VERSION ""

NS_ :

BS_:

BU_: FUSION ABM EPS ESC eBST OCS DataCenter RWS

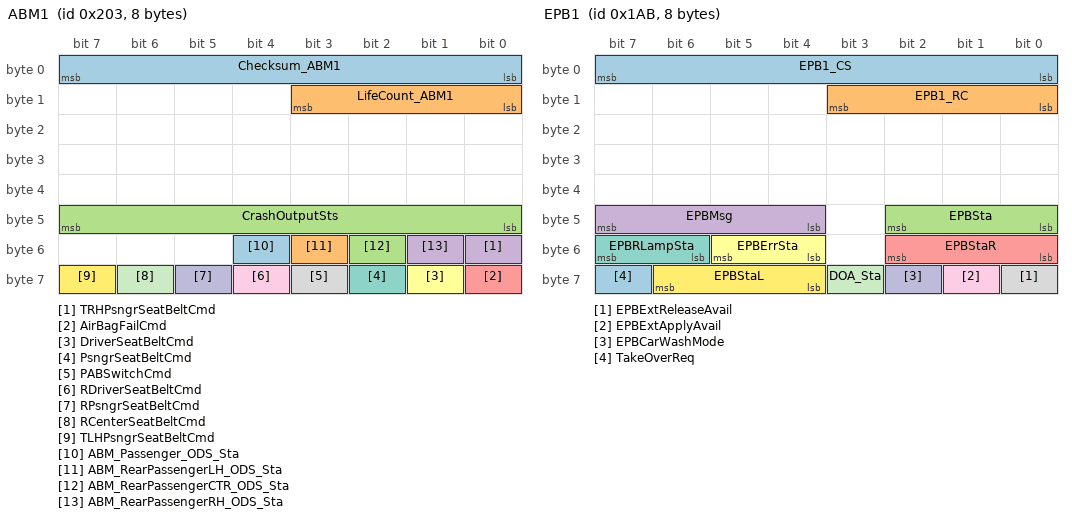
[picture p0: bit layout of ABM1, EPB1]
BO_ 515 ABM1: 8 ABM
 SG_ Checksum_ABM1 : 7|8@0+ (1,0) [0|255] "" FUSION
 SG_ LifeCount_ABM1 : 11|4@0+ (1,0) [0|14] "" FUSION
 SG_ CrashOutputSts : 47|8@0+ (1,0) [0|255] "" FUSION
 SG_ TRHPsngrSeatBeltCmd : 48|1@0+ (1,0) [0|1] "" FUSION
 SG_ AirBagFailCmd : 56|1@0+ (1,0) [0|1] "" FUSION
 SG_ DriverSeatBeltCmd : 57|1@0+ (1,0) [0|1] "" FUSION
 SG_ PsngrSeatBeltCmd : 58|1@0+ (1,0) [0|1] "" FUSION
 SG_ PABSwitchCmd : 59|1@0+ (1,0) [0|1] "" FUSION
 SG_ RDriverSeatBeltCmd : 60|1@0+ (1,0) [0|1] "" FUSION
 SG_ RPsngrSeatBeltCmd : 61|1@0+ (1,0) [0|1] "" FUSION
 SG_ RCenterSeatBeltCmd : 62|1@0+ (1,0) [0|1] "" FUSION
 SG_ TLHPsngrSeatBeltCmd : 63|1@0+ (1,0) [0|1] "" FUSION
 SG_ ABM_Passenger_ODS_Sta : 52|1@0+ (1,0) [0|1] "" FUSION
 SG_ ABM_RearPassengerLH_ODS_Sta : 51|1@0+ (1,0) [0|1] "" FUSION
 SG_ ABM_RearPassengerCTR_ODS_Sta : 50|1@0+ (1,0) [0|1] "" FUSION
 SG_ ABM_RearPassengerRH_ODS_Sta : 49|1@0+ (1,0) [0|1] "" FUSION

BO_ 1585 DiagRespFromABM: 8 ABM
 SG_ DiagRespFromABM : 7|64@0+ (1,0) [0|0] "" FUSION

BO_ 391 EPS1: 16 EPS
 SG_ EPS_CS : 7|8@0+ (1,0) [0|255] "" FUSION
 SG_ EPS_RC : 11|4@0+ (1,0) [0|14] "" FUSION
 SG_ EPS_TOI_Dis_R : 16|4@0+ (1,0) [0|15] "" FUSION
 SG_ DriIntend : 18|2@0+ (1,0) [0|2] "" FUSION
 SG_ EPS_AOI_Control : 20|2@0+ (1,0) [0|3] "" FUSION
 SG_ EPS_TOI_Activation : 21|1@0+ (1,0) [0|1] "" FUSION
 SG_ EPS_TOI_Unavailable : 22|1@0+ (1,0) [0|1] "" FUSION
 SG_ EPS_TOI_Fault : 23|1@0+ (1,0) [0|1] "" FUSION
 SG_ SAS_V : 24|1@0+ (1,0) [0|1] "" FUSION
 SG_ EPS_AOI_Dis_R : 28|4@0+ (1,0) [0|15] "" FUSION
 SG_ SAS_Speed : 39|8@0+ (4,0) [0|1020] "Deg/s" FUSION
 SG_ SAS_Angle : 47|16@0+ (0.1,-900) [-900|900] "Deg" FUSION
 SG_ Steering_Torque : 58|11@0+ (0.01,-10) [-10|10] "Nm" FUSION
 SG_ EPS_Pwr_Limit_V : 59|1@0+ (1,0) [0|1] "" FUSION
 SG_ Steering_Torque_V : 60|1@0+ (1,0) [0|1] "" FUSION
 SG_ EPS_Pwr_Consumpt_V : 61|1@0+ (1,0) [0|1] "" FUSION
 SG_ SAS_Speed_Valid : 62|1@0+ (1,0) [0|1] "" FUSION
 SG_ SAS_CAL : 63|1@0+ (1,0) [0|1] "" FUSION
 SG_ EPS_VOL : 79|8@0+ (0.1,0) [0|25.5] "V" FUSION
 SG_ EPS_Temp : 87|8@0+ (1,-100) [-100|155] "Deg^C" FUSION
 SG_ EPS_Pwr_Limit : 88|9@0+ (0.5,0) [0|135] "A" FUSION
 SG_ EPS_LDW_Activation : 90|2@0+ (1,0) [0|3] "" FUSION
 SG_ EPS_LDW_Unavailable : 91|1@0+ (1,0) [0|1] "" FUSION
 SG_ EPS_VOL_V : 92|1@0+ (1,0) [0|1] "" FUSION
 SG_ EPS_Temp_V : 93|1@0+ (1,0) [0|1] "" FUSION
 SG_ EpasFailed : 95|2@0+ (1,0) [0|2] "" FUSION
 SG_ EPS_Pwr_Consumpt : 104|9@0+ (0.5,0) [0|135] "A" FUSION
 SG_ EPS_ESABoostOut_Trq : 111|6@0+ (0.1,-3) [-3|3] "" FUSION
 SG_ EPS_ESAInpBoost_Sta : 105|1@0+ (1,0) [0|1] "" FUSION
 SG_ EPS_DMSMode_Sta : 123|4@0+ (1,0) [0|15] "" FUSION

BO_ 338 ESC1: 32 ESC
 SG_ ESC1_CS : 7|8@0+ (1,0) [0|255] "" FUSION
 SG_ ESC1_RC : 11|4@0+ (1,0) [0|14] "" FUSION
 SG_ VehSpeed : 23|12@0+ (0.125,0) [0|255.875] "km/h" FUSION
 SG_ RF_WhlRotDir : 25|2@0+ (1,0) [0|3] "" FUSION
 SG_ RF_PulseCount_V : 26|1@0+ (1,0) [0|1] "" FUSION
 SG_ Fr_PTCS_Active : 27|1@0+ (1,0) [0|1] "" FUSION
 SG_ FrntAxlTrqReq_Drv : 39|16@0+ (0.5,-5300) [0|5300] "Nm" FUSION
 SG_ RearAxlTrqReq_Drv : 55|16@0+ (0.5,-5300) [0|5300] "Nm" FUSION
 SG_ RF_PulseCount : 71|8@0+ (1,0) [0|255] "" FUSION
 SG_ RF_RawWhlSpeed : 79|12@0+ (0.0625,0) [0|255.9375] "km/h" FUSION
 SG_ LF_WhlRotDir : 81|2@0+ (1,0) [0|3] "" FUSION
 SG_ LF_PulseCount_V : 82|1@0+ (1,0) [0|1] "" FUSION
 SG_ RF_RawWhlSpeed_V : 83|1@0+ (1,0) [0|1] "" FUSION
 SG_ LF_PulseCount : 95|8@0+ (1,0) [0|255] "" FUSION
 SG_ LF_RawWhlSpeed : 103|12@0+ (0.0625,0) [0|255.9375] "km/h" FUSION
 SG_ RR_WhlRotDir : 105|2@0+ (1,0) [0|3] "" FUSION
 SG_ LF_RawWhlSpeed_V : 106|1@0+ (1,0) [0|1] "" FUSION
 SG_ RR_PulseCount_V : 107|1@0+ (1,0) [0|1] "" FUSION
 SG_ RR_PulseCount : 119|8@0+ (1,0) [0|255] "" FUSION
 SG_ RR_RawWhlSpeed : 123|12@0+ (0.0625,0) [0|255.9375] "km/h" FUSION
 SG_ LR_WhlRotDir : 125|2@0+ (1,0) [0|3] "" FUSION
 SG_ RR_RawWhlSpeed_V : 126|1@0+ (1,0) [0|1] "" FUSION
 SG_ LR_PulseCount_V : 127|1@0+ (1,0) [0|1] "" FUSION
 SG_ LR_PulseCount : 143|8@0+ (1,0) [0|255] "" FUSION
 SG_ LR_RawWhlSpeed : 147|12@0+ (0.0625,0) [0|255.9375] "km/h" FUSION
 SG_ ESC_OFF_Status : 149|2@0+ (1,0) [0|2] "" FUSION
 SG_ ESC_BeepReq : 150|1@0+ (1,0) [0|1] "" FUSION
 SG_ LR_RawWhlSpeed_V : 151|1@0+ (1,0) [0|1] "" FUSION
 SG_ SystemVoltage : 167|8@0+ (0.08,0) [0|20.32] "V" FUSION
 SG_ TCS_Failed : 168|1@0+ (1,0) [0|1] "" FUSION
 SG_ ESC_Failed : 169|1@0+ (1,0) [0|1] "" FUSION
 SG_ HBB_Failed : 170|1@0+ (1,0) [0|1] "" FUSION
 SG_ PBA_Failed : 171|1@0+ (1,0) [0|1] "" FUSION
 SG_ HSA_Failed : 172|1@0+ (1,0) [0|1] "" FUSION
 SG_ AVH_Failed : 173|1@0+ (1,0) [0|1] "" FUSION
 SG_ HDD_Failed : 174|1@0+ (1,0) [0|1] "" FUSION
 SG_ Rr_PTCS_Active : 175|1@0+ (1,0) [0|1] "" FUSION
 SG_ HSA_Active : 176|1@0+ (1,0) [0|1] "" FUSION
 SG_ AVH_Active : 177|1@0+ (1,0) [0|1] "" FUSION
 SG_ Amber_WnlmpSta : 178|1@0+ (1,0) [0|1] "" FUSION
 SG_ BTCS_Active : 179|1@0+ (1,0) [0|1] "" FUSION
 SG_ ESS_Active : 180|1@0+ (1,0) [0|1] "" FUSION
 SG_ HDD_Active : 181|1@0+ (1,0) [0|1] "" FUSION
 SG_ EBD_Failed : 182|1@0+ (1,0) [0|1] "" FUSION
 SG_ ABS_Failed : 183|1@0+ (1,0) [0|1] "" FUSION
 SG_ ESC_WnlmpSta : 185|2@0+ (1,0) [0|2] "" FUSION
 SG_ EBD_Active : 186|1@0+ (1,0) [0|1] "" FUSION
 SG_ ABS_Active : 187|1@0+ (1,0) [0|1] "" FUSION
 SG_ TCS_Active : 188|1@0+ (1,0) [0|1] "" FUSION
 SG_ ESC_Active : 189|1@0+ (1,0) [0|1] "" FUSION
 SG_ HBB_Active : 190|1@0+ (1,0) [0|1] "" FUSION
 SG_ PBA_Active : 191|1@0+ (1,0) [0|1] "" FUSION
 SG_ GRADE : 199|8@0+ (0.354331,-45) [-45|45] "Deg" FUSION
 SG_ Red_WnlmpSta : 205|1@0+ (1,0) [0|1] "" FUSION
 SG_ ABS_WnlmpSta : 206|1@0+ (1,0) [0|1] "" FUSION
 SG_ ESC_Off_lmpSta : 207|1@0+ (1,0) [0|1] "" FUSION
 SG_ ESC_EstVehSpd : 203|12@0+ (0.0625,0) [0|255.9375] "km/h" FUSION
 SG_ ESC_TSA_Active : 223|1@0+ (1,0) [0|1] "" FUSION
 SG_ ESC_EstVehSpd_V : 204|1@0+ (1,0) [0|1] "" FUSION

BO_ 421 ESC5: 20 ESC
 SG_ ESC5_CS : 7|8@0+ (1,0) [0|255] "" FUSION
 SG_ ESC5_RC : 11|4@0+ (1,0) [0|14] "" FUSION
 SG_ BrkDiscTempSta : 16|1@0+ (1,0) [0|1] "" FUSION
 SG_ ACCAvail : 17|1@0+ (1,0) [0|1] "" FUSION
 SG_ YawRate_V : 18|1@0+ (1,0) [0|1] "" FUSION
 SG_ LatAccel_V : 19|1@0+ (1,0) [0|1] "" FUSION
 SG_ LongAccel_V : 20|1@0+ (1,0) [0|1] "" FUSION
 SG_ MCPressure_V : 21|1@0+ (1,0) [0|1] "" FUSION
 SG_ BrkSw_Sta : 22|1@0+ (1,0) [0|1] "" FUSION
 SG_ BrkSw_V : 23|1@0+ (1,0) [0|1] "" FUSION
 SG_ MCPressure : 27|12@0+ (0.1,-9.7) [-9.7|195] "bar" FUSION
 SG_ ESC_ADAS_Sta : 30|3@0+ (1,0) [0|6] "" FUSION
 SG_ LongAccel : 47|8@0+ (0.01,-1.27) [-1.27|1.27] "G's" FUSION
 SG_ LatAccel : 55|8@0+ (0.01,-1.27) [-1.27|1.27] "G's" FUSION
 SG_ YawRate : 63|16@0+ (0.1,-100) [-100|100] "Deg/s" FUSION
 SG_ ESC_Standstill : 72|1@0+ (1,0) [0|1] "" FUSION
 SG_ DecErrSta : 73|1@0+ (1,0) [0|1] "" FUSION
 SG_ ActBrkLamp_Sta : 74|1@0+ (1,0) [0|1] "" FUSION
 SG_ AEBAvail : 75|1@0+ (1,0) [0|1] "" FUSION
 SG_ BrkPedalPos_Sta : 76|1@0+ (1,0) [0|1] "" FUSION
 SG_ ESC_APS_Sta : 79|3@0+ (1,0) [0|5] "" FUSION
 SG_ Meter_Ind_VehSpeed : 87|12@0+ (0.125,0) [0|300] "km/h" FUSION
 SG_ Fr_RBC_Active : 88|1@0+ (1,0) [0|1] "" FUSION
 SG_ Rr_RBC_Active : 89|1@0+ (1,0) [0|1] "" FUSION
 SG_ RDC_Active : 91|2@0+ (1,0) [0|2] "" FUSION
 SG_ BrkPedalPos : 103|8@0+ (0.4,0) [0|100] "%" FUSION
 SG_ RearAxlTrqReq_Brk : 111|16@0+ (0.5,-5300) [-5300|0] "Nm" FUSION
 SG_ FrntAxlTrqReq_Brk : 127|16@0+ (0.5,-5300) [-5300|0] "Nm" FUSION
 SG_ ESC_DriverBrkOverride : 31|1@0+ (1,0) [0|1] "" FUSION

BO_ 427 EPB1: 8 ESC
 SG_ EPB1_CS : 7|8@0+ (1,0) [0|255] "" FUSION
 SG_ EPB1_RC : 11|4@0+ (1,0) [0|14] "" FUSION
 SG_ EPBSta : 42|3@0+ (1,0) [0|4] "" FUSION
 SG_ EPBMsg : 47|4@0+ (1,0) [0|12] "" FUSION
 SG_ EPBStaR : 50|3@0+ (1,0) [0|7] "" FUSION
 SG_ EPBErrSta : 53|2@0+ (1,0) [0|2] "" FUSION
 SG_ EPBRLampSta : 55|2@0+ (1,0) [0|2] "" FUSION
 SG_ EPBExtReleaseAvail : 56|1@0+ (1,0) [0|1] "" FUSION
 SG_ EPBExtApplyAvail : 57|1@0+ (1,0) [0|1] "" FUSION
 SG_ EPBCarWashMode : 58|1@0+ (1,0) [0|1] "" FUSION
 SG_ DOA_Sta : 59|1@0+ (1,0) [0|1] "" FUSION
 SG_ EPBStaL : 62|3@0+ (1,0) [0|7] "" FUSION
 SG_ TakeOverReq : 63|1@0+ (1,0) [0|1] "" FUSION

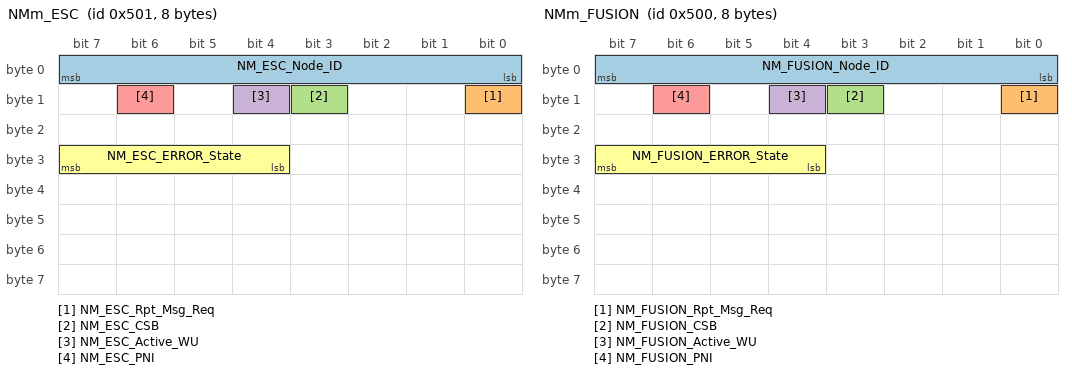
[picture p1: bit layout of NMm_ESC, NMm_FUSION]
BO_ 1281 NMm_ESC: 8 ESC
 SG_ NM_ESC_Node_ID : 7|8@0+ (1,0) [0|127] "" FUSION
 SG_ NM_ESC_Rpt_Msg_Req : 8|1@0+ (1,0) [0|1] "" FUSION
 SG_ NM_ESC_CSB : 11|1@0+ (1,0) [0|1] "" FUSION
 SG_ NM_ESC_Active_WU : 12|1@0+ (1,0) [0|1] "" FUSION
 SG_ NM_ESC_PNI : 14|1@0+ (1,0) [0|1] "" FUSION
 SG_ NM_ESC_ERROR_State : 31|4@0+ (1,0) [0|8] "" FUSION

BO_ 278 FD1_VCU1: 12 FUSION
 SG_ PrkReqValid : 4|1@0+ (1,0) [0|1] "" ESC
 SG_ P_Button_Sta : 7|2@0+ (1,0) [0|3] "" ESC
 SG_ CC_Crl_Sta : 28|3@0+ (1,0) [0|7] "" Vector__XXX
 SG_ MSA_Crl_Sta : 31|3@0+ (1,0) [0|7] "" Vector__XXX
 SG_ ShiftGearPosn : 38|3@0+ (1,0) [0|7] "" ABM,ESC,eBST
 SG_ PrkReq : 45|1@0+ (1,0) [0|1] "" ESC
 SG_ XWDMode : 57|2@0+ (1,0) [0|2] "" ESC
 SG_ LVPwrSta : 58|1@0+ (1,0) [0|1] "" Vector__XXX
 SG_ HVPwrSta : 59|1@0+ (1,0) [0|1] "" Vector__XXX
 SG_ PwrSta : 63|3@0+ (1,0) [0|7] "" ABM,EPS,ESC,eBST,OCS
 SG_ Eng_AGSCloseSta : 65|1@0+ (1,0) [0|1] "" Vector__XXX
 SG_ Eng_PwrLockSta : 67|2@0+ (1,0) [0|2] "" Vector__XXX
 SG_ Eng_CoastDwSta : 69|2@0+ (1,0) [0|2] "" Vector__XXX
 SG_ Eng_ActvDmpDisabSta : 71|2@0+ (1,0) [0|2] "" Vector__XXX
 SG_ VehMalfunLevel : 74|3@0+ (1,0) [0|5] "" Vector__XXX

BO_ 340 FD1_VCU2: 16 FUSION
 SG_ CS_VCU2_CAN1 : 7|8@0+ (1,0) [0|255] "" Vector__XXX
 SG_ RC_VCU2_CAN1 : 11|4@0+ (1,0) [0|14] "" Vector__XXX
 SG_ Fr_DriverTq : 23|16@0+ (0.5,-5300) [-5300|5300] "Nm" ESC
 SG_ Rr_DriverTq : 39|16@0+ (0.5,-5300) [-5300|5300] "Nm" ESC
 SG_ AccPedal_Override : 54|1@0+ (1,0) [0|1] "" Vector__XXX
 SG_ ACC_CtrlAvail : 55|1@0+ (1,0) [0|1] "" Vector__XXX
 SG_ VehActPwr : 87|24@0+ (1,-600000) [-600000|600000] "W" Vector__XXX
 SG_ DriverTq : 111|16@0+ (1,-4300) [-4300|4300] "Nm" Vector__XXX
 SG_ ActAPSPosn : 127|8@0+ (0.394,0) [0|100.076] "%" ABM,ESC

BO_ 1280 NMm_FUSION: 8 FUSION
 SG_ NM_FUSION_Node_ID : 7|8@0+ (1,0) [0|127] "" ESC,eBST
 SG_ NM_FUSION_Rpt_Msg_Req : 8|1@0+ (1,0) [0|1] "" ESC,eBST
 SG_ NM_FUSION_CSB : 11|1@0+ (1,0) [0|1] "" ESC,eBST
 SG_ NM_FUSION_Active_WU : 12|1@0+ (1,0) [0|1] "" ESC,eBST
 SG_ NM_FUSION_PNI : 14|1@0+ (1,0) [0|1] "" ESC,eBST
 SG_ NM_FUSION_ERROR_State : 31|4@0+ (1,0) [0|8] "" ESC,eBST

BO_ 1713 DiagPhysReqToABM: 8 FUSION
 SG_ DiagPhysReqToABM : 7|64@0+ (1,0) [0|0] "" ABM

BO_ 2000 DiagFuncReqFT: 8 FUSION
 SG_ DiagFuncReqFT : 7|64@0+ (1,0) [0|0] "" ABM,EPS,ESC,eBST

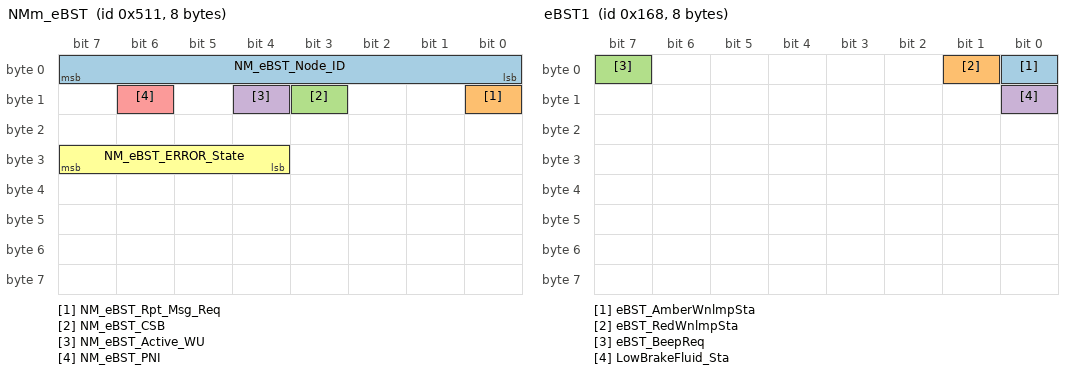
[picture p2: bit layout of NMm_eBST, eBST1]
BO_ 1297 NMm_eBST: 8 eBST
 SG_ NM_eBST_Node_ID : 7|8@0+ (1,0) [0|127] "" FUSION
 SG_ NM_eBST_Rpt_Msg_Req : 8|1@0+ (1,0) [0|1] "" FUSION
 SG_ NM_eBST_CSB : 11|1@0+ (1,0) [0|1] "" FUSION
 SG_ NM_eBST_Active_WU : 12|1@0+ (1,0) [0|1] "" FUSION
 SG_ NM_eBST_PNI : 14|1@0+ (1,0) [0|1] "" FUSION
 SG_ NM_eBST_ERROR_State : 31|4@0+ (1,0) [0|8] "" FUSION

BO_ 1168 IVI1: 20 FUSION
 SG_ VehACModReq : 23|3@0+ (1,0) [0|7] "" Vector__XXX
 SG_ FCP_FrEvt_BtnACMaxReq : 20|1@0+ (1,0) [0|1] "" Vector__XXX
 SG_ FCP_FrEvt_BtnACReq : 19|1@0+ (1,0) [0|1] "" Vector__XXX
 SG_ FCP_FrEvt_BtnAutoReq : 18|1@0+ (1,0) [0|1] "" Vector__XXX
 SG_ FCP_MidEvt_BtnAutoReq : 17|1@0+ (1,0) [0|1] "" Vector__XXX
 SG_ FCP_FrEvt_BtnSyncReq : 16|1@0+ (1,0) [0|1] "" Vector__XXX
 SG_ OTA_DL_Req : 31|1@0+ (1,0) [0|1] "" Vector__XXX
 SG_ OTA_SuspendDL_Req : 30|1@0+ (1,0) [0|1] "" Vector__XXX
 SG_ OTA_UpdStart_Req : 29|1@0+ (1,0) [0|1] "" Vector__XXX
 SG_ IVI_OTA_Upd_Sta : 28|2@0+ (1,0) [0|3] "" Vector__XXX
 SG_ OTA_CancelDL_Req : 26|1@0+ (1,0) [0|1] "" Vector__XXX
 SG_ SmartEco_Mode_SW : 25|1@0+ (1,0) [0|1] "" Vector__XXX
 SG_ LINKtoDrive : 24|1@0+ (1,0) [0|1] "" Vector__XXX
 SG_ Upd_Countdown_Skip : 39|1@0+ (1,0) [0|1] "" Vector__XXX
 SG_ Upd_Countdown_Cancel : 38|1@0+ (1,0) [0|1] "" Vector__XXX
 SG_ AmbLightColorSet : 46|7@0+ (1,0) [0|127] "" Vector__XXX
 SG_ Sched_OTA_wake : 47|1@0+ (1,0) [0|1] "" Vector__XXX
 SG_ UserSet : 71|3@0+ (1,0) [0|7] "" Vector__XXX
 SG_ AmbLightBrightnessSet : 54|7@0+ (1,0) [0|127] "" Vector__XXX
 SG_ Sched_Chg_Day_Set : 62|1@0+ (1,0) [0|1] "" Vector__XXX
 SG_ Re_Radio_Sta : 63|1@0+ (1,0) [0|1] "" Vector__XXX
 SG_ Sched_Chg_St_Time_Min : 61|6@0+ (1,0) [0|59] "MINUTE" Vector__XXX
 SG_ A2B_Node_sta : 55|1@0+ (1,0) [0|1] "" Vector__XXX
 SG_ Sched_Chg_St_Time_HR : 68|5@0+ (1,0) [0|23] "HOUR" Vector__XXX
 SG_ IVI_Located_STA : 79|2@0+ (1,0) [0|3] "" Vector__XXX
 SG_ Sched_Chg_End_Time_Min : 77|6@0+ (1,0) [0|59] "MINUTE" Vector__XXX
 SG_ OTA_CompNTFY_Pres : 86|1@0+ (1,0) [0|1] "" Vector__XXX
 SG_ BrkAbn_GoReady_SW : 85|1@0+ (1,0) [0|1] "" Vector__XXX
 SG_ Sched_Chg_End_Time_HR : 84|5@0+ (1,0) [0|23] "HOUR" Vector__XXX
 SG_ IVI_Time_Check : 95|8@0+ (1,0) [0|255] "" Vector__XXX
 SG_ PW_CONTINUE_USE : 103|1@0+ (1,0) [0|1] "" Vector__XXX
 SG_ PW_CLOSE_IMD : 102|1@0+ (1,0) [0|1] "" Vector__XXX
 SG_ IVI_Time_Second : 101|6@0+ (1,0) [0|63] "SECOND" ABM,EPS,ESC,eBST
 SG_ IVI_Time_Minute : 109|6@0+ (1,0) [0|63] "MINUTE" ABM,EPS,ESC,eBST
 SG_ IVI_Time_Day : 116|5@0+ (1,0) [0|31] "DAY" ABM,EPS,ESC,eBST
 SG_ IVI_Time_Hour : 124|5@0+ (1,0) [0|31] "HOUR" ABM,EPS,ESC,eBST
 SG_ IVI_Time_Month : 131|4@0+ (1,0) [0|12] "MONTH" ABM,EPS,ESC,eBST
 SG_ IVI_Time_Year : 142|7@0+ (1,2000) [2000|2127] "YEAR" Vector__XXX
 SG_ mFRD_link_Sta : 87|1@0+ (1,0) [0|1] "" Vector__XXX
 SG_ AmbLight_SW : 36|1@0+ (1,0) [0|1] "" Vector__XXX
 SG_ AmbLight_DimInDark_SW : 35|1@0+ (1,0) [0|1] "" Vector__XXX
 SG_ AmbLight_WlcmLight_SW : 34|1@0+ (1,0) [0|1] "" Vector__XXX
 SG_ AmbLigh_LowBatAlert_SW : 33|1@0+ (1,0) [0|1] "" Vector__XXX
 SG_ AmbLigh_SafetyAlert_SW : 32|1@0+ (1,0) [0|1] "" Vector__XXX
 SG_ OpenDrOpenWdo_SW : 37|1@0+ (1,0) [0|1] "" Vector__XXX
 SG_ IVI_LinkKey_Sta : 135|4@0+ (1,0) [0|15] "" Vector__XXX
 SG_ IVI_CreateAccReq_Sta : 127|3@0+ (1,0) [0|7] "" Vector__XXX
 SG_ IVI_DelAccReq_Sta : 119|3@0+ (1,0) [0|7] "" Vector__XXX
 SG_ IVI_LinkAcc_Sta : 146|3@0+ (1,0) [0|7] "" Vector__XXX
 SG_ IVI_LinkAccReq_Sta : 143|1@0+ (1,0) [0|1] "" Vector__XXX
 SG_ IVI_FrTrunk_UnlockReq_Sta : 147|1@0+ (1,0) [0|1] "" Vector__XXX
 SG_ IVI_CLWin_LockDoorSW_Sta : 148|1@0+ (1,0) [0|1] "" Vector__XXX
 SG_ IVI_Lock_SoundSW_Sta : 149|1@0+ (1,0) [0|1] "" Vector__XXX
 SG_ IVI_SWC_VibMode_Sta : 111|2@0+ (1,0) [0|3] "" Vector__XXX
 SG_ IVI_DMS_SW_Sta : 150|1@0+ (1,0) [0|1] "" Vector__XXX
 SG_ IVI_AirRefresh_ByDMS_Sta : 151|1@0+ (1,0) [0|1] "" Vector__XXX
 SG_ IVI_QuickRefresh_Sta : 159|1@0+ (1,0) [0|1] "" Vector__XXX
 SG_ IVI_HMI_Undefined_Sta : 158|3@0+ (1,0) [0|7] "" Vector__XXX
 SG_ IVI_AutoTheme_But_Sta : 154|1@0+ (1,0) [0|1] "" Vector__XXX
 SG_ IVI_NAVI_Foreground_Sta : 155|1@0+ (1,0) [0|1] "" Vector__XXX
 SG_ IVI_sigScreenReq_Sta : 152|1@0+ (1,0) [0|1] "" Vector__XXX
 SG_ IVI_DSEAT_anti_set_Sta : 153|1@0+ (1,0) [0|1] "" Vector__XXX
 SG_ IVI_MirrorFolded_SW_Sta : 7|1@0+ (1,0) [0|1] "" Vector__XXX
 SG_ IVI_WPTC_SW_Sta : 6|1@0+ (1,0) [0|1] "" Vector__XXX
 SG_ IVI_Driving_Lock_SW_Sta : 5|1@0+ (1,0) [0|1] "" Vector__XXX
 SG_ IVI_Stopping_Unlock_SW_Sta : 4|1@0+ (1,0) [0|1] "" Vector__XXX
 SG_ IVI_SilentChrg_Alert_Sta : 3|1@0+ (1,0) [0|1] "" Vector__XXX
 SG_ IVI_WirelessCharge_Cmd : 2|1@0+ (1,0) [0|1] "" Vector__XXX
 SG_ IVI_Theme_Sta : 1|2@0+ (1,0) [0|3] "" Vector__XXX
 SG_ IVI_EPS_Force_Cmd : 15|2@0+ (1,0) [0|3] "" Vector__XXX
 SG_ IVI_DSEAT_StopKeepMove_Sta : 13|2@0+ (1,0) [0|3] "" Vector__XXX
 SG_ IVI_AutoWipHSpdSW_Cmd : 11|1@0+ (1,0) [0|1] "" Vector__XXX
 SG_ IVI_DSEAT_entryfun_set_Sta : 10|1@0+ (1,0) [0|1] "" Vector__XXX

BO_ 1569 DiagRespFromEPS: 8 EPS
 SG_ DiagRespFromEPS : 7|64@0+ (1,0) [0|0] "" FUSION

BO_ 370 VMC_FCM1: 32 FUSION
 SG_ VMC_FCM1_Checksum : 7|8@0+ (1,0) [0|255] "" EPS,ESC
 SG_ VMC_FCM1_LifeCount : 11|4@0+ (1,0) [0|14] "" EPS,ESC
 SG_ VMC_FCM_LKA_TOIAct : 23|8@0+ (1,0) [0|1] "" EPS
 SG_ VMC_FCM_LKA_StrToqReq : 26|11@0+ (0.008,-8) [-8|8] "Nm" EPS
 SG_ VMC_AEB_VehHoldReq : 27|1@0+ (1,0) [0|1] "" ESC
 SG_ VMC_FCM_LKA_TOIFault : 28|1@0+ (1,0) [0|1] "" EPS
 SG_ VMC_FCM_LDW_Fault : 29|1@0+ (1,0) [0|1] "" EPS
 SG_ VMC_FCM_LDW_Request : 31|2@0+ (1,0) [0|3] "" EPS
 SG_ VMC_ACC_RequiredAccel : 40|9@0+ (0.05,-15) [-15|10.55] "m/s^2" ESC
 SG_ VMC_ADAS_AEBReq : 43|3@0+ (1,0) [0|3] "" ESC
 SG_ VMC_ADAS_FaultSta : 44|1@0+ (1,0) [0|1] "" ESC
 SG_ VMC_ADAS_DBSReq : 46|2@0+ (1,0) [0|3] "" ESC
 SG_ VMC_ACC_VehHoldReq : 47|1@0+ (1,0) [0|1] "" ESC
 SG_ VMC_ACC_ComfortBandUpper : 56|9@0+ (0.05,-15) [-15|10.55] "m/s^2" ESC
 SG_ VMC_ACC_JerkUpperLInit : 63|7@0+ (0.1,-6) [-6|6.7] "m/s^3" ESC
 SG_ VMC_ACC_ComfortBandLower : 72|9@0+ (0.05,-15) [-15|10.55] "m/s^2" ESC
 SG_ VMC_ACC_JerkLowerLInit : 79|7@0+ (0.1,-6) [-6|6.7] "m/s^3" ESC
 SG_ VMC_ADAS_ACC_Sta : 95|3@0+ (1,0) [0|7] "" ESC
 SG_ VMC_ADAS_AEB_Sta : 92|3@0+ (1,0) [0|7] "" Vector__XXX
 SG_ FDC_VMC_DrInpTqBstGn : 119|8@0+ (0.4,0) [0|102] "%" EPS
 SG_ FDC_VMC_AngCtrlTqWtGn : 111|8@0+ (0.4,0) [0|102] "%" EPS
 SG_ FDC_VMC_MaxAngCtrlOutTqLim : 88|9@0+ (0.1,0) [0|51.1] "Nm" EPS
 SG_ FDC_VMC_DrInpTqBstAct : 89|1@0+ (1,0) [0|1] "" EPS
 SG_ FDC_VMC_DMSMode_Cmd : 123|4@0+ (1,0) [0|15] "" EPS

BO_ 383 FD1_VMC1: 24 FUSION
 SG_ FeatSetSpdFinal_raw32 : 47|8@0+ (1,0) [0|255] "" Vector__XXX
 SG_ MeterIndSpeed_raw32 : 55|8@0+ (1,0) [0|255] "" EPS
 SG_ DISCReqAcc : 56|9@0+ (0.05,-15) [-15|10.55] "m/s^2" Vector__XXX
 SG_ FeatArbitrFinal : 59|3@0+ (1,0) [0|6] "" Vector__XXX
 SG_ DISC_ButtSta : 60|1@0+ (1,0) [0|1] "" Vector__XXX
 SG_ SPD2ACCAct : 61|1@0+ (1,0) [0|1] "" Vector__XXX
 SG_ DISC_DISCTurn : 62|1@0+ (1,0) [0|1] "" Vector__XXX
 SG_ AccCalcuPID : 72|9@0+ (0.05,-15) [-15|10.55] "m/s^2" Vector__XXX
 SG_ DISC_DISCTargetSpd : 91|12@0+ (0.125,0) [0|255.875] "km/h" Vector__XXX
 SG_ FeatArbitrSta : 130|3@0+ (1,0) [0|6] "" Vector__XXX
 SG_ DISC_Sta : 132|2@0+ (1,0) [0|3] "" Vector__XXX
 SG_ CCMSA_SpdWar : 133|1@0+ (1,0) [0|1] "" Vector__XXX
 SG_ LatAccCtrl : 134|1@0+ (1,0) [0|1] "" Vector__XXX
 SG_ LateralCtrl : 135|1@0+ (1,0) [0|1] "" Vector__XXX
 SG_ LimitPCT : 142|7@0+ (1,0) [0|100] "%" Vector__XXX
 SG_ SafetyCtrl : 143|1@0+ (1,0) [0|1] "" Vector__XXX
 SG_ JerkPCT : 150|7@0+ (1,0) [0|100] "%" Vector__XXX
 SG_ SingleWhlSlipRatioCtrl : 151|1@0+ (1,0) [0|1] "" Vector__XXX
 SG_ VMC_VCU_CC_Crl_Sta : 154|3@0+ (1,0) [0|6] "" Vector__XXX
 SG_ VMC_AEBCtrlAvail : 155|1@0+ (1,0) [0|1] "" Vector__XXX
 SG_ VMC_CCCtrlAvail : 156|1@0+ (1,0) [0|1] "" Vector__XXX
 SG_ VMC_MSACtrlAvail : 157|1@0+ (1,0) [0|1] "" Vector__XXX
 SG_ RearWhlSlipRatioCtrl : 158|1@0+ (1,0) [0|1] "" Vector__XXX
 SG_ FrontRearSlipRatioCtrl : 159|1@0+ (1,0) [0|1] "" Vector__XXX
 SG_ VMC_VCU_ACC_CtrlAvail : 160|1@0+ (1,0) [0|1] "" Vector__XXX
 SG_ VMC_VCU_AccPedal_Override : 161|1@0+ (1,0) [0|1] "" Vector__XXX
 SG_ VMC_VCU_MSA_Crl_Sta : 165|3@0+ (1,0) [0|6] "" Vector__XXX
 SG_ VMC_VCU_APSCtrlAvail_flg : 166|1@0+ (1,0) [0|1] "" Vector__XXX
 SG_ VMC_ACCCtrlAvail : 167|1@0+ (1,0) [0|1] "" Vector__XXX
 SG_ TimeGapCalcu : 175|8@0+ (0.1,0) [0|25.5] "SECOND" Vector__XXX
 SG_ FeatReqSpd : 178|11@0+ (0.125,0) [0|255.75] "km/h" Vector__XXX
 SG_ VehicleSpeed_kph : 111|12@0+ (0.125,0) [0|255.875] "km/h" Vector__XXX
 SG_ VehicleSpeed_mph : 115|12@0+ (0.125,0) [0|255.875] "km/h" Vector__XXX

BO_ 568 FD1_APS3: 16 FUSION
 SG_ APS3_checksum : 7|8@0+ (1,0) [0|255] "" ESC
 SG_ APS3_LifeCount : 11|4@0+ (1,0) [0|14] "" ESC
 SG_ APSOpenPTG : 16|1@0+ (1,0) [0|1] "" Vector__XXX
 SG_ CAAS_Sta : 19|3@0+ (1,0) [0|7] "" Vector__XXX
 SG_ APS_Req : 22|3@0+ (1,0) [0|7] "" ESC
 SG_ APS_DecReq_A : 23|1@0+ (1,0) [0|1] "" ESC
 SG_ APS_DecReq : 31|8@0+ (0.1,0) [0|25.4] "m/s^2" ESC
 SG_ FDC_VMC_APS_Angle_Target : 39|16@0+ (0.1,-900) [-900|900] "Deg" EPS
 SG_ APS_Sta_System : 50|3@0+ (1,0) [0|7] "" ESC
 SG_ FDC_VMC_APS_V_Rq_EPS_Ctrl : 51|1@0+ (1,0) [0|1] "" EPS
 SG_ SPTG_Sta : 54|3@0+ (1,0) [0|7] "" Vector__XXX
 SG_ SPTGDet : 55|1@0+ (1,0) [0|1] "" Vector__XXX
 SG_ FDC_VMC_APS_Rq_EPS_Ctrl : 56|1@0+ (1,0) [0|1] "" EPS
 SG_ FDC_RAPS_PwrReq_Cmd : 70|3@0+ (1,0) [0|7] "" Vector__XXX
 SG_ FDC_RAPS_BCMLamp_Cmd : 66|3@0+ (1,0) [0|7] "" Vector__XXX
 SG_ FDC_RAPS_PwrReqAvail_Sta : 71|1@0+ (1,0) [0|1] "" Vector__XXX
 SG_ FDC_RAPS_BCMLockReq_Cmd : 67|1@0+ (1,0) [0|1] "" Vector__XXX
 SG_ FDC_APS_CaasCtrlAvail_Sta : 59|1@0+ (1,0) [0|1] "" Vector__XXX
 SG_ FDC_APS_CaasVMCReqA_Cmd : 58|1@0+ (1,0) [0|1] "" Vector__XXX
 SG_ FDC_APS_VMCReqA_Cmd : 77|1@0+ (1,0) [0|1] "" Vector__XXX
 SG_ FDC_APS_SpeedReq_Cmd : 75|12@0+ (0.125,0) [0|15] "km/h" Vector__XXX
 SG_ FDC_APS_ShftPosnReq_Cmd : 62|3@0+ (1,0) [0|7] "" Vector__XXX
 SG_ FDC_APS_CaasActive_Sta : 57|1@0+ (1,0) [0|1] "" Vector__XXX
 SG_ FDC_APS_CtrlAvail_Sta : 63|1@0+ (1,0) [0|1] "" Vector__XXX
 SG_ FDC_APS_Active_Sta : 76|1@0+ (1,0) [0|1] "" Vector__XXX
 SG_ FDC_VCU_RAPSErrLv3_Flg : 95|1@0+ (1,0) [0|1] "" Vector__XXX
 SG_ FDC_VCU_RAPSErrLv2_Flg : 79|1@0+ (1,0) [0|1] "" Vector__XXX
 SG_ FDC_RAPS_ErrLv1_Flg : 78|1@0+ (1,0) [0|1] "" Vector__XXX

BO_ 1697 DiagPhysReqToEPS: 8 FUSION
 SG_ DiagPhysReqToEPS : 7|64@0+ (1,0) [0|0] "" EPS

BO_ 1537 DiagRespFromESC: 8 ESC
 SG_ DiagRespFromESC : 7|64@0+ (1,0) [0|0] "" FUSION

BO_ 345 FD1_VCU3: 20 FUSION
 SG_ CS_VCU3_CAN1 : 7|8@0+ (1,0) [0|255] "" ESC,eBST
 SG_ RC_VCU3_CAN1 : 11|4@0+ (1,0) [0|14] "" ESC,eBST
 SG_ Rr_RgnPermSta : 24|1@0+ (1,0) [0|1] "" ESC
 SG_ Fr_RgnPermSta : 25|1@0+ (1,0) [0|1] "" ESC
 SG_ Rr_RgnDecrSta : 26|1@0+ (1,0) [0|1] "" ESC
 SG_ Fr_RgnDecrSta : 27|1@0+ (1,0) [0|1] "" ESC
 SG_ RgnAbnorSta : 28|1@0+ (1,0) [0|1] "" ESC
 SG_ Rr_EDUSpdValid : 29|1@0+ (1,0) [0|1] "" ESC
 SG_ Fr_EDUSpdValid : 30|1@0+ (1,0) [0|1] "" ESC
 SG_ Rr_EDUSpd : 35|12@0+ (1,-2000) [-2000|2000] "RPM" ESC
 SG_ EquivAccPedalSWSta : 38|1@0+ (1,0) [0|1] "" ESC,eBST
 SG_ PTCS_PermSta : 39|1@0+ (1,0) [0|1] "" ESC
 SG_ Rr_EDURealARgnTq : 55|16@0+ (1,-5300) [-5300|5300] "Nm" ESC
 SG_ Rr_EDUAvailBrkRgnTq : 71|16@0+ (0.5,-5300) [-5300|0] "Nm" ESC,eBST
 SG_ Rr_EDURealDrvOrBRgnTq : 87|16@0+ (0.5,-5300) [-5300|5300] "Nm" ESC,eBST
 SG_ Fr_EDUSpd : 99|12@0+ (1,-2000) [-2000|2000] "RPM" ESC
 SG_ Fr_EDUAvailBrkRgnTqValid : 102|1@0+ (1,0) [0|1] "" ESC,eBST
 SG_ Rr_EDUAvailBrkRgnTqValid : 103|1@0+ (1,0) [0|1] "" ESC,eBST
 SG_ Fr_EDURealARgnTq : 119|16@0+ (1,-5300) [-5300|5300] "Nm" ESC
 SG_ Fr_EDUAvailBrkRgnTq : 135|16@0+ (0.5,-5300) [-5300|0] "Nm" ESC,eBST
 SG_ Fr_EDURealDrvOrBRgnTq : 151|16@0+ (0.5,-5300) [-5300|5300] "Nm" ESC,eBST

BO_ 386 FD1_THCM1: 20 FUSION
 SG_ Fr_Coolanttemp : 0|9@0+ (1,-40) [-40|214] "Deg^C" Vector__XXX
 SG_ CCU_ACMaxLampSts : 1|1@0+ (1,0) [0|1] "" Vector__XXX
 SG_ CCU_AutoLampSts : 2|1@0+ (1,0) [0|1] "" Vector__XXX
 SG_ CCU_AutoMidLampSts : 3|1@0+ (1,0) [0|1] "" Vector__XXX
 SG_ CCU_EcoSts : 4|1@0+ (1,0) [0|1] "" Vector__XXX
 SG_ CCU_Dispaly_Request : 5|1@0+ (1,0) [0|1] "" Vector__XXX
 SG_ CCU_ACLampSts : 6|1@0+ (1,0) [0|1] "" Vector__XXX
 SG_ CCU_HEATMaxLampSts : 7|1@0+ (1,0) [0|1] "" Vector__XXX
 SG_ sigWindDirZon3St : 18|3@0+ (1,0) [0|7] "" Vector__XXX
 SG_ CCU_FrtOnOffLampSts : 19|1@0+ (1,0) [0|1] "" Vector__XXX
 SG_ sigWindDirZon1St : 22|3@0+ (1,0) [0|7] "" Vector__XXX
 SG_ CCU_RrOnOffLampSts : 23|1@0+ (1,0) [0|1] "" Vector__XXX
 SG_ sigAirIntenZon3St : 27|4@0+ (1,0) [0|15] "" Vector__XXX
 SG_ sigAirIntenZon1St : 31|4@0+ (1,0) [0|15] "" Vector__XXX
 SG_ sigSetTempZon3St : 37|6@0+ (0.5,17) [17|32] "Deg^C" Vector__XXX
 SG_ sigDfrstSt : 38|1@0+ (1,0) [0|1] "" Vector__XXX
 SG_ CCU_SyncLampSts : 39|1@0+ (1,0) [0|1] "" Vector__XXX
 SG_ sigSetTempZon2St : 45|6@0+ (0.5,17) [17|32] "Deg^C" Vector__XXX
 SG_ sigHvacSt : 46|1@0+ (1,0) [0|1] "" Vector__XXX
 SG_ sigRecircSt : 47|1@0+ (1,0) [0|1] "" Vector__XXX
 SG_ sigSetTempZon1St : 53|6@0+ (0.5,17) [17|32] "Deg^C" Vector__XXX
 SG_ HPThermalRecoveryReq : 55|2@0+ (1,0) [0|1] "" Vector__XXX
 SG_ Fr_Coolantflow : 61|6@0+ (0.25,0) [0|15.75] "L/min" Vector__XXX
 SG_ EDriveMode : 63|2@0+ (1,0) [0|2] "" Vector__XXX
 SG_ sigClmtCmprPwrAct : 71|8@0+ (50,0) [0|12650] "W" Vector__XXX
 SG_ sigCbnPTCPwrAct : 79|8@0+ (50,0) [0|12650] "W" Vector__XXX
 SG_ sigCbnAirT : 87|8@0+ (0.5,-40) [-40|85] "Deg^C" Vector__XXX
 SG_ sigAmbAirT : 95|8@0+ (0.5,-40) [-40|85] "Deg^C" ESC
 SG_ sigCbnSolarRight : 103|8@0+ (5,0) [0|1265] "W" Vector__XXX
 SG_ FD_RecyAuto_Cmd : 111|3@0+ (1,0) [0|7] "" Vector__XXX
 SG_ CabinMode : 115|4@0+ (1,0) [0|15] "" Vector__XXX
 SG_ BatteryMode : 118|3@0+ (1,0) [0|5] "" Vector__XXX
 SG_ sigCbnSolarLeft : 127|8@0+ (5,0) [0|1265] "W" Vector__XXX
 SG_ sigClntTHvBattOut : 135|8@0+ (0.5,-40) [-40|85] "Deg^C" Vector__XXX
 SG_ FD_AGS_Cmd : 143|8@0+ (1,0) [0|255] "" Vector__XXX
 SG_ Rr_Coolanttemp : 144|9@0+ (1,-40) [-40|214] "Deg^C" Vector__XXX
 SG_ Rr_Coolantflow : 150|6@0+ (0.25,0) [0|15.75] "L/min" Vector__XXX

BO_ 534 FD1_BCM1: 16 FUSION
 SG_ BCM_Buzzer_Req : 64|1@0+ (1,0) [0|1] "" Vector__XXX
 SG_ TailgateRemote : 66|2@0+ (1,0) [0|3] "" Vector__XXX
 SG_ RoomLampL : 67|1@0+ (1,0) [0|1] "" Vector__XXX
 SG_ RoomLampH : 68|1@0+ (1,0) [0|1] "" Vector__XXX
 SG_ DimmerEN : 69|1@0+ (1,0) [0|1] "" Vector__XXX
 SG_ BCM_DoorLock_Sta : 70|1@0+ (1,0) [0|1] "" Vector__XXX
 SG_ HornCtrl : 71|1@0+ (1,0) [0|1] "" Vector__XXX
 SG_ Dimmer : 78|7@0+ (1,0) [0|100] "%" Vector__XXX
 SG_ LockSetting : 79|1@0+ (1,0) [0|1] "" Vector__XXX
 SG_ LTurnLP : 80|1@0+ (1,0) [0|1] "" Vector__XXX
 SG_ RTurnLP : 81|1@0+ (1,0) [0|1] "" Vector__XXX
 SG_ AntitheftSta : 83|2@0+ (1,0) [0|3] "" Vector__XXX
 SG_ AntiTheftSeatFold : 84|1@0+ (1,0) [0|1] "" Vector__XXX
 SG_ CrashDetd : 85|1@0+ (1,0) [0|1] "" DataCenter
 SG_ L_APM_WdwEnable : 87|1@0+ (1,0) [0|1] "" Vector__XXX
 SG_ RDRL : 88|1@0+ (1,0) [0|1] "" Vector__XXX
 SG_ ReverseLamp : 89|1@0+ (1,0) [0|1] "" Vector__XXX
 SG_ BrakeLamp : 90|1@0+ (1,0) [0|1] "" Vector__XXX
 SG_ LBSD : 91|1@0+ (1,0) [0|1] "" Vector__XXX
 SG_ RBSD : 92|1@0+ (1,0) [0|1] "" Vector__XXX
 SG_ Fr_FogLamp : 93|1@0+ (1,0) [0|1] "" Vector__XXX
 SG_ Rr_FogLamp : 94|1@0+ (1,0) [0|1] "" Vector__XXX
 SG_ HazardSW : 95|1@0+ (1,0) [0|1] "" Vector__XXX
 SG_ Rr_Wiper : 96|1@0+ (1,0) [0|1] "" Vector__XXX
 SG_ WiperFixMode : 97|1@0+ (1,0) [0|1] "" Vector__XXX
 SG_ WasherCtrl : 99|2@0+ (1,0) [0|3] "" Vector__XXX
 SG_ L_Beam : 100|1@0+ (1,0) [0|1] "" Vector__XXX
 SG_ H_Beam : 101|1@0+ (1,0) [0|1] "" Vector__XXX
 SG_ PosLamp : 102|1@0+ (1,0) [0|1] "" Vector__XXX
 SG_ LDRL : 103|1@0+ (1,0) [0|1] "" Vector__XXX
 SG_ MirrorDefog : 104|1@0+ (1,0) [0|1] "" Vector__XXX
 SG_ Rr_Defog : 105|1@0+ (1,0) [0|1] "" Vector__XXX
 SG_ TrunkRel : 106|1@0+ (1,0) [0|1] "" Vector__XXX
 SG_ TailgateHDSW : 107|1@0+ (1,0) [0|1] "" Vector__XXX
 SG_ MirrorCtrl : 109|2@0+ (1,0) [0|3] "" Vector__XXX
 SG_ Fr_Wiper_H : 110|1@0+ (1,0) [0|1] "" Vector__XXX
 SG_ Fr_Wiper_L : 111|1@0+ (1,0) [0|1] "" Vector__XXX
 SG_ CTDCtrl : 113|2@0+ (1,0) [0|3] "" Vector__XXX
 SG_ Fr_ChargingDoorCtrl : 115|2@0+ (1,0) [0|3] "" Vector__XXX
 SG_ Rr_ChargingDoorCtrl : 117|2@0+ (1,0) [0|3] "" Vector__XXX
 SG_ CTDLockSW : 118|1@0+ (1,0) [0|1] "" Vector__XXX
 SG_ CTDUnlockSW : 119|1@0+ (1,0) [0|1] "" Vector__XXX
 SG_ DrDoorSW : 120|1@0+ (1,0) [0|1] "" ESC
 SG_ PsDoorSW : 121|1@0+ (1,0) [0|1] "" OCS
 SG_ RLDoorSW : 122|1@0+ (1,0) [0|1] "" Vector__XXX
 SG_ RRDoorSW : 123|1@0+ (1,0) [0|1] "" Vector__XXX
 SG_ AllDoorSW : 124|1@0+ (1,0) [0|1] "" Vector__XXX
 SG_ DoorLockIND : 125|1@0+ (1,0) [0|1] "" Vector__XXX
 SG_ HoodSW : 126|1@0+ (1,0) [0|1] "" Vector__XXX
 SG_ Tailgate_SW : 127|1@0+ (1,0) [0|1] "" Vector__XXX

BO_ 1665 DiagPhysReqToESC: 8 FUSION
 SG_ DiagPhysReqToESC : 7|64@0+ (1,0) [0|0] "" ESC

BO_ 602 METER1: 24 FUSION
 SG_ METER_KPH_Calcu : 15|8@0+ (1,0) [0|254] "km/h" Vector__XXX
 SG_ METER_MPH_Calcu : 23|8@0+ (1,0) [0|160] "mph" Vector__XXX
 SG_ METER_KPH_Real : 31|12@0+ (0.125,0) [0|255.875] "km/h" Vector__XXX
 SG_ METER_MPH_Real : 35|12@0+ (0.077675,0) [0|160.0105] "mph" Vector__XXX
 SG_ Averaged_vehspeed : 49|10@0+ (1,0) [0|300] "km/h" Vector__XXX
 SG_ AVGPwrConsumption : 71|16@0+ (0.1,-999.9) [-999.9|999.9] "Wh/km" Vector__XXX
 SG_ APCforDTE : 87|16@0+ (0.1,-999.9) [-999.9|999.9] "Wh/km" Vector__XXX
 SG_ AvailableTrip : 103|16@0+ (0.1,0) [0|999.9] "KM" Vector__XXX
 SG_ Spd_Crl_Mode : 118|3@0+ (1,0) [0|7] "" Vector__XXX
 SG_ Spd_Crl_Sta : 115|1@0+ (1,0) [0|1] "" Vector__XXX
 SG_ LEDlitWarnReq : 114|1@0+ (1,0) [0|1] "" Vector__XXX
 SG_ Charge : 113|1@0+ (1,0) [0|1] "" Vector__XXX
 SG_ ParkBrake : 112|1@0+ (1,0) [0|1] "" Vector__XXX
 SG_ Trip_B : 127|24@0+ (0.1,0) [0|99999.9] "KM" Vector__XXX
 SG_ Trip_A : 151|24@0+ (0.1,0) [0|99999.9] "KM" Vector__XXX
 SG_ ODOMETER : 175|24@0+ (0.1,0) [0|999999.9] "KM" ESC,eBST

BO_ 528 FD1_APS2: 32 FUSION
 SG_ USS_Sta_RCR : 0|1@0+ (1,0) [0|1] "" Vector__XXX
 SG_ USS_Sta_RCL : 1|1@0+ (1,0) [0|1] "" Vector__XXX
 SG_ USS_Sta_FMR : 2|1@0+ (1,0) [0|1] "" Vector__XXX
 SG_ USS_Sta_FML : 3|1@0+ (1,0) [0|1] "" Vector__XXX
 SG_ USS_Sta_FLR : 4|1@0+ (1,0) [0|1] "" Vector__XXX
 SG_ USS_Sta_FLL : 5|1@0+ (1,0) [0|1] "" Vector__XXX
 SG_ USS_Sta_FCR : 6|1@0+ (1,0) [0|1] "" Vector__XXX
 SG_ USS_Sta_FCL : 7|1@0+ (1,0) [0|1] "" Vector__XXX
 SG_ PAS_Sta_F_Sys : 9|1@0+ (1,0) [0|1] "" Vector__XXX
 SG_ PAS_Mod_Operation : 11|2@0+ (1,0) [0|3] "" Vector__XXX
 SG_ USS_Sta_RMR : 12|1@0+ (1,0) [0|1] "" Vector__XXX
 SG_ USS_Sta_RML : 13|1@0+ (1,0) [0|1] "" Vector__XXX
 SG_ USS_Sta_RLR : 14|1@0+ (1,0) [0|1] "" Vector__XXX
 SG_ USS_Sta_RLL : 15|1@0+ (1,0) [0|1] "" Vector__XXX
 SG_ PAS_A_FML : 19|4@0+ (1,0) [0|15] "" Vector__XXX
 SG_ PAS_A_FCR : 23|4@0+ (1,0) [0|15] "" Vector__XXX
 SG_ PAS_A_RCL : 27|4@0+ (1,0) [0|15] "" Vector__XXX
 SG_ PAS_A_FMR : 31|4@0+ (1,0) [0|15] "" Vector__XXX
 SG_ PAS_A_RML : 35|4@0+ (1,0) [0|15] "" Vector__XXX
 SG_ PAS_A_RCR : 39|4@0+ (1,0) [0|15] "" Vector__XXX
 SG_ PAS_SNSR_Layout : 43|4@0+ (1,0) [0|15] "" Vector__XXX
 SG_ PAS_A_RMR : 47|4@0+ (1,0) [0|15] "" Vector__XXX
 SG_ APS_D_FLL : 49|10@0+ (1,0) [0|1023] "" Vector__XXX
 SG_ APS_D_FLR : 65|10@0+ (1,0) [0|1023] "" Vector__XXX
 SG_ APS_D_RLL : 81|10@0+ (1,0) [0|1023] "" Vector__XXX
 SG_ APS_D_RLR : 97|10@0+ (1,0) [0|1023] "" Vector__XXX
 SG_ PAS_D_FCL : 119|8@0+ (1,0) [0|150] "" Vector__XXX
 SG_ PAS_D_FCR : 127|8@0+ (1,0) [0|150] "" Vector__XXX
 SG_ PAS_D_FML : 135|8@0+ (1,0) [0|150] "" Vector__XXX
 SG_ PAS_D_FMR : 143|8@0+ (1,0) [0|150] "" Vector__XXX
 SG_ APS_ExitCondition : 151|8@0+ (1,0) [0|255] "" Vector__XXX
 SG_ APS_HW_Ver : 159|8@0+ (1,0) [0|255] "" Vector__XXX
 SG_ APS_SW_Ver : 167|8@0+ (1,0) [0|255] "" Vector__XXX
 SG_ PAS_D_RCL : 175|8@0+ (1,0) [0|150] "" Vector__XXX
 SG_ PAS_D_RCR : 183|8@0+ (1,0) [0|150] "" Vector__XXX
 SG_ PAS_D_RML : 191|8@0+ (1,0) [0|150] "" Vector__XXX
 SG_ PAS_D_RMR : 199|8@0+ (1,0) [0|150] "" Vector__XXX
 SG_ APS_RQ_Display : 207|8@0+ (1,0) [0|255] "" Vector__XXX
 SG_ APS_Progress_PCT : 215|8@0+ (1,0) [0|100] "%" Vector__XXX
 SG_ PAS_A_FCL : 219|4@0+ (1,0) [0|15] "" Vector__XXX
 SG_ PAS_Chime : 223|4@0+ (1,0) [0|15] "" Vector__XXX

BO_ 1681 DiagPhysReqToeBST: 8 FUSION
 SG_ DiagPhysReqToeBST : 7|64@0+ (1,0) [0|0] "" eBST

BO_ 360 eBST1: 8 eBST
 SG_ eBST_AmberWnlmpSta : 0|1@0+ (1,0) [0|1] "" FUSION
 SG_ eBST_RedWnlmpSta : 1|1@0+ (1,0) [0|1] "" FUSION
 SG_ eBST_BeepReq : 7|1@0+ (1,0) [0|1] "" FUSION
 SG_ LowBrakeFluid_Sta : 8|1@0+ (1,0) [0|1] "" FUSION

BO_ 1553 DiagRespFromeBST: 8 eBST
 SG_ DiagRespFromeBST : 7|64@0+ (1,0) [0|0] "" FUSION

BO_ 119 FD1_VMC2: 32 FUSION
 SG_ FDC_VMC_RWS_PositionReq_Cmd : 144|16@1+ (0.01,-327.67) [-327.67|327.68] "mm" RWS
 SG_ FDC_VMC_RWS_Actv_Sta : 138|2@1+ (1,0) [0|3] "" RWS
 SG_ FDC_VMC_RWS_Dfctv_Sta : 140|2@1+ (1,0) [0|3] "" RWS
 SG_ FDC_VMC_SteerFaultReq_Cmd : 83|2@1+ (1,0) [0|3] "" RWS

BO_ 575 GW1_CE100_0: 32 FUSION
 SG_ Rr_TMSpd : 39|16@0+ (1,-18000) [-18000|18000] "RPM" ABM
 SG_ Fr_TMSpd : 23|16@0+ (1,-18000) [-18000|18000] "RPM" ABM
 SG_ BMS_READY : 7|1@0+ (1,0) [0|1] "" Vector__XXX

BO_ 1698 DiagPhysReqToOCS: 64 FUSION
 SG_ DiagPhysReqToOCS : 7|64@0+ (1,0) [0|0] "" OCS

BO_ 1570 DiagRespFromOCS: 64 OCS
 SG_ DiagRespFromOCS : 7|64@0+ (1,0) [0|0] "" FUSION

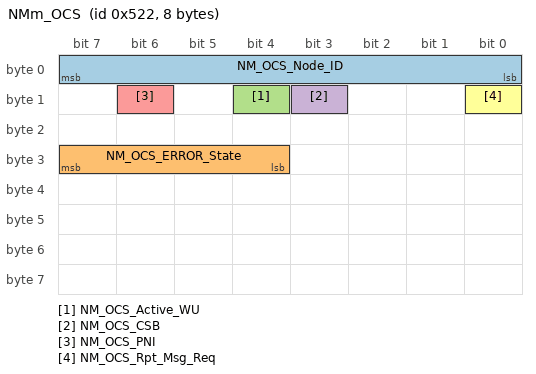
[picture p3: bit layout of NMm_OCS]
BO_ 1314 NMm_OCS: 8 OCS
 SG_ NM_OCS_Node_ID : 7|8@0+ (1,0) [0|127] "" FUSION
 SG_ NM_OCS_ERROR_State : 31|4@0+ (1,0) [0|8] "" FUSION
 SG_ NM_OCS_Active_WU : 12|1@0+ (1,0) [0|1] "" FUSION
 SG_ NM_OCS_CSB : 11|1@0+ (1,0) [0|1] "" FUSION
 SG_ NM_OCS_PNI : 14|1@0+ (1,0) [0|1] "" FUSION
 SG_ NM_OCS_Rpt_Msg_Req : 8|1@0+ (1,0) [0|1] "" FUSION

BO_ 2015 DiagFuncReqOBD: 8 FUSION
 SG_ DiagFuncReqOBD : 7|64@0+ (1,0) [0|0] "" Vector__XXX

BO_ 2033 DiagPhysReqToScrap: 8 FUSION
 SG_ DiagPhysReqToScrap : 7|64@0+ (1,0) [0|0] "" ABM

BO_ 2041 DiagRespFromScrap: 8 ABM
 SG_ DiagRespFromScrap : 7|64@0+ (1,0) [0|0] "" FUSION

BO_ 1173 GW1_CE200_0: 64 FUSION
 SG_ ESC_SW_Cmd : 245|2@0+ (1,0) [0|3] "" ESC
 SG_ Roll_Mode_SW_Cmd : 473|2@0+ (1,0) [0|3] "" ESC
 SG_ TCS_SW_Cmd : 475|2@0+ (1,0) [0|3] "" ESC
 SG_ Roll_Eng_Mode : 478|1@0+ (1,0) [0|1] "" ESC

CM_ BO_ 119 "VMC to RWS for HHTD24";
CM_ SG_ 515 Checksum_ABM1 "Check sum of ABM (AUTOSAR E2E profile 1)

Polynomial 0x1D (x^8+x^4+x^3+x^2+1) Both start value and XOR value are 0x00.";
CM_ SG_ 515 LifeCount_ABM1 "ABM 4-bit rolling counter
It starts counting from 0, ends at 14 and returns to zero (0~14).";
CM_ SG_ 515 CrashOutputSts "Crash Output Status";
CM_ SG_ 515 TRHPsngrSeatBeltCmd "Third RH seatbelt lamp status";
CM_ SG_ 515 AirBagFailCmd "Airbag system lamp status";
CM_ SG_ 515 DriverSeatBeltCmd "Driver Seat Belt lamp status";
CM_ SG_ 515 PsngrSeatBeltCmd "Passenger Seat Belt lamp status";
CM_ SG_ 515 PABSwitchCmd "PAB Switch lamp status";
CM_ SG_ 515 RDriverSeatBeltCmd "Rear driver seat belt lamp status";
CM_ SG_ 515 RPsngrSeatBeltCmd "Rear passenger seat belt lamp status";
CM_ SG_ 515 RCenterSeatBeltCmd "Rear center seat belt lamp status";
CM_ SG_ 515 TLHPsngrSeatBeltCmd "Third LH seatbelt lamp status";
CM_ SG_ 515 ABM_Passenger_ODS_Sta "Passenger ODS  status on CAN Bus";
CM_ SG_ 515 ABM_RearPassengerLH_ODS_Sta "Rear Left Passenger ODS  status on CAN Bus";
CM_ SG_ 515 ABM_RearPassengerCTR_ODS_Sta "Rear Middle Passenger ODS  status on CAN Bus";
CM_ SG_ 515 ABM_RearPassengerRH_ODS_Sta "Rear Right Passenger ODS  status on CAN Bus";
CM_ SG_ 1585 DiagRespFromABM "Diagnostic Response from ABM";
CM_ SG_ 391 EPS_CS "Checksum of EPS1(AUTOSAR E2E profile 1)

Polynomial 0x1D (x^8+x^4+x^3+x^2+1) Both start value and XOR value are 0x00.";
CM_ SG_ 391 EPS_RC "EPS1 4-bit rolling counter
It starts counting from 0, ends at 14 and returns to zero (0~14).";
CM_ SG_ 391 EPS_TOI_Dis_R "EPS TOI Disable Reason";
CM_ SG_ 391 DriIntend "Driver Intend";
CM_ SG_ 391 EPS_AOI_Control "EPS AOI Control";
CM_ SG_ 391 EPS_TOI_Activation "EPS TOI Activation";
CM_ SG_ 391 EPS_TOI_Unavailable "EPS TOI Unavailable";
CM_ SG_ 391 EPS_TOI_Fault "EPS TOI Fault";
CM_ SG_ 391 SAS_V "Steering Wheel Angle validity ( Status of Senosr Failure)";
CM_ SG_ 391 EPS_AOI_Dis_R "EPS AOI Disable Reason";
CM_ SG_ 391 SAS_Speed "Steering Wheel rotation speed
(When not being, calibrated, this value = '0')";
CM_ SG_ 391 SAS_Angle "Absoluted Steering Wheel Angle
(Positive value is clockwise.
When not being calibrated, invalid = 'FFFFh')";
CM_ SG_ 391 Steering_Torque "Steering Torque(Positive value is clockwise.)";
CM_ SG_ 391 EPS_Pwr_Limit_V "EPS Power Limit Validity";
CM_ SG_ 391 Steering_Torque_V "Steering Torque Validity";
CM_ SG_ 391 EPS_Pwr_Consumpt_V "EPS Power Consumption Validity";
CM_ SG_ 391 SAS_Speed_Valid "Steering Wheel rotation speed validity";
CM_ SG_ 391 SAS_CAL "SAS Calibrated Status";
CM_ SG_ 391 EPS_VOL "EPS Voltage";
CM_ SG_ 391 EPS_Temp "EPS Temperature";
CM_ SG_ 391 EPS_Pwr_Limit "EPS Power Limit";
CM_ SG_ 391 EPS_LDW_Activation "EPS LDW Activation";
CM_ SG_ 391 EPS_LDW_Unavailable "EPS LDW Unavailable";
CM_ SG_ 391 EPS_VOL_V "EPS Voltage Validity";
CM_ SG_ 391 EPS_Temp_V "EPS Temperature Validity";
CM_ SG_ 391 EpasFailed "Epas Failed";
CM_ SG_ 391 EPS_Pwr_Consumpt "EPS Power Consumption";
CM_ SG_ 391 EPS_ESABoostOut_Trq "The additional amount of torque calculated from EPS for ESA Driver Steering Assist boost request. Positive is CW, Negative is CCW.";
CM_ SG_ 391 EPS_ESAInpBoost_Sta "The EPS activation status for ESA Driver Steering Assist boost request";
CM_ SG_ 391 EPS_DMSMode_Sta "EPS Driving Mode Selection Function Status";
CM_ SG_ 338 ESC1_CS "Checksum of ESC1(AUTOSAR E2E profile 1)

Polynomial 0x1D (x^8+x^4+x^3+x^2+1) Both start value and XOR value are 0x00.
";
CM_ SG_ 338 ESC1_RC "ESC1 4-bit rolling counter
It starts counting from 0, ends at 14 and returns to zero (0~14).";
CM_ SG_ 338 VehSpeed "Vehicle Speed";
CM_ SG_ 338 RF_WhlRotDir "Right Front Wheel Rotation Direction";
CM_ SG_ 338 RF_PulseCount_V "Right Front Wheel Pulse Counter Validity";
CM_ SG_ 338 Fr_PTCS_Active "Front Axle Torque Reduction Active";
CM_ SG_ 338 FrntAxlTrqReq_Drv "Front Axle Driving Torque Limitation";
CM_ SG_ 338 RearAxlTrqReq_Drv "Rear Axle DrivingTorque Limitation";
CM_ SG_ 338 RF_PulseCount "Right Front Wheel Pulse Counter";
CM_ SG_ 338 RF_RawWhlSpeed "Right Front Raw Wheel Speed";
CM_ SG_ 338 LF_WhlRotDir "Left Front Wheel Rotation Direction";
CM_ SG_ 338 LF_PulseCount_V "Left Front Wheel Pulse Counter Validity";
CM_ SG_ 338 RF_RawWhlSpeed_V "Right Front Raw Wheel Speed Validity";
CM_ SG_ 338 LF_PulseCount "Left Front Wheel Pulse Counter";
CM_ SG_ 338 LF_RawWhlSpeed "Left Front Raw Wheel Speed";
CM_ SG_ 338 RR_WhlRotDir "Right Rear Wheel Rotation Direction";
CM_ SG_ 338 LF_RawWhlSpeed_V "Left Front Raw Wheel Speed Validity";
CM_ SG_ 338 RR_PulseCount_V "Right Rear Wheel Pulse Counter Validity";
CM_ SG_ 338 RR_PulseCount "Right Rear Wheel Pulse Counter";
CM_ SG_ 338 RR_RawWhlSpeed "Right Rear Raw Wheel Speed";
CM_ SG_ 338 LR_WhlRotDir "Left Rear Wheel Rotation Direction";
CM_ SG_ 338 RR_RawWhlSpeed_V "Right Rear Raw Wheel Speed Validity";
CM_ SG_ 338 LR_PulseCount_V "Left Rear Wheel Pulse Counter Validity";
CM_ SG_ 338 LR_PulseCount "Left Rear Wheel Pulse Counter";
CM_ SG_ 338 LR_RawWhlSpeed "Left Rear Raw Wheel Speed";
CM_ SG_ 338 ESC_OFF_Status "Electronic Stability Control OFF Status";
CM_ SG_ 338 ESC_BeepReq "ESC Beep Sound Request";
CM_ SG_ 338 LR_RawWhlSpeed_V "Left Rear Raw Wheel Speed Validity";
CM_ SG_ 338 SystemVoltage "Battery Voltage";
CM_ SG_ 338 TCS_Failed "Traction Control System Failed";
CM_ SG_ 338 ESC_Failed "Electronic Stability Control Failed";
CM_ SG_ 338 HBB_Failed "Hydraulic Brake Boost Failed";
CM_ SG_ 338 PBA_Failed "Panic Brake Assist Failed";
CM_ SG_ 338 HSA_Failed "Hill Start Assist Failed";
CM_ SG_ 338 AVH_Failed "Auto Hold Failed";
CM_ SG_ 338 HDD_Failed "Hydraulic Dynamic Deceleration Failed";
CM_ SG_ 338 Rr_PTCS_Active "Rear Axle Torque Reduction Active";
CM_ SG_ 338 HSA_Active "Hill Start Assist Active";
CM_ SG_ 338 AVH_Active "Auto Hold Active";
CM_ SG_ 338 Amber_WnlmpSta "Amber Warning Lamp Status";
CM_ SG_ 338 BTCS_Active "Brake Traction Control System Active";
CM_ SG_ 338 ESS_Active "Emergency Stop Signaling Active";
CM_ SG_ 338 HDD_Active "Hydraulic Dynamic Deceleration Active";
CM_ SG_ 338 EBD_Failed "EBD System Failed";
CM_ SG_ 338 ABS_Failed "Antilock Brake System Failed";
CM_ SG_ 338 ESC_WnlmpSta "ESC Warning Lamp Status";
CM_ SG_ 338 EBD_Active "EBD System Active";
CM_ SG_ 338 ABS_Active "Antilock Brake System Active";
CM_ SG_ 338 TCS_Active "Traction Control System Active";
CM_ SG_ 338 ESC_Active "Electronic Stability Control Active";
CM_ SG_ 338 HBB_Active "Hydraulic Brake Boost Active";
CM_ SG_ 338 PBA_Active "Panic Brake Assist Active";
CM_ SG_ 338 GRADE "Surface Grade(dynamic)";
CM_ SG_ 338 Red_WnlmpSta "Red Warning Lamp Status";
CM_ SG_ 338 ABS_WnlmpSta "ABS Warning Lamp Status";
CM_ SG_ 338 ESC_Off_lmpSta "ESC Off Warning Lamp Status";
CM_ SG_ 338 ESC_EstVehSpd "Estimated Vehicle Speed";
CM_ SG_ 338 ESC_TSA_Active "TSA Active Status";
CM_ SG_ 338 ESC_EstVehSpd_V "Estimated Vehicle Speed Validity";
CM_ SG_ 421 ESC5_CS "Checksum of ESC5(AUTOSAR E2E profile 1)

Polynomial 0x1D (x^8+x^4+x^3+x^2+1) Both start value and XOR value are 0x00.";
CM_ SG_ 421 ESC5_RC "ESC5 4-bit rolling counter
It starts counting from 0, ends at 14 and returns to zero (0~14).";
CM_ SG_ 421 BrkDiscTempSta "Brake Disc Temperature Status";
CM_ SG_ 421 ACCAvail "ACC Availability";
CM_ SG_ 421 YawRate_V "Yaw Rate Validity";
CM_ SG_ 421 LatAccel_V "Lateral Acceleration Validity";
CM_ SG_ 421 LongAccel_V "Longitudinal Acceleration Validity";
CM_ SG_ 421 MCPressure_V "Master Cylinder Pressure Validity";
CM_ SG_ 421 BrkSw_Sta "Brake switch signal status";
CM_ SG_ 421 BrkSw_V "Brake switch signal Vaild";
CM_ SG_ 421 MCPressure "Master Cylinder Pressure";
CM_ SG_ 421 ESC_ADAS_Sta "Resopnse Status to ADAS Request";
CM_ SG_ 421 LongAccel "Longitudinal Acceleration";
CM_ SG_ 421 LatAccel "Lateral Acceleration";
CM_ SG_ 421 YawRate "Yaw Rate";
CM_ SG_ 421 ESC_Standstill "Standstill Status for APS";
CM_ SG_ 421 DecErrSta "Deceleration Error Status";
CM_ SG_ 421 ActBrkLamp_Sta "Active Brake Lamp Status";
CM_ SG_ 421 AEBAvail "AEB Availability";
CM_ SG_ 421 BrkPedalPos_Sta "Brake Pedal Position Status";
CM_ SG_ 421 ESC_APS_Sta "Response Status to APS Request";
CM_ SG_ 421 Meter_Ind_VehSpeed "Meter Indicated Vehicle Speed";
CM_ SG_ 421 Fr_RBC_Active "Front Regenerative Brake Control Active";
CM_ SG_ 421 Rr_RBC_Active "Rear Regenerative Brake Control Active";
CM_ SG_ 421 RDC_Active "Regen Drag Control Active";
CM_ SG_ 421 BrkPedalPos "Brake Pedal Position";
CM_ SG_ 421 RearAxlTrqReq_Brk "Target Rear Axle Braking Torque";
CM_ SG_ 421 FrntAxlTrqReq_Brk "Target Front Axle Braking Torque";
CM_ SG_ 421 ESC_DriverBrkOverride "Driver Brake Override Status";
CM_ SG_ 427 EPB1_CS "Checksum of EPB1(AUTOSAR E2E profile 1)

Polynomial 0x1D (x^8+x^4+x^3+x^2+1) Both start value and XOR value are 0x00.";
CM_ SG_ 427 EPB1_RC "EPB1 4-bit rolling counter
It starts counting from 0, ends at 14 and returns to zero (0~14).";
CM_ SG_ 427 EPBSta "Electric Parking Brake Status";
CM_ SG_ 427 EPBMsg "EPB Message";
CM_ SG_ 427 EPBStaR "Electric Parking Brake Status Right";
CM_ SG_ 427 EPBErrSta "EPB Error Status";
CM_ SG_ 427 EPBRLampSta "EPB Red Lamp Status";
CM_ SG_ 427 EPBExtReleaseAvail "EPB External Release Availability";
CM_ SG_ 427 EPBExtApplyAvail "EPB External Control Availability";
CM_ SG_ 427 EPBCarWashMode "EPB Car Wash Mode";
CM_ SG_ 427 DOA_Sta "Door Open Apply Status";
CM_ SG_ 427 EPBStaL "Electric Parking Brake Status Left";
CM_ SG_ 427 TakeOverReq "Backup EPB Take Over Request";
CM_ SG_ 1281 NM_ESC_Node_ID "Source Node Identifier";
CM_ SG_ 1281 NM_ESC_Rpt_Msg_Req "Repeat Message Request";
CM_ SG_ 1281 NM_ESC_CSB "NM Coordinator Sleep Bit";
CM_ SG_ 1281 NM_ESC_Active_WU "Active Wakeup Bit";
CM_ SG_ 1281 NM_ESC_PNI "Partial Network Information Bit (PNI)";
CM_ SG_ 1281 NM_ESC_ERROR_State "Defined Error states of the CAN Controller";
CM_ SG_ 278 PrkReqValid "Parking Request Validity";
CM_ SG_ 278 P_Button_Sta "P demand pressed status";
CM_ SG_ 278 CC_Crl_Sta "Cruise Control Status";
CM_ SG_ 278 MSA_Crl_Sta "MSA Status";
CM_ SG_ 278 ShiftGearPosn "EV Selector Position Status/ Selector Position Status Signal Failure";
CM_ SG_ 278 PrkReq "Parking Request";
CM_ SG_ 278 XWDMode "Driving Wheel Selection Mode (RWD/FWD/AWD)";
CM_ SG_ 278 LVPwrSta "LV Power Status";
CM_ SG_ 278 HVPwrSta "HV Power Status";
CM_ SG_ 278 PwrSta "Vehicle Power Status";
CM_ SG_ 278 Eng_AGSCloseSta "AGS close display status";
CM_ SG_ 278 Eng_PwrLockSta "power lock display status";
CM_ SG_ 278 Eng_CoastDwSta "coast down tq map display status";
CM_ SG_ 278 Eng_ActvDmpDisabSta "MCU active damping disable display status";
CM_ SG_ 278 VehMalfunLevel "Vehicle malfunction level";
CM_ SG_ 340 CS_VCU2_CAN1 "Checksum of VCU2(AUTOSAR E2E profile 1)

Polynomial 0x1D (x^8+x^4+x^3+x^2+1) Both start value and XOR value are 0x00.";
CM_ SG_ 340 RC_VCU2_CAN1 "VCU2 4-bit rolling counter
It starts counting from 0, ends at 14 and returns to zero (0~14).";
CM_ SG_ 340 Fr_DriverTq "Driver's Torque on Front Axle";
CM_ SG_ 340 Rr_DriverTq "Driver's Torque on Rear Axle";
CM_ SG_ 340 AccPedal_Override "Drvier Acceleration (Pedal) Override";
CM_ SG_ 340 ACC_CtrlAvail "VCU available for ACC control";
CM_ SG_ 340 VehActPwr "Vehicle Actual Power";
CM_ SG_ 340 DriverTq "Driver's Torque";
CM_ SG_ 340 ActAPSPosn "Accelerator Actual Position";
CM_ SG_ 1280 NM_FUSION_Node_ID "Source Node Identifier";
CM_ SG_ 1280 NM_FUSION_Rpt_Msg_Req "Repeat Message Request";
CM_ SG_ 1280 NM_FUSION_CSB "NM Coordinator Sleep Bit";
CM_ SG_ 1280 NM_FUSION_Active_WU "Active Wakeup Bit";
CM_ SG_ 1280 NM_FUSION_PNI "Partial Network Information Bit (PNI)";
CM_ SG_ 1280 NM_FUSION_ERROR_State "Defined Error states of the CAN Controller";
CM_ SG_ 1713 DiagPhysReqToABM "Diagnostic Physical Request to ABM";
CM_ SG_ 2000 DiagFuncReqFT "Diagnostic Functional Request from Tester";
CM_ SG_ 1297 NM_eBST_Node_ID "Source Node Identifier";
CM_ SG_ 1297 NM_eBST_Rpt_Msg_Req "Repeat Message Request";
CM_ SG_ 1297 NM_eBST_CSB "NM Coordinator Sleep Bit";
CM_ SG_ 1297 NM_eBST_Active_WU "Active Wakeup Bit";
CM_ SG_ 1297 NM_eBST_PNI "Partial Network Information Bit (PNI)";
CM_ SG_ 1297 NM_eBST_ERROR_State "Defined Error states of the CAN Controller";
CM_ SG_ 1168 VehACModReq "Vehicle Air Conition mode
0x2~0x5:Reserved
0x2~0x5:Reserved";
CM_ SG_ 1168 FCP_FrEvt_BtnACMaxReq "AC Max Button Press max cooling";
CM_ SG_ 1168 FCP_FrEvt_BtnACReq "AC Max Button Press max cooling";
CM_ SG_ 1168 FCP_FrEvt_BtnAutoReq "Front Auto Button Press";
CM_ SG_ 1168 FCP_MidEvt_BtnAutoReq "Middle Auto Button Press";
CM_ SG_ 1168 FCP_FrEvt_BtnSyncReq "Sync Button Press";
CM_ SG_ 1168 OTA_DL_Req "OTA Download Request";
CM_ SG_ 1168 OTA_SuspendDL_Req "OTA Suspend Download Request";
CM_ SG_ 1168 OTA_UpdStart_Req "OTA Update Start Request";
CM_ SG_ 1168 IVI_OTA_Upd_Sta "IVI OTA Update Status";
CM_ SG_ 1168 OTA_CancelDL_Req "OTA Cancel Download Request";
CM_ SG_ 1168 SmartEco_Mode_SW "Smart ECO Mode Switch";
CM_ SG_ 1168 LINKtoDrive "LINK to Drive";
CM_ SG_ 1168 Upd_Countdown_Skip "Update Countdown Skip";
CM_ SG_ 1168 Upd_Countdown_Cancel "Update Countdown Cancel";
CM_ SG_ 1168 AmbLightColorSet "AmbLight Color Set";
CM_ SG_ 1168 Sched_OTA_wake "Scheduled OTA wake up";
CM_ SG_ 1168 UserSet "UserSet";
CM_ SG_ 1168 AmbLightBrightnessSet "Ambient Light Brightness Set";
CM_ SG_ 1168 Sched_Chg_Day_Set "Scheduled Charging Daily setting";
CM_ SG_ 1168 Re_Radio_Sta "Re-active Radio Status";
CM_ SG_ 1168 Sched_Chg_St_Time_Min "Scheduled Charging Start Time Minute Setting";
CM_ SG_ 1168 A2B_Node_sta "A2B node status";
CM_ SG_ 1168 Sched_Chg_St_Time_HR "Scheduled Charging Start Time Hour Setting";
CM_ SG_ 1168 IVI_Located_STA "IVI_GPS Satellite Located status";
CM_ SG_ 1168 Sched_Chg_End_Time_Min "Scheduled Charging End Time Minute Setting";
CM_ SG_ 1168 OTA_CompNTFY_Pres "OTA Complete notify presented";
CM_ SG_ 1168 BrkAbn_GoReady_SW "Brake Abnormal Go Ready";
CM_ SG_ 1168 Sched_Chg_End_Time_HR "Scheduled Charging End Time Hour Setting";
CM_ SG_ 1168 IVI_Time_Check "IVI_GPS Satellite Time_Check Sum";
CM_ SG_ 1168 PW_CONTINUE_USE "Power Continue Use";
CM_ SG_ 1168 PW_CLOSE_IMD "Power Close Immediately";
CM_ SG_ 1168 IVI_Time_Second "IVI_GPS Satellite Time_Second";
CM_ SG_ 1168 IVI_Time_Minute "IVI_GPS Satellite Time_Minute";
CM_ SG_ 1168 IVI_Time_Day "IVI_GPS Satellite Time_Day";
CM_ SG_ 1168 IVI_Time_Hour "IVI_GPS Satellite Time_Hour";
CM_ SG_ 1168 IVI_Time_Month "IVI_GPS Satellite Time_Month";
CM_ SG_ 1168 IVI_Time_Year "IVI_GPS Satellite Time_Year";
CM_ SG_ 1168 mFRD_link_Sta "Meter FRD Link status";
CM_ SG_ 1168 AmbLight_SW "AmbLight Switch";
CM_ SG_ 1168 AmbLight_DimInDark_SW "AmbLight Dimmed In Dark Switch";
CM_ SG_ 1168 AmbLight_WlcmLight_SW "AmbLight Welcome light Switch";
CM_ SG_ 1168 AmbLigh_LowBatAlert_SW "AmbLight Low battery alert Switch";
CM_ SG_ 1168 AmbLigh_SafetyAlert_SW "AmbLight Safety alert Switch";
CM_ SG_ 1168 OpenDrOpenWdo_SW "Open Door Link Open Window Switch";
CM_ SG_ 1168 IVI_LinkKey_Sta "Target key of link key function";
CM_ SG_ 1168 IVI_CreateAccReq_Sta "IVI Create account request";
CM_ SG_ 1168 IVI_DelAccReq_Sta "IVI Delete account request";
CM_ SG_ 1168 IVI_LinkAcc_Sta "Target user of link key function (0x6 is default user, is not linkable)";
CM_ SG_ 1168 IVI_LinkAccReq_Sta "IVI link target key to target user request";
CM_ SG_ 1168 IVI_FrTrunk_UnlockReq_Sta "IVI Front Trunk Unlock Request";
CM_ SG_ 1168 IVI_CLWin_LockDoorSW_Sta "Close window when lock door";
CM_ SG_ 1168 IVI_Lock_SoundSW_Sta "IVI_Lock_SoundSW_Sta";
CM_ SG_ 1168 IVI_SWC_VibMode_Sta "IVI Steering Wheel  Vibration Mode";
CM_ SG_ 1168 IVI_DMS_SW_Sta "IVI Driver Monitoring System Switch";
CM_ SG_ 1168 IVI_AirRefresh_ByDMS_Sta "IVI Air Refresh Detect by DMS switch";
CM_ SG_ 1168 IVI_QuickRefresh_Sta "IVI Quick Refresh Switch";
CM_ SG_ 1168 IVI_HMI_Undefined_Sta "IVI HMI Undefined button Mode ";
CM_ SG_ 1168 IVI_AutoTheme_But_Sta "IVI Auto Light/Dark Theme Button Status";
CM_ SG_ 1168 IVI_NAVI_Foreground_Sta "IVI Navigation Foreground Status";
CM_ SG_ 1168 IVI_sigScreenReq_Sta "IVI SCREEN BLOWER REQUEST ";
CM_ SG_ 1168 IVI_DSEAT_anti_set_Sta "Driver Seat Antitheft on/off request";
CM_ SG_ 1168 IVI_MirrorFolded_SW_Sta "IVI Outside Mirror Folded Switch";
CM_ SG_ 1168 IVI_WPTC_SW_Sta "IVI Water PTC Switch";
CM_ SG_ 1168 IVI_Driving_Lock_SW_Sta "Lock when driving switch";
CM_ SG_ 1168 IVI_Stopping_Unlock_SW_Sta "Unlock when stopping switch";
CM_ SG_ 1168 IVI_SilentChrg_Alert_Sta "IVI Silent Charge Alert Popup Status";
CM_ SG_ 1168 IVI_WirelessCharge_Cmd "IVI_WirelessCharge_Cmd";
CM_ SG_ 1168 IVI_Theme_Sta "IVI_Theme_Sta";
CM_ SG_ 1168 IVI_EPS_Force_Cmd "IVI_EPS_Force_Cmd";
CM_ SG_ 1168 IVI_DSEAT_StopKeepMove_Sta "IVI_DSEAT_StopKeepMove_Sta";
CM_ SG_ 1168 IVI_AutoWipHSpdSW_Cmd "IVI_AutoWipHSpdSW_Cmd";
CM_ SG_ 1168 IVI_DSEAT_entryfun_set_Sta "IVI_DSEAT_entryfun_set_Sta";
CM_ SG_ 1569 DiagRespFromEPS "Diagnostic Response from EPS";
CM_ SG_ 370 VMC_FCM1_Checksum "Checksum of VMC_FCM1(AUTOSAR E2E profile 1)

Polynomial 0x1D (x^8+x^4+x^3+x^2+1) Both start value and XOR value are 0x00.";
CM_ SG_ 370 VMC_FCM1_LifeCount "VMC_FCM1 4-bit rolling counter
It starts counting from 0, ends at 14 and returns to zero (0~14).";
CM_ SG_ 370 VMC_FCM_LKA_TOIAct "Activate TOI";
CM_ SG_ 370 VMC_FCM_LKA_StrToqReq "Steering Torque Request";
CM_ SG_ 370 VMC_AEB_VehHoldReq "Vehicle Hold Request";
CM_ SG_ 370 VMC_FCM_LKA_TOIFault "LKA TOI Fault";
CM_ SG_ 370 VMC_FCM_LDW_Fault "VMC FCM LDW Fault";
CM_ SG_ 370 VMC_FCM_LDW_Request "VMC FCM LDW Request";
CM_ SG_ 370 VMC_ACC_RequiredAccel "Required acceleration";
CM_ SG_ 370 VMC_ADAS_AEBReq "AEB Request";
CM_ SG_ 370 VMC_ADAS_FaultSta "ADAS Fault Status";
CM_ SG_ 370 VMC_ADAS_DBSReq "DBS request to ESC";
CM_ SG_ 370 VMC_ACC_VehHoldReq "ACC Hold Request";
CM_ SG_ 370 VMC_ACC_ComfortBandUpper "Required acceleration upper limit Comfort";
CM_ SG_ 370 VMC_ACC_JerkUpperLInit "Jerk upper limit Jerk";
CM_ SG_ 370 VMC_ACC_ComfortBandLower "Required acceleration lower limit Comfort";
CM_ SG_ 370 VMC_ACC_JerkLowerLInit "Jerk lower limit Jerk";
CM_ SG_ 370 VMC_ADAS_ACC_Sta "ACC Status";
CM_ SG_ 370 VMC_ADAS_AEB_Sta "AEB Status";
CM_ SG_ 370 FDC_VMC_DrInpTqBstGn "The driver input torque amplification gain for ESA Driver Steering Assist driver additional torque assist";
CM_ SG_ 370 FDC_VMC_AngCtrlTqWtGn "The weight gain for applying torque to steering wheel angle control";
CM_ SG_ 370 FDC_VMC_MaxAngCtrlOutTqLim "The request for limit torque to steering wheel angle control. Absolute of limit torque for both positive and negative.";
CM_ SG_ 370 FDC_VMC_DrInpTqBstAct "The activation signal for ESA Driver Steering Assist driver input torque amplification";
CM_ SG_ 370 FDC_VMC_DMSMode_Cmd "VMC EPS Driving Mode Selection Function Command";
CM_ SG_ 383 FeatSetSpdFinal_raw32 "Final Feature Set Speed  (if IVI2 Distance_unit = 0x0, then UNIT = KPH, else UNIT = MPH)";
CM_ SG_ 383 MeterIndSpeed_raw32 "Meter Speed (if IVI2 Distance_unit = 0x0, then UNIT = KPH, else UNIT = MPH)";
CM_ SG_ 383 DISCReqAcc "VMC DISC Request Acceleration Calculated Result";
CM_ SG_ 383 FeatArbitrFinal "VMC Feature Arbitration Final Result";
CM_ SG_ 383 DISC_ButtSta "DISC button States ON/OFF";
CM_ SG_ 383 SPD2ACCAct "Flag to Trig SPD2ACC Module";
CM_ SG_ 383 DISC_DISCTurn "DISC Turning Control States";
CM_ SG_ 383 AccCalcuPID "PID Calculated Acceleration";
CM_ SG_ 383 DISC_DISCTargetSpd "DISC Target Speed";
CM_ SG_ 383 FeatArbitrSta "VMC Feature Arbitration Status";
CM_ SG_ 383 DISC_Sta "DISC States";
CM_ SG_ 383 CCMSA_SpdWar "CC/MSA downslope overspeed warning";
CM_ SG_ 383 LatAccCtrl "Lateral Acceleration Control Flag";
CM_ SG_ 383 LateralCtrl "VMC Lateral Control Flag";
CM_ SG_ 383 LimitPCT "VMC ISO Limit Response Percentage";
CM_ SG_ 383 SafetyCtrl "Safety Control Flag";
CM_ SG_ 383 JerkPCT "VMC Jerk Response Percentage";
CM_ SG_ 383 SingleWhlSlipRatioCtrl "Single Wheel Slip Ratio Safety Control Flag";
CM_ SG_ 383 VMC_VCU_CC_Crl_Sta "Cruise control control state";
CM_ SG_ 383 VMC_AEBCtrlAvail "VMC AEB Control Availability";
CM_ SG_ 383 VMC_CCCtrlAvail "VMC CC Control Availability";
CM_ SG_ 383 VMC_MSACtrlAvail "VMC MSA Control Availability";
CM_ SG_ 383 RearWhlSlipRatioCtrl "Rear Left and Right Wheel Slip Ratio Safety Control Flag";
CM_ SG_ 383 FrontRearSlipRatioCtrl "Front Axle and Rear Axle Slip Ratio Safety Control Flag";
CM_ SG_ 383 VMC_VCU_ACC_CtrlAvail "ACC control Available flag";
CM_ SG_ 383 VMC_VCU_AccPedal_Override "ACC Pedal Override";
CM_ SG_ 383 VMC_VCU_MSA_Crl_Sta "MSA control control state";
CM_ SG_ 383 VMC_VCU_APSCtrlAvail_flg "APS internal available status";
CM_ SG_ 383 VMC_ACCCtrlAvail "VMC ACC Control Availability";
CM_ SG_ 383 TimeGapCalcu "VMC Calculated Time Gap";
CM_ SG_ 383 FeatReqSpd "VMC Feature Request Speed Command";
CM_ SG_ 383 VehicleSpeed_kph "Vehicle Speed(kph)";
CM_ SG_ 383 VehicleSpeed_mph "Vehicle Speed(mph)";
CM_ SG_ 568 APS3_checksum "checksum of APS3(AUTOSAR E2E profile 1)

Polynomial 0x1D (x^8+x^4+x^3+x^2+1) Both start value and XOR value are 0x00.";
CM_ SG_ 568 APS3_LifeCount "APS3 4-bit rolling counter
It starts counting from 0, ends at 14 and returns to zero (0~14).";
CM_ SG_ 568 APSOpenPTG "Smart PTG open request";
CM_ SG_ 568 CAAS_Sta "The operation status of CAAS";
CM_ SG_ 568 APS_Req "ESC control request";
CM_ SG_ 568 APS_DecReq_A "APS Vehicle Deceleration Request Applicable";
CM_ SG_ 568 APS_DecReq "APS Vehicle Deceleration Request";
CM_ SG_ 568 FDC_VMC_APS_Angle_Target "to indicate the target steering angle(Positive value is clockwise.
When not being calibrated, invalid = 'FFFFh')";
CM_ SG_ 568 APS_Sta_System "The operation status of APA system";
CM_ SG_ 568 FDC_VMC_APS_V_Rq_EPS_Ctrl "to indicate if the signal Request Active is valid or not";
CM_ SG_ 568 SPTG_Sta "The operation status of SPTG";
CM_ SG_ 568 SPTGDet "Smart PTG Detecting";
CM_ SG_ 568 FDC_VMC_APS_Rq_EPS_Ctrl "This signal is used when the APA need to control the steering wheel";
CM_ SG_ 568 FDC_RAPS_PwrReq_Cmd "power request for RAPS";
CM_ SG_ 568 FDC_RAPS_BCMLamp_Cmd "lamp request for RAPS";
CM_ SG_ 568 FDC_RAPS_PwrReqAvail_Sta "PMM available for RAPS control";
CM_ SG_ 568 FDC_RAPS_BCMLockReq_Cmd "lock request for RAPS";
CM_ SG_ 568 FDC_APS_CaasCtrlAvail_Sta "VMC available for CAAS control
Debug";
CM_ SG_ 568 FDC_APS_CaasVMCReqA_Cmd "CAAS VMC control Request";
CM_ SG_ 568 FDC_APS_VMCReqA_Cmd "APS VMC control Request";
CM_ SG_ 568 FDC_APS_SpeedReq_Cmd "APS VMC Speed control Request";
CM_ SG_ 568 FDC_APS_ShftPosnReq_Cmd "APS VMC ShftPosn control Request";
CM_ SG_ 568 FDC_APS_CaasActive_Sta "VMC CAAS active state";
CM_ SG_ 568 FDC_APS_CtrlAvail_Sta "VMC available for APS control";
CM_ SG_ 568 FDC_APS_Active_Sta "VMC APS active state";
CM_ SG_ 568 FDC_VCU_RAPSErrLv3_Flg "VCU RAPS error level 3";
CM_ SG_ 568 FDC_VCU_RAPSErrLv2_Flg "VCU RAPS error level 2";
CM_ SG_ 568 FDC_RAPS_ErrLv1_Flg "FDC_RAPS_ErrLv1_Flg";
CM_ SG_ 1697 DiagPhysReqToEPS "Diagnostic Physical Request to EPS";
CM_ SG_ 1537 DiagRespFromESC "Diagnostic Response from ESC";
CM_ SG_ 345 CS_VCU3_CAN1 "Checksum of VCU3(AUTOSAR E2E profile 1)

Polynomial 0x1D (x^8+x^4+x^3+x^2+1) Both start value and XOR value are 0x00.";
CM_ SG_ 345 RC_VCU3_CAN1 "VCU3 4-bit rolling counter
It starts counting from 0, ends at 14 and returns to zero (0~14).";
CM_ SG_ 345 Rr_RgnPermSta "Rear EDU Regeneration Permission Status";
CM_ SG_ 345 Fr_RgnPermSta "Front EDU Regeneration Permission Status";
CM_ SG_ 345 Rr_RgnDecrSta "Rear EDU Regeneration Decrease Status";
CM_ SG_ 345 Fr_RgnDecrSta "Front EDU Regeneration Decrease Status";
CM_ SG_ 345 RgnAbnorSta "Regeneration Abnormality Status";
CM_ SG_ 345 Rr_EDUSpdValid "Rear EDU Rotational Speed Validity";
CM_ SG_ 345 Fr_EDUSpdValid "Front EDU Rotational Speed Validity";
CM_ SG_ 345 Rr_EDUSpd "Rear EDU(Electric Drive Unit) Rotational Speed(After Gearbox)";
CM_ SG_ 345 EquivAccPedalSWSta "ADAS equivalent acceleration pedal switch status";
CM_ SG_ 345 PTCS_PermSta "Driving Torque Reduction Permission Status";
CM_ SG_ 345 Rr_EDURealARgnTq "Rear side real A-regen torque";
CM_ SG_ 345 Rr_EDUAvailBrkRgnTq "Rear EDU(Electric Drive Unit) Available Braking Regeneration Torque (Maximum available regeneration torque - current rolling regeneration torque)";
CM_ SG_ 345 Rr_EDURealDrvOrBRgnTq "Rear side driving or brake regen torque";
CM_ SG_ 345 Fr_EDUSpd "Front EDU(Electric Drive Unit) Rotational Speed(After Gearbox)";
CM_ SG_ 345 Fr_EDUAvailBrkRgnTqValid "Front EDU(Electric Drive Unit) Available Braking Regeneration Torque Validity";
CM_ SG_ 345 Rr_EDUAvailBrkRgnTqValid "Rear EDU(Electric Drive Unit) Available Braking Regeneration Torque Validity";
CM_ SG_ 345 Fr_EDURealARgnTq "Front side real A-regen torque";
CM_ SG_ 345 Fr_EDUAvailBrkRgnTq "Front EDU(Electric Drive Unit) Available Braking Regeneration Torque (Maximum available regeneration torque - current rolling regeneration torque)";
CM_ SG_ 345 Fr_EDURealDrvOrBRgnTq "Front side driving or brake regen torque";
CM_ SG_ 386 Fr_Coolanttemp "LLC coolant temp";
CM_ SG_ 386 CCU_ACMaxLampSts "Climate AC Max lamp state";
CM_ SG_ 386 CCU_AutoLampSts "Climate air conditionning Front  automatic mode lamp state";
CM_ SG_ 386 CCU_AutoMidLampSts "Climate air conditionning middle left automatic mode lamp state";
CM_ SG_ 386 CCU_EcoSts "Economic mode status";
CM_ SG_ 386 CCU_Dispaly_Request "Air Conditioner display reuqest trigger";
CM_ SG_ 386 CCU_ACLampSts "Climate AC lamp state";
CM_ SG_ 386 CCU_HEATMaxLampSts "Climate HEATING Max lamp state";
CM_ SG_ 386 sigWindDirZon3St "Feedback: WInd DirectionZone 3. 
Feed, Body and/or Auto";
CM_ SG_ 386 CCU_FrtOnOffLampSts "Front Climate On Off lamp state";
CM_ SG_ 386 sigWindDirZon1St "Feedback: WInd DirectionZone 1. 
Feed, Body, WIndscreen and/or Auto";
CM_ SG_ 386 CCU_RrOnOffLampSts "Rear Climate On Off lamp state";
CM_ SG_ 386 sigAirIntenZon3St "Feedback FAN Level/Air Intensirty : 0-Max or Auto for zone 3";
CM_ SG_ 386 sigAirIntenZon1St "Feedback FAN Level/Air Intensirty : 0-Max or Auto for zone 1";
CM_ SG_ 386 sigSetTempZon3St "Feedback: Temperature set in the HVAC for Zone 3";
CM_ SG_ 386 sigDfrstSt "Defrost Status in the HVAC (ON / AUTO)";
CM_ SG_ 386 CCU_SyncLampSts "Climate SYNC lamp state";
CM_ SG_ 386 sigSetTempZon2St "Feedback: Temperature set in the HVAC for Zone 2";
CM_ SG_ 386 sigHvacSt "Status of the HVAC (ON / OFF)";
CM_ SG_ 386 sigRecircSt "Recirculation Status in the HVAC (Fre/Rec/Auto)";
CM_ SG_ 386 sigSetTempZon1St "Feedback: Temperature set in the HVAC for Zone 1";
CM_ SG_ 386 HPThermalRecoveryReq "Heat Pump thermal reuse request";
CM_ SG_ 386 Fr_Coolantflow "LLC coolant flow rate";
CM_ SG_ 386 EDriveMode "E-Drive Mode";
CM_ SG_ 386 sigClmtCmprPwrAct "Current power consumption AC compressor";
CM_ SG_ 386 sigCbnPTCPwrAct "Current power consumption FRONT AirPTC";
CM_ SG_ 386 sigCbnAirT "Cabin air temperature";
CM_ SG_ 386 sigAmbAirT "Environment temperature (outside ambient vehicle temperature)";
CM_ SG_ 386 sigCbnSolarRight "Measured cabin sun exposure";
CM_ SG_ 386 FD_RecyAuto_Cmd "Auto recycle command";
CM_ SG_ 386 CabinMode "Cabin Mode";
CM_ SG_ 386 BatteryMode "Battery Mode";
CM_ SG_ 386 sigCbnSolarLeft "Measured cabin sun exposure";
CM_ SG_ 386 sigClntTHvBattOut "battery coolant outlet temperature";
CM_ SG_ 386 FD_AGS_Cmd "Fusion Domain AGS Position Request";
CM_ SG_ 386 Rr_Coolanttemp "LLC coolant temp";
CM_ SG_ 386 Rr_Coolantflow "LLC coolant flow rate";
CM_ SG_ 534 BCM_Buzzer_Req "BCM Buzzer Request";
CM_ SG_ 534 TailgateRemote "Remote Control PTG";
CM_ SG_ 534 RoomLampL "Room Lamp Low";
CM_ SG_ 534 RoomLampH "Room Lamp High";
CM_ SG_ 534 DimmerEN "Dimmer Enable";
CM_ SG_ 534 BCM_DoorLock_Sta "BCM Unlock Single Door Setting";
CM_ SG_ 534 HornCtrl "Horn Control";
CM_ SG_ 534 Dimmer "Dimmer";
CM_ SG_ 534 LockSetting "BCM Unlock Single Door Setting";
CM_ SG_ 534 LTurnLP "Left Turn Lamp";
CM_ SG_ 534 RTurnLP "Right Turn Lamp";
CM_ SG_ 534 AntitheftSta "Anti-theft Status";
CM_ SG_ 534 AntiTheftSeatFold "Anti-theft Seat Fold";
CM_ SG_ 534 CrashDetd "Crash Detected";
CM_ SG_ 534 L_APM_WdwEnable "Enable windows movement";
CM_ SG_ 534 RDRL "Right DRL";
CM_ SG_ 534 ReverseLamp "ReverseLamp";
CM_ SG_ 534 BrakeLamp "BrakeLamp";
CM_ SG_ 534 LBSD "Left BSD";
CM_ SG_ 534 RBSD "Right BSD";
CM_ SG_ 534 Fr_FogLamp "Front Fog Lamp";
CM_ SG_ 534 Rr_FogLamp "Rear Fog Lamp";
CM_ SG_ 534 HazardSW "Hazard SW";
CM_ SG_ 534 Rr_Wiper "Rear Wiper";
CM_ SG_ 534 WiperFixMode "Wiper Fix Mode";
CM_ SG_ 534 WasherCtrl "WasherControl";
CM_ SG_ 534 L_Beam "Low Beam";
CM_ SG_ 534 H_Beam "High Beam";
CM_ SG_ 534 PosLamp "PositionLamp";
CM_ SG_ 534 LDRL "Left DRL";
CM_ SG_ 534 MirrorDefog "Mirror Defog";
CM_ SG_ 534 Rr_Defog "Rear Defog";
CM_ SG_ 534 TrunkRel "Trunk Release";
CM_ SG_ 534 TailgateHDSW "Tailgate Handle SW";
CM_ SG_ 534 MirrorCtrl "Mirror Control";
CM_ SG_ 534 Fr_Wiper_H "Front Wiper High";
CM_ SG_ 534 Fr_Wiper_L "Front Wiper LOW";
CM_ SG_ 534 CTDCtrl "Door Lock Control";
CM_ SG_ 534 Fr_ChargingDoorCtrl "Front Charging Door Control";
CM_ SG_ 534 Rr_ChargingDoorCtrl "Rear Charging Door Control";
CM_ SG_ 534 CTDLockSW "Central Door Lock SW";
CM_ SG_ 534 CTDUnlockSW "Central Door Unlock SW";
CM_ SG_ 534 DrDoorSW "Driver Side Door Switch";
CM_ SG_ 534 PsDoorSW "Passenger Side Door Switch";
CM_ SG_ 534 RLDoorSW "Rear Left Door Switch";
CM_ SG_ 534 RRDoorSW "Rear Right Door Switch";
CM_ SG_ 534 AllDoorSW "All Door Switch";
CM_ SG_ 534 DoorLockIND "Door Lock Indicator";
CM_ SG_ 534 HoodSW "Hood Switch";
CM_ SG_ 534 Tailgate_SW "Tailgate Switch";
CM_ SG_ 1665 DiagPhysReqToESC "Diagnostic Physical Request to ESC";
CM_ SG_ 602 METER_KPH_Calcu "METER Calculated Speed(KPH)";
CM_ SG_ 602 METER_MPH_Calcu "METER Calculated Speed(MPH)";
CM_ SG_ 602 METER_KPH_Real "METER Real Speed(KPH)";
CM_ SG_ 602 METER_MPH_Real "METER Real Speed(MPH)";
CM_ SG_ 602 Averaged_vehspeed "Averaged_vehspeed";
CM_ SG_ 602 AVGPwrConsumption "average power consumption";
CM_ SG_ 602 AvailableTrip "Distance to Empty";
CM_ SG_ 602 Spd_Crl_Mode "Speed Control Function Mode";
CM_ SG_ 602 Spd_Crl_Sta "Speed Control Function Status";
CM_ SG_ 602 LEDlitWarnReq "LED lit Warning Request";
CM_ SG_ 602 Charge "Charge";
CM_ SG_ 602 ParkBrake "Park Brake";
CM_ SG_ 602 Trip_B "TripB";
CM_ SG_ 602 Trip_A "TripA";
CM_ SG_ 602 ODOMETER "Odometer";
CM_ SG_ 528 USS_Sta_RCR "USS RCR Fault status";
CM_ SG_ 528 USS_Sta_RCL "USS RCL Fault status";
CM_ SG_ 528 USS_Sta_FMR "USS FMR Fault status";
CM_ SG_ 528 USS_Sta_FML "USS FML Fault status";
CM_ SG_ 528 USS_Sta_FLR "USS FLR Fault status";
CM_ SG_ 528 USS_Sta_FLL "USS FLL Fault status";
CM_ SG_ 528 USS_Sta_FCR "USS FCR Fault status";
CM_ SG_ 528 USS_Sta_FCL "USS FCL Fault status";
CM_ SG_ 528 PAS_Sta_F_Sys "PBS_SYS_FAIL";
CM_ SG_ 528 PAS_Mod_Operation "To show the operation mode of system";
CM_ SG_ 528 USS_Sta_RMR "USS RMR Fault status";
CM_ SG_ 528 USS_Sta_RML "USS RML Fault status";
CM_ SG_ 528 USS_Sta_RLR "USS RLR Fault status";
CM_ SG_ 528 USS_Sta_RLL "USS RLL Fault status";
CM_ SG_ 528 PAS_A_FML "To show the level of distance detected from sensor FML";
CM_ SG_ 528 PAS_A_FCR "To show the level of distance detected from sensor FCR";
CM_ SG_ 528 PAS_A_RCL "To show the level of distance detected from sensor RCL";
CM_ SG_ 528 PAS_A_FMR "To show the level of distance detected from sensor FMR";
CM_ SG_ 528 PAS_A_RML "To show the level of distance detected from sensor RML";
CM_ SG_ 528 PAS_A_RCR "To show the level of distance detected from sensor RCR";
CM_ SG_ 528 PAS_SNSR_Layout "To show the sensor layout";
CM_ SG_ 528 PAS_A_RMR "To show the level of distance detected from sensor RMR";
CM_ SG_ 528 APS_D_FLL "To show the distance detected from sensor FLL";
CM_ SG_ 528 APS_D_FLR "To show the distance detected from sensor FLR";
CM_ SG_ 528 APS_D_RLL "To show the distance detected from sensor RLL";
CM_ SG_ 528 APS_D_RLR "To show the distance detected from sensor RLR";
CM_ SG_ 528 PAS_D_FCL "To show the distance detected from sensor FCL";
CM_ SG_ 528 PAS_D_FCR "To show the distance detected from sensor FCR";
CM_ SG_ 528 PAS_D_FML "To show the distance detected from sensor FML";
CM_ SG_ 528 PAS_D_FMR "To show the distance detected from sensor FMR";
CM_ SG_ 528 APS_ExitCondition "APS Disable Cause";
CM_ SG_ 528 APS_HW_Ver "APS Hardware Version Number";
CM_ SG_ 528 APS_SW_Ver "APS Software Version Number";
CM_ SG_ 528 PAS_D_RCL "To show the distance detected from sensor RCL";
CM_ SG_ 528 PAS_D_RCR "To show the distance detected from sensor RCR";
CM_ SG_ 528 PAS_D_RML "To show the distance detected from sensor RML";
CM_ SG_ 528 PAS_D_RMR "To show the distance detected from sensor RMR";
CM_ SG_ 528 APS_RQ_Display "Request to show the APA operation";
CM_ SG_ 528 APS_Progress_PCT "information for show the APA operation percentage";
CM_ SG_ 528 PAS_A_FCL "To show the level of distance detected from sensor FCL";
CM_ SG_ 528 PAS_Chime "The types of chime for PSS system";
CM_ SG_ 1681 DiagPhysReqToeBST "Diagnostic Physical Request to eBST";
CM_ SG_ 360 eBST_AmberWnlmpSta "eBST Amber Warning Lamp Status";
CM_ SG_ 360 eBST_RedWnlmpSta "eBST Red Warning Lamp Status";
CM_ SG_ 360 eBST_BeepReq "eBST Beep Sound Request";
CM_ SG_ 360 LowBrakeFluid_Sta "Low Brake Fluid Status";
CM_ SG_ 1553 DiagRespFromeBST "Diagnostic Response from eBST";
CM_ SG_ 119 FDC_VMC_RWS_PositionReq_Cmd "RWS POSITION REQUEST";
CM_ SG_ 119 FDC_VMC_RWS_Actv_Sta "RWS ACTIVE STATUS";
CM_ SG_ 119 FDC_VMC_RWS_Dfctv_Sta "RWS DEFECTIVE STATUS";
CM_ SG_ 119 FDC_VMC_SteerFaultReq_Cmd "RWS FAULT REQUEST";
CM_ SG_ 575 Rr_TMSpd "Rear TM speed";
CM_ SG_ 575 Fr_TMSpd "Front TM speed";
CM_ SG_ 575 BMS_READY "BMS ready";
CM_ SG_ 1698 DiagPhysReqToOCS "Diagnostic Physical Request to OCS";
CM_ SG_ 1570 DiagRespFromOCS "Diagnostic Response from OCS";
CM_ SG_ 1314 NM_OCS_Node_ID "Source Node Identifier";
CM_ SG_ 1314 NM_OCS_ERROR_State "Defined Error states of the CAN Controller";
CM_ SG_ 1314 NM_OCS_Active_WU "Active Wakeup Bit";
CM_ SG_ 1314 NM_OCS_CSB "NM Coordinator Sleep Bit";
CM_ SG_ 1314 NM_OCS_PNI "Partial Network Information Bit (PNI)";
CM_ SG_ 1314 NM_OCS_Rpt_Msg_Req "Repeat Message Request";
CM_ SG_ 2015 DiagFuncReqOBD "Diagnostic Functional Request from OBD Tester";
CM_ SG_ 2033 DiagPhysReqToScrap "Diagnostic Physical Request to ABM";
CM_ SG_ 2041 DiagRespFromScrap "Diagnostic Response from ABM";
CM_ SG_ 1173 ESC_SW_Cmd "ESC ON/OFF Buttom";
CM_ SG_ 1173 Roll_Mode_SW_Cmd "Roll Mode Switch command";
CM_ SG_ 1173 TCS_SW_Cmd "TCS Switch command";
CM_ SG_ 1173 Roll_Eng_Mode "Roll Engine Mode";

BA_DEF_ "NmType" STRING ;
BA_DEF_ "VersionYear" INT 2010 2999;
BA_DEF_ "ProtocolType" STRING ;
BA_DEF_ "NmMessageCount" INT 0 255;
BA_DEF_ "NmBaseAddress" HEX 1280 1407;
BA_DEF_ "Manufacturer" STRING ;
BA_DEF_ "DBName" STRING ;
BA_DEF_ "BusType" STRING ;
BA_DEF_ "Baudrate" INT 0 1000000;
BA_DEF_ "Datarate" INT 0 2000000;
BA_DEF_ BO_ "GenMsgSendType" ENUM "Cycle","NoMsgSendType","IfActive","Event","CA","CE";
BA_DEF_ BO_ "GenMsgNrOfRepetition" INT 0 0;
BA_DEF_ BO_ "GenMsgILSupport" ENUM "No","Yes";
BA_DEF_ BO_ "GenMsgCycleTime" INT 0 0;
BA_DEF_ BO_ "DiagResponse" ENUM "No","Yes";
BA_DEF_ BO_ "DiagRequest" ENUM "No","Yes";
BA_DEF_ BO_ "NmMessage" ENUM "No","Yes";
BA_DEF_ BO_ "VFrameFormat" ENUM "StandardCAN","ExtendedCAN","reserved","reserved","reserved","reserved","reserved","reserved","reserved","reserved","reserved","reserved","reserved","reserved","StandardCAN_FD","ExtendedCAN_FD";
BA_DEF_ BO_ "DataID" STRING ;
BA_DEF_ BO_ "DoIPLogicalAddress" STRING ;
BA_DEF_ BO_ "CANFD_BRS" ENUM "0","1";
BA_DEF_ BO_ "GenMsgRequestable" INT 0 1;
BA_DEF_ SG_ "GenSigInvalidValue" HEX 0 0;
BA_DEF_ SG_ "GenSigStartValue" HEX 0 0;
BA_DEF_ SG_ "GenSigInactiveValue" HEX 0 0;
BA_DEF_ SG_ "GenSigRoutingTimeoutValue_String" STRING ;
BA_DEF_ SG_ "DataCenterDataType" STRING ;
BA_DEF_ SG_ "GenSigRoutingTimeoutValue" HEX 0 0;
BA_DEF_ SG_ "GenSigSendType" ENUM "Cycle","OnWrite","OnWriteWithRepetition","OnChange","OnChangeWithRepetition","IfActive","IfActiveWithRepetition","NoSigSendType","vector_leerstring";
BA_DEF_ SG_ "SigType" ENUM "Default","Range","RangeSigned","ASCII","Discrete","Control","ReferencePGN","DTC","StringDelimiter","StringLength","StringLengthControl","MessageCounter","MessageChecksum";
BA_DEF_ SG_ "GenSigILSupport" ENUM "No","Yes";
BA_DEF_ BU_ "NodeLayerModules" STRING ;
BA_DEF_ BU_ "ILUsed" ENUM "No","Yes";
BA_DEF_ BU_ "NmCAN" INT 1 2;
BA_DEF_ BU_ "NmStationAddress" HEX 0 255;
BA_DEF_ BU_ "CANFD_CANFD_Gateway" ENUM "Yes","No";
BA_DEF_ BU_ "BootloaderNode" ENUM "No","Yes";
BA_DEF_DEF_ "NmType" "AUTOSAR";
BA_DEF_DEF_ "VersionYear" 2024;
BA_DEF_DEF_ "ProtocolType" "CAN";
BA_DEF_DEF_ "NmMessageCount" 128;
BA_DEF_DEF_ "NmBaseAddress" 1280;
BA_DEF_DEF_ "Manufacturer" "";
BA_DEF_DEF_ "DBName" "";
BA_DEF_DEF_ "BusType" "CAN";
BA_DEF_DEF_ "Baudrate" 500000;
BA_DEF_DEF_ "Datarate" 2000000;
BA_DEF_DEF_ "GenMsgSendType" "Cycle";
BA_DEF_DEF_ "GenMsgNrOfRepetition" 0;
BA_DEF_DEF_ "GenMsgILSupport" "Yes";
BA_DEF_DEF_ "GenMsgCycleTime" 100;
BA_DEF_DEF_ "DiagResponse" "No";
BA_DEF_DEF_ "DiagRequest" "No";
BA_DEF_DEF_ "NmMessage" "No";
BA_DEF_DEF_ "VFrameFormat" "StandardCAN";
BA_DEF_DEF_ "DataID" "";
BA_DEF_DEF_ "DoIPLogicalAddress" "";
BA_DEF_DEF_ "CANFD_BRS" "1";
BA_DEF_DEF_ "GenMsgRequestable" 1;
BA_DEF_DEF_ "GenSigInvalidValue" 0;
BA_DEF_DEF_ "GenSigStartValue" 0;
BA_DEF_DEF_ "GenSigInactiveValue" 0;
BA_DEF_DEF_ "GenSigRoutingTimeoutValue_String" "";
BA_DEF_DEF_ "DataCenterDataType" "";
BA_DEF_DEF_ "GenSigRoutingTimeoutValue" 0;
BA_DEF_DEF_ "GenSigSendType" "Cycle";
BA_DEF_DEF_ "SigType" "Default";
BA_DEF_DEF_ "GenSigILSupport" "Yes";
BA_DEF_DEF_ "NodeLayerModules" "CANoeILNLVector.dll";
BA_DEF_DEF_ "ILUsed" "Yes";
BA_DEF_DEF_ "NmCAN" 2;
BA_DEF_DEF_ "NmStationAddress" 0;
BA_DEF_DEF_ "CANFD_CANFD_Gateway" "No";
BA_DEF_DEF_ "BootloaderNode" "No";
BA_ "BusType" "CAN FD";
BA_ "ProtocolType" "CAN FD";
BA_ "Manufacturer" "FVT";
BA_ "DBName" "CAN1";
BA_ "CANFD_CANFD_Gateway" BU_ FUSION 0;
BA_ "BootloaderNode" BU_ ABM 1;
BA_ "BootloaderNode" BU_ EPS 1;
BA_ "BootloaderNode" BU_ ESC 1;
BA_ "BootloaderNode" BU_ eBST 1;
BA_ "GenMsgNrOfRepetition" BO_ 515 1;
BA_ "GenMsgCycleTime" BO_ 515 500;
BA_ "DataID" BO_ 515 "0xE4F2";
BA_ "GenMsgSendType" BO_ 515 5;
BA_ "VFrameFormat" BO_ 515 14;
BA_ "GenMsgCycleTime" BO_ 1585 0;
BA_ "DiagResponse" BO_ 1585 1;
BA_ "GenMsgSendType" BO_ 1585 3;
BA_ "VFrameFormat" BO_ 1585 14;
BA_ "DoIPLogicalAddress" BO_ 1585 "0x06B1";
BA_ "GenMsgCycleTime" BO_ 391 10;
BA_ "DataID" BO_ 391 "0xB18E";
BA_ "VFrameFormat" BO_ 391 14;
BA_ "GenMsgCycleTime" BO_ 338 10;
BA_ "DataID" BO_ 338 "0x5FB3";
BA_ "VFrameFormat" BO_ 338 14;
BA_ "GenMsgCycleTime" BO_ 421 10;
BA_ "DataID" BO_ 421 "0x6E59";
BA_ "VFrameFormat" BO_ 421 14;
BA_ "GenMsgCycleTime" BO_ 427 40;
BA_ "DataID" BO_ 427 "0x7A2B";
BA_ "VFrameFormat" BO_ 427 14;
BA_ "GenMsgCycleTime" BO_ 1281 0;
BA_ "NmMessage" BO_ 1281 1;
BA_ "GenMsgSendType" BO_ 1281 3;
BA_ "GenMsgNrOfRepetition" BO_ 278 1;
BA_ "GenMsgSendType" BO_ 278 5;
BA_ "VFrameFormat" BO_ 278 14;
BA_ "GenMsgCycleTime" BO_ 340 10;
BA_ "DataID" BO_ 340 "0xA62D";
BA_ "VFrameFormat" BO_ 340 14;
BA_ "GenMsgCycleTime" BO_ 1280 0;
BA_ "NmMessage" BO_ 1280 1;
BA_ "GenMsgSendType" BO_ 1280 3;
BA_ "GenMsgCycleTime" BO_ 1713 0;
BA_ "DiagRequest" BO_ 1713 1;
BA_ "GenMsgSendType" BO_ 1713 3;
BA_ "VFrameFormat" BO_ 1713 14;
BA_ "DoIPLogicalAddress" BO_ 1713 "0x06B1";
BA_ "GenMsgCycleTime" BO_ 2000 0;
BA_ "DiagRequest" BO_ 2000 1;
BA_ "GenMsgSendType" BO_ 2000 3;
BA_ "DoIPLogicalAddress" BO_ 2000 "0xEFFF";
BA_ "GenMsgCycleTime" BO_ 1297 700;
BA_ "NmMessage" BO_ 1297 1;
BA_ "GenMsgNrOfRepetition" BO_ 1168 1;
BA_ "GenMsgCycleTime" BO_ 1168 500;
BA_ "GenMsgSendType" BO_ 1168 5;
BA_ "VFrameFormat" BO_ 1168 14;
BA_ "GenMsgCycleTime" BO_ 1569 0;
BA_ "DiagResponse" BO_ 1569 1;
BA_ "GenMsgSendType" BO_ 1569 3;
BA_ "VFrameFormat" BO_ 1569 14;
BA_ "DoIPLogicalAddress" BO_ 1569 "0x06A1";
BA_ "GenMsgCycleTime" BO_ 370 10;
BA_ "DataID" BO_ 370 "0xC932";
BA_ "VFrameFormat" BO_ 370 14;
BA_ "GenMsgNrOfRepetition" BO_ 383 1;
BA_ "GenMsgCycleTime" BO_ 383 10;
BA_ "GenMsgSendType" BO_ 383 5;
BA_ "VFrameFormat" BO_ 383 14;
BA_ "GenMsgCycleTime" BO_ 568 10;
BA_ "DataID" BO_ 568 "0xD8BD";
BA_ "VFrameFormat" BO_ 568 14;
BA_ "GenMsgCycleTime" BO_ 1697 0;
BA_ "DiagRequest" BO_ 1697 1;
BA_ "GenMsgSendType" BO_ 1697 3;
BA_ "VFrameFormat" BO_ 1697 14;
BA_ "DoIPLogicalAddress" BO_ 1697 "0x06A1";
BA_ "GenMsgCycleTime" BO_ 1537 0;
BA_ "DiagResponse" BO_ 1537 1;
BA_ "GenMsgSendType" BO_ 1537 3;
BA_ "DoIPLogicalAddress" BO_ 1537 "0x0681";
BA_ "GenMsgCycleTime" BO_ 345 10;
BA_ "DataID" BO_ 345 "0xEBC8";
BA_ "VFrameFormat" BO_ 345 14;
BA_ "VFrameFormat" BO_ 386 14;
BA_ "GenMsgNrOfRepetition" BO_ 534 1;
BA_ "GenMsgCycleTime" BO_ 534 200;
BA_ "GenMsgSendType" BO_ 534 5;
BA_ "VFrameFormat" BO_ 534 14;
BA_ "GenMsgCycleTime" BO_ 1665 0;
BA_ "DiagRequest" BO_ 1665 1;
BA_ "GenMsgSendType" BO_ 1665 3;
BA_ "DoIPLogicalAddress" BO_ 1665 "0x0681";
BA_ "GenMsgNrOfRepetition" BO_ 602 1;
BA_ "GenMsgSendType" BO_ 602 5;
BA_ "VFrameFormat" BO_ 602 14;
BA_ "GenMsgCycleTime" BO_ 528 20;
BA_ "VFrameFormat" BO_ 528 14;
BA_ "GenMsgCycleTime" BO_ 1681 0;
BA_ "DiagRequest" BO_ 1681 1;
BA_ "GenMsgSendType" BO_ 1681 3;
BA_ "DoIPLogicalAddress" BO_ 1681 "0x0691";
BA_ "GenMsgCycleTime" BO_ 360 10;
BA_ "VFrameFormat" BO_ 360 14;
BA_ "GenMsgCycleTime" BO_ 1553 0;
BA_ "DiagResponse" BO_ 1553 1;
BA_ "GenMsgSendType" BO_ 1553 3;
BA_ "DoIPLogicalAddress" BO_ 1553 "0x0691";
BA_ "GenMsgCycleTime" BO_ 119 500;
BA_ "VFrameFormat" BO_ 119 14;
BA_ "GenMsgNrOfRepetition" BO_ 575 1;
BA_ "GenMsgSendType" BO_ 575 5;
BA_ "VFrameFormat" BO_ 575 14;
BA_ "GenMsgCycleTime" BO_ 1698 0;
BA_ "DiagRequest" BO_ 1698 1;
BA_ "GenMsgSendType" BO_ 1698 3;
BA_ "VFrameFormat" BO_ 1698 14;
BA_ "DoIPLogicalAddress" BO_ 1698 "0x06A2";
BA_ "GenMsgCycleTime" BO_ 1570 0;
BA_ "DiagResponse" BO_ 1570 1;
BA_ "GenMsgSendType" BO_ 1570 3;
BA_ "VFrameFormat" BO_ 1570 14;
BA_ "DoIPLogicalAddress" BO_ 1570 "0x06A2";
BA_ "GenMsgCycleTime" BO_ 1314 0;
BA_ "NmMessage" BO_ 1314 1;
BA_ "GenMsgSendType" BO_ 1314 3;
BA_ "GenMsgCycleTime" BO_ 2015 0;
BA_ "DiagRequest" BO_ 2015 1;
BA_ "GenMsgSendType" BO_ 2015 3;
BA_ "VFrameFormat" BO_ 2015 14;
BA_ "DoIPLogicalAddress" BO_ 2015 "0xE000 ";
BA_ "GenMsgCycleTime" BO_ 2033 0;
BA_ "DiagRequest" BO_ 2033 1;
BA_ "GenMsgSendType" BO_ 2033 3;
BA_ "VFrameFormat" BO_ 2033 14;
BA_ "DoIPLogicalAddress" BO_ 2033 "0xE002";
BA_ "GenMsgCycleTime" BO_ 2041 0;
BA_ "DiagResponse" BO_ 2041 1;
BA_ "GenMsgSendType" BO_ 2041 3;
BA_ "VFrameFormat" BO_ 2041 14;
BA_ "DoIPLogicalAddress" BO_ 2041 "0xE002";
BA_ "GenMsgNrOfRepetition" BO_ 1173 1;
BA_ "GenMsgCycleTime" BO_ 1173 200;
BA_ "GenMsgSendType" BO_ 1173 5;
BA_ "VFrameFormat" BO_ 1173 14;
BA_ "GenSigSendType" SG_ 515 Checksum_ABM1 3;
BA_ "GenSigSendType" SG_ 515 LifeCount_ABM1 3;
BA_ "GenSigInvalidValue" SG_ 515 CrashOutputSts 255;
BA_ "GenSigRoutingTimeoutValue_String" SG_ 515 CrashOutputSts "0xFF";
BA_ "GenSigRoutingTimeoutValue" SG_ 515 CrashOutputSts 255;
BA_ "GenSigSendType" SG_ 515 CrashOutputSts 3;
BA_ "DataCenterDataType" SG_ 515 CrashOutputSts "Varchar(20)";
BA_ "GenSigSendType" SG_ 515 TRHPsngrSeatBeltCmd 3;
BA_ "GenSigRoutingTimeoutValue_String" SG_ 515 AirBagFailCmd "0x1";
BA_ "GenSigRoutingTimeoutValue" SG_ 515 AirBagFailCmd 1;
BA_ "GenSigSendType" SG_ 515 AirBagFailCmd 3;
BA_ "DataCenterDataType" SG_ 515 AirBagFailCmd "Varchar(10)";
BA_ "GenSigSendType" SG_ 515 DriverSeatBeltCmd 3;
BA_ "GenSigSendType" SG_ 515 PsngrSeatBeltCmd 3;
BA_ "GenSigSendType" SG_ 515 PABSwitchCmd 3;
BA_ "GenSigSendType" SG_ 515 RDriverSeatBeltCmd 3;
BA_ "GenSigSendType" SG_ 515 RPsngrSeatBeltCmd 3;
BA_ "GenSigSendType" SG_ 515 RCenterSeatBeltCmd 3;
BA_ "GenSigSendType" SG_ 515 TLHPsngrSeatBeltCmd 3;
BA_ "GenSigSendType" SG_ 515 ABM_Passenger_ODS_Sta 3;
BA_ "GenSigSendType" SG_ 515 ABM_RearPassengerLH_ODS_Sta 3;
BA_ "GenSigSendType" SG_ 515 ABM_RearPassengerCTR_ODS_Sta 3;
BA_ "GenSigSendType" SG_ 515 ABM_RearPassengerRH_ODS_Sta 3;
BA_ "GenSigSendType" SG_ 1585 DiagRespFromABM 3;
BA_ "GenSigInvalidValue" SG_ 391 SAS_Angle 65535;
BA_ "GenSigStartValue" SG_ 391 SAS_Angle 9000;
BA_ "GenSigRoutingTimeoutValue_String" SG_ 391 SAS_Angle "0xFFFF";
BA_ "GenSigRoutingTimeoutValue" SG_ 391 SAS_Angle 65535;
BA_ "GenSigStartValue" SG_ 391 EPS_Pwr_Limit_V 1;
BA_ "GenSigStartValue" SG_ 391 Steering_Torque_V 1;
BA_ "GenSigStartValue" SG_ 391 EPS_Pwr_Consumpt_V 1;
BA_ "GenSigStartValue" SG_ 391 EPS_Temp 100;
BA_ "GenSigStartValue" SG_ 391 EPS_VOL_V 1;
BA_ "GenSigStartValue" SG_ 391 EPS_Temp_V 1;
BA_ "DataCenterDataType" SG_ 391 EpasFailed "Varchar(10)";
BA_ "GenSigInvalidValue" SG_ 391 EPS_ESABoostOut_Trq 63;
BA_ "GenSigStartValue" SG_ 391 EPS_ESABoostOut_Trq 30;
BA_ "GenSigRoutingTimeoutValue_String" SG_ 391 EPS_ESABoostOut_Trq "0x3F";
BA_ "GenSigInactiveValue" SG_ 391 EPS_ESABoostOut_Trq 63;
BA_ "GenSigRoutingTimeoutValue" SG_ 391 EPS_ESABoostOut_Trq 63;
BA_ "GenSigRoutingTimeoutValue_String" SG_ 391 EPS_ESAInpBoost_Sta "0x0";
BA_ "GenSigRoutingTimeoutValue_String" SG_ 391 EPS_DMSMode_Sta "0x0";
BA_ "GenSigInvalidValue" SG_ 338 VehSpeed 4095;
BA_ "GenSigRoutingTimeoutValue_String" SG_ 338 VehSpeed "0xFFF";
BA_ "GenSigInactiveValue" SG_ 338 VehSpeed 4095;
BA_ "GenSigRoutingTimeoutValue" SG_ 338 VehSpeed 4095;
BA_ "DataCenterDataType" SG_ 338 VehSpeed "Varchar(7)";
BA_ "GenSigInvalidValue" SG_ 338 RF_PulseCount_V 1;
BA_ "GenSigInvalidValue" SG_ 338 FrntAxlTrqReq_Drv 65535;
BA_ "GenSigStartValue" SG_ 338 FrntAxlTrqReq_Drv 10600;
BA_ "GenSigInvalidValue" SG_ 338 RearAxlTrqReq_Drv 65535;
BA_ "GenSigStartValue" SG_ 338 RearAxlTrqReq_Drv 10600;
BA_ "GenSigInvalidValue" SG_ 338 LF_PulseCount_V 1;
BA_ "GenSigInvalidValue" SG_ 338 RF_RawWhlSpeed_V 1;
BA_ "GenSigInvalidValue" SG_ 338 LF_RawWhlSpeed_V 1;
BA_ "GenSigInvalidValue" SG_ 338 RR_PulseCount_V 1;
BA_ "GenSigInvalidValue" SG_ 338 RR_RawWhlSpeed_V 1;
BA_ "GenSigInvalidValue" SG_ 338 LR_PulseCount_V 1;
BA_ "GenSigInvalidValue" SG_ 338 LR_RawWhlSpeed_V 1;
BA_ "GenSigInvalidValue" SG_ 338 SystemVoltage 255;
BA_ "DataCenterDataType" SG_ 338 TCS_Failed "Varchar(7)";
BA_ "DataCenterDataType" SG_ 338 ESC_Failed "Varchar(7)";
BA_ "GenSigRoutingTimeoutValue_String" SG_ 338 Amber_WnlmpSta "0x1";
BA_ "GenSigRoutingTimeoutValue" SG_ 338 Amber_WnlmpSta 1;
BA_ "DataCenterDataType" SG_ 338 EBD_Failed "Varchar(7)";
BA_ "DataCenterDataType" SG_ 338 ABS_Failed "Varchar(7)";
BA_ "GenSigRoutingTimeoutValue_String" SG_ 338 ESC_WnlmpSta "0x1";
BA_ "GenSigRoutingTimeoutValue" SG_ 338 ESC_WnlmpSta 1;
BA_ "GenSigInvalidValue" SG_ 338 GRADE 255;
BA_ "GenSigStartValue" SG_ 338 GRADE 127;
BA_ "GenSigRoutingTimeoutValue_String" SG_ 338 Red_WnlmpSta "0x1";
BA_ "GenSigRoutingTimeoutValue" SG_ 338 Red_WnlmpSta 1;
BA_ "GenSigRoutingTimeoutValue_String" SG_ 338 ABS_WnlmpSta "0x1";
BA_ "GenSigRoutingTimeoutValue" SG_ 338 ABS_WnlmpSta 1;
BA_ "GenSigRoutingTimeoutValue_String" SG_ 338 ESC_Off_lmpSta "0x1";
BA_ "GenSigRoutingTimeoutValue" SG_ 338 ESC_Off_lmpSta 1;
BA_ "GenSigRoutingTimeoutValue_String" SG_ 338 ESC_EstVehSpd "0x0";
BA_ "GenSigRoutingTimeoutValue_String" SG_ 338 ESC_TSA_Active "0x0";
BA_ "GenSigInvalidValue" SG_ 338 ESC_EstVehSpd_V 1;
BA_ "GenSigRoutingTimeoutValue_String" SG_ 338 ESC_EstVehSpd_V "0x1";
BA_ "GenSigRoutingTimeoutValue" SG_ 338 ESC_EstVehSpd_V 1;
BA_ "GenSigInvalidValue" SG_ 421 YawRate_V 1;
BA_ "GenSigInvalidValue" SG_ 421 LatAccel_V 1;
BA_ "GenSigInvalidValue" SG_ 421 LongAccel_V 1;
BA_ "GenSigInvalidValue" SG_ 421 MCPressure_V 1;
BA_ "GenSigRoutingTimeoutValue_String" SG_ 421 MCPressure_V "0x1";
BA_ "GenSigRoutingTimeoutValue" SG_ 421 MCPressure_V 1;
BA_ "GenSigRoutingTimeoutValue_String" SG_ 421 BrkSw_Sta "0x0";
BA_ "GenSigInvalidValue" SG_ 421 BrkSw_V 1;
BA_ "GenSigRoutingTimeoutValue_String" SG_ 421 BrkSw_V "0x1";
BA_ "GenSigRoutingTimeoutValue" SG_ 421 BrkSw_V 1;
BA_ "GenSigInvalidValue" SG_ 421 MCPressure 4095;
BA_ "GenSigStartValue" SG_ 421 MCPressure 97;
BA_ "GenSigRoutingTimeoutValue_String" SG_ 421 MCPressure "0xFFF";
BA_ "GenSigRoutingTimeoutValue" SG_ 421 MCPressure 4095;
BA_ "GenSigInvalidValue" SG_ 421 LongAccel 255;
BA_ "GenSigStartValue" SG_ 421 LongAccel 127;
BA_ "GenSigInvalidValue" SG_ 421 LatAccel 255;
BA_ "GenSigStartValue" SG_ 421 LatAccel 127;
BA_ "GenSigInvalidValue" SG_ 421 YawRate 2047;
BA_ "GenSigStartValue" SG_ 421 YawRate 1000;
BA_ "GenSigRoutingTimeoutValue_String" SG_ 421 ActBrkLamp_Sta "0x0";
BA_ "GenSigRoutingTimeoutValue_String" SG_ 421 BrkPedalPos_Sta "0x0";
BA_ "GenSigInvalidValue" SG_ 421 Meter_Ind_VehSpeed 4095;
BA_ "GenSigRoutingTimeoutValue_String" SG_ 421 Meter_Ind_VehSpeed "0xFFF";
BA_ "GenSigInactiveValue" SG_ 421 Meter_Ind_VehSpeed 4095;
BA_ "GenSigRoutingTimeoutValue" SG_ 421 Meter_Ind_VehSpeed 4095;
BA_ "GenSigInvalidValue" SG_ 421 BrkPedalPos 255;
BA_ "GenSigRoutingTimeoutValue_String" SG_ 421 BrkPedalPos "0xFF";
BA_ "GenSigRoutingTimeoutValue" SG_ 421 BrkPedalPos 255;
BA_ "GenSigInvalidValue" SG_ 421 RearAxlTrqReq_Brk 65535;
BA_ "GenSigStartValue" SG_ 421 RearAxlTrqReq_Brk 10600;
BA_ "GenSigInvalidValue" SG_ 421 FrntAxlTrqReq_Brk 65535;
BA_ "GenSigStartValue" SG_ 421 FrntAxlTrqReq_Brk 10600;
BA_ "GenSigRoutingTimeoutValue_String" SG_ 421 ESC_DriverBrkOverride "0x0";
BA_ "GenSigInvalidValue" SG_ 427 EPBStaR 7;
BA_ "DataCenterDataType" SG_ 427 EPBErrSta "Varchar(20)";
BA_ "GenSigInvalidValue" SG_ 427 EPBStaL 7;
BA_ "GenSigSendType" SG_ 1281 NM_ESC_Node_ID 7;
BA_ "GenSigSendType" SG_ 1281 NM_ESC_Rpt_Msg_Req 7;
BA_ "GenSigSendType" SG_ 1281 NM_ESC_CSB 7;
BA_ "GenSigSendType" SG_ 1281 NM_ESC_Active_WU 7;
BA_ "GenSigSendType" SG_ 1281 NM_ESC_PNI 7;
BA_ "GenSigSendType" SG_ 1281 NM_ESC_ERROR_State 7;
BA_ "GenSigSendType" SG_ 278 PrkReqValid 3;
BA_ "GenSigInvalidValue" SG_ 278 P_Button_Sta 2;
BA_ "GenSigRoutingTimeoutValue_String" SG_ 278 P_Button_Sta "0x2";
BA_ "GenSigRoutingTimeoutValue" SG_ 278 P_Button_Sta 2;
BA_ "GenSigSendType" SG_ 278 P_Button_Sta 3;
BA_ "GenSigInvalidValue" SG_ 278 CC_Crl_Sta 6;
BA_ "GenSigSendType" SG_ 278 CC_Crl_Sta 3;
BA_ "DataCenterDataType" SG_ 278 CC_Crl_Sta "varchar(25)";
BA_ "GenSigInvalidValue" SG_ 278 MSA_Crl_Sta 6;
BA_ "GenSigRoutingTimeoutValue_String" SG_ 278 MSA_Crl_Sta "0x6";
BA_ "GenSigInactiveValue" SG_ 278 MSA_Crl_Sta 6;
BA_ "GenSigRoutingTimeoutValue" SG_ 278 MSA_Crl_Sta 6;
BA_ "GenSigSendType" SG_ 278 MSA_Crl_Sta 3;
BA_ "DataCenterDataType" SG_ 278 MSA_Crl_Sta "varchar(25)";
BA_ "GenSigInvalidValue" SG_ 278 ShiftGearPosn 1;
BA_ "GenSigStartValue" SG_ 278 ShiftGearPosn 1;
BA_ "GenSigRoutingTimeoutValue_String" SG_ 278 ShiftGearPosn "0x1";
BA_ "GenSigInactiveValue" SG_ 278 ShiftGearPosn 1;
BA_ "GenSigRoutingTimeoutValue" SG_ 278 ShiftGearPosn 1;
BA_ "GenSigSendType" SG_ 278 ShiftGearPosn 3;
BA_ "DataCenterDataType" SG_ 278 ShiftGearPosn "Varchar(10)";
BA_ "GenSigSendType" SG_ 278 PrkReq 3;
BA_ "GenSigSendType" SG_ 278 XWDMode 3;
BA_ "GenSigSendType" SG_ 278 LVPwrSta 3;
BA_ "GenSigSendType" SG_ 278 HVPwrSta 3;
BA_ "GenSigInvalidValue" SG_ 278 PwrSta 7;
BA_ "GenSigStartValue" SG_ 278 PwrSta 7;
BA_ "GenSigRoutingTimeoutValue_String" SG_ 278 PwrSta "0x7";
BA_ "GenSigInactiveValue" SG_ 278 PwrSta 7;
BA_ "GenSigRoutingTimeoutValue" SG_ 278 PwrSta 7;
BA_ "GenSigSendType" SG_ 278 PwrSta 3;
BA_ "DataCenterDataType" SG_ 278 PwrSta "Varchar(15)";
BA_ "GenSigSendType" SG_ 278 Eng_AGSCloseSta 3;
BA_ "GenSigInvalidValue" SG_ 278 Eng_PwrLockSta 2;
BA_ "GenSigRoutingTimeoutValue_String" SG_ 278 Eng_PwrLockSta "0x2";
BA_ "GenSigRoutingTimeoutValue" SG_ 278 Eng_PwrLockSta 2;
BA_ "GenSigSendType" SG_ 278 Eng_PwrLockSta 3;
BA_ "GenSigInvalidValue" SG_ 278 Eng_CoastDwSta 2;
BA_ "GenSigRoutingTimeoutValue_String" SG_ 278 Eng_CoastDwSta "0x2";
BA_ "GenSigRoutingTimeoutValue" SG_ 278 Eng_CoastDwSta 2;
BA_ "GenSigSendType" SG_ 278 Eng_CoastDwSta 3;
BA_ "GenSigInvalidValue" SG_ 278 Eng_ActvDmpDisabSta 2;
BA_ "GenSigRoutingTimeoutValue_String" SG_ 278 Eng_ActvDmpDisabSta "0x2";
BA_ "GenSigRoutingTimeoutValue" SG_ 278 Eng_ActvDmpDisabSta 2;
BA_ "GenSigSendType" SG_ 278 Eng_ActvDmpDisabSta 3;
BA_ "GenSigSendType" SG_ 278 VehMalfunLevel 3;
BA_ "GenSigStartValue" SG_ 340 Fr_DriverTq 10600;
BA_ "GenSigStartValue" SG_ 340 Rr_DriverTq 10600;
BA_ "GenSigStartValue" SG_ 340 VehActPwr 600000;
BA_ "GenSigStartValue" SG_ 340 DriverTq 4300;
BA_ "GenSigSendType" SG_ 1280 NM_FUSION_Node_ID 7;
BA_ "GenSigSendType" SG_ 1280 NM_FUSION_Rpt_Msg_Req 7;
BA_ "GenSigSendType" SG_ 1280 NM_FUSION_CSB 7;
BA_ "GenSigSendType" SG_ 1280 NM_FUSION_Active_WU 7;
BA_ "GenSigSendType" SG_ 1280 NM_FUSION_PNI 7;
BA_ "GenSigSendType" SG_ 1280 NM_FUSION_ERROR_State 7;
BA_ "GenSigSendType" SG_ 1713 DiagPhysReqToABM 3;
BA_ "GenSigSendType" SG_ 2000 DiagFuncReqFT 3;
BA_ "GenSigSendType" SG_ 1297 NM_eBST_Node_ID 7;
BA_ "GenSigSendType" SG_ 1297 NM_eBST_Rpt_Msg_Req 7;
BA_ "GenSigSendType" SG_ 1297 NM_eBST_CSB 7;
BA_ "GenSigSendType" SG_ 1297 NM_eBST_Active_WU 7;
BA_ "GenSigSendType" SG_ 1297 NM_eBST_PNI 7;
BA_ "GenSigSendType" SG_ 1297 NM_eBST_ERROR_State 7;
BA_ "GenSigInvalidValue" SG_ 1168 VehACModReq 7;
BA_ "GenSigRoutingTimeoutValue_String" SG_ 1168 VehACModReq "0x7";
BA_ "GenSigRoutingTimeoutValue" SG_ 1168 VehACModReq 7;
BA_ "GenSigSendType" SG_ 1168 VehACModReq 3;
BA_ "GenSigSendType" SG_ 1168 FCP_FrEvt_BtnACMaxReq 3;
BA_ "GenSigSendType" SG_ 1168 FCP_FrEvt_BtnACReq 3;
BA_ "DataCenterDataType" SG_ 1168 FCP_FrEvt_BtnACReq "Varchar(10)";
BA_ "GenSigSendType" SG_ 1168 FCP_FrEvt_BtnAutoReq 3;
BA_ "GenSigSendType" SG_ 1168 FCP_MidEvt_BtnAutoReq 3;
BA_ "GenSigSendType" SG_ 1168 FCP_FrEvt_BtnSyncReq 3;
BA_ "GenSigSendType" SG_ 1168 OTA_DL_Req 3;
BA_ "GenSigSendType" SG_ 1168 OTA_SuspendDL_Req 3;
BA_ "GenSigSendType" SG_ 1168 OTA_UpdStart_Req 3;
BA_ "GenSigSendType" SG_ 1168 IVI_OTA_Upd_Sta 3;
BA_ "GenSigSendType" SG_ 1168 OTA_CancelDL_Req 3;
BA_ "GenSigSendType" SG_ 1168 SmartEco_Mode_SW 3;
BA_ "GenSigSendType" SG_ 1168 LINKtoDrive 3;
BA_ "GenSigSendType" SG_ 1168 Upd_Countdown_Skip 3;
BA_ "GenSigSendType" SG_ 1168 Upd_Countdown_Cancel 3;
BA_ "GenSigInvalidValue" SG_ 1168 AmbLightColorSet 127;
BA_ "GenSigStartValue" SG_ 1168 AmbLightColorSet 64;
BA_ "GenSigRoutingTimeoutValue_String" SG_ 1168 AmbLightColorSet "0x7F";
BA_ "GenSigInactiveValue" SG_ 1168 AmbLightColorSet 64;
BA_ "GenSigRoutingTimeoutValue" SG_ 1168 AmbLightColorSet 127;
BA_ "GenSigSendType" SG_ 1168 AmbLightColorSet 3;
BA_ "GenSigSendType" SG_ 1168 Sched_OTA_wake 3;
BA_ "GenSigSendType" SG_ 1168 UserSet 3;
BA_ "GenSigInvalidValue" SG_ 1168 AmbLightBrightnessSet 127;
BA_ "GenSigStartValue" SG_ 1168 AmbLightBrightnessSet 101;
BA_ "GenSigRoutingTimeoutValue_String" SG_ 1168 AmbLightBrightnessSet "0x7F";
BA_ "GenSigInactiveValue" SG_ 1168 AmbLightBrightnessSet 101;
BA_ "GenSigRoutingTimeoutValue" SG_ 1168 AmbLightBrightnessSet 127;
BA_ "GenSigSendType" SG_ 1168 AmbLightBrightnessSet 3;
BA_ "GenSigSendType" SG_ 1168 Sched_Chg_Day_Set 3;
BA_ "GenSigSendType" SG_ 1168 Re_Radio_Sta 3;
BA_ "GenSigSendType" SG_ 1168 Sched_Chg_St_Time_Min 3;
BA_ "GenSigSendType" SG_ 1168 A2B_Node_sta 3;
BA_ "GenSigInvalidValue" SG_ 1168 Sched_Chg_St_Time_HR 31;
BA_ "GenSigSendType" SG_ 1168 Sched_Chg_St_Time_HR 3;
BA_ "GenSigInvalidValue" SG_ 1168 IVI_Located_STA 3;
BA_ "GenSigStartValue" SG_ 1168 IVI_Located_STA 3;
BA_ "GenSigRoutingTimeoutValue_String" SG_ 1168 IVI_Located_STA "0x3";
BA_ "GenSigInactiveValue" SG_ 1168 IVI_Located_STA 3;
BA_ "GenSigRoutingTimeoutValue" SG_ 1168 IVI_Located_STA 3;
BA_ "GenSigSendType" SG_ 1168 IVI_Located_STA 3;
BA_ "DataCenterDataType" SG_ 1168 IVI_Located_STA "Varchar(10)";
BA_ "GenSigSendType" SG_ 1168 Sched_Chg_End_Time_Min 3;
BA_ "GenSigSendType" SG_ 1168 OTA_CompNTFY_Pres 3;
BA_ "GenSigSendType" SG_ 1168 BrkAbn_GoReady_SW 3;
BA_ "GenSigInvalidValue" SG_ 1168 Sched_Chg_End_Time_HR 31;
BA_ "GenSigSendType" SG_ 1168 Sched_Chg_End_Time_HR 3;
BA_ "GenSigSendType" SG_ 1168 PW_CONTINUE_USE 3;
BA_ "GenSigSendType" SG_ 1168 PW_CLOSE_IMD 3;
BA_ "GenSigSendType" SG_ 1168 mFRD_link_Sta 3;
BA_ "GenSigSendType" SG_ 1168 AmbLight_SW 3;
BA_ "GenSigSendType" SG_ 1168 AmbLight_DimInDark_SW 3;
BA_ "GenSigSendType" SG_ 1168 AmbLight_WlcmLight_SW 3;
BA_ "GenSigSendType" SG_ 1168 AmbLigh_LowBatAlert_SW 3;
BA_ "GenSigSendType" SG_ 1168 AmbLigh_SafetyAlert_SW 3;
BA_ "GenSigSendType" SG_ 1168 OpenDrOpenWdo_SW 3;
BA_ "GenSigSendType" SG_ 1168 IVI_LinkKey_Sta 3;
BA_ "GenSigSendType" SG_ 1168 IVI_CreateAccReq_Sta 3;
BA_ "GenSigSendType" SG_ 1168 IVI_DelAccReq_Sta 3;
BA_ "GenSigSendType" SG_ 1168 IVI_LinkAcc_Sta 3;
BA_ "GenSigSendType" SG_ 1168 IVI_LinkAccReq_Sta 3;
BA_ "GenSigSendType" SG_ 1168 IVI_FrTrunk_UnlockReq_Sta 3;
BA_ "GenSigSendType" SG_ 1168 IVI_CLWin_LockDoorSW_Sta 3;
BA_ "GenSigSendType" SG_ 1168 IVI_Lock_SoundSW_Sta 3;
BA_ "GenSigSendType" SG_ 1168 IVI_SWC_VibMode_Sta 3;
BA_ "GenSigSendType" SG_ 1168 IVI_DMS_SW_Sta 3;
BA_ "GenSigSendType" SG_ 1168 IVI_AirRefresh_ByDMS_Sta 3;
BA_ "GenSigSendType" SG_ 1168 IVI_QuickRefresh_Sta 3;
BA_ "GenSigRoutingTimeoutValue_String" SG_ 1168 IVI_HMI_Undefined_Sta "0x0";
BA_ "GenSigSendType" SG_ 1168 IVI_HMI_Undefined_Sta 3;
BA_ "GenSigRoutingTimeoutValue_String" SG_ 1168 IVI_AutoTheme_But_Sta "0x0";
BA_ "GenSigSendType" SG_ 1168 IVI_AutoTheme_But_Sta 3;
BA_ "GenSigRoutingTimeoutValue_String" SG_ 1168 IVI_NAVI_Foreground_Sta "0x0";
BA_ "GenSigSendType" SG_ 1168 IVI_NAVI_Foreground_Sta 3;
BA_ "GenSigRoutingTimeoutValue_String" SG_ 1168 IVI_sigScreenReq_Sta "0x0";
BA_ "GenSigSendType" SG_ 1168 IVI_sigScreenReq_Sta 3;
BA_ "GenSigRoutingTimeoutValue_String" SG_ 1168 IVI_DSEAT_anti_set_Sta "0x0";
BA_ "GenSigSendType" SG_ 1168 IVI_DSEAT_anti_set_Sta 3;
BA_ "GenSigRoutingTimeoutValue_String" SG_ 1168 IVI_MirrorFolded_SW_Sta "0x0";
BA_ "GenSigSendType" SG_ 1168 IVI_MirrorFolded_SW_Sta 3;
BA_ "GenSigRoutingTimeoutValue_String" SG_ 1168 IVI_WPTC_SW_Sta "0x0";
BA_ "GenSigSendType" SG_ 1168 IVI_WPTC_SW_Sta 3;
BA_ "GenSigRoutingTimeoutValue_String" SG_ 1168 IVI_Driving_Lock_SW_Sta "0x0";
BA_ "GenSigSendType" SG_ 1168 IVI_Driving_Lock_SW_Sta 3;
BA_ "GenSigRoutingTimeoutValue_String" SG_ 1168 IVI_Stopping_Unlock_SW_Sta "0x0";
BA_ "GenSigSendType" SG_ 1168 IVI_Stopping_Unlock_SW_Sta 3;
BA_ "GenSigRoutingTimeoutValue_String" SG_ 1168 IVI_SilentChrg_Alert_Sta "0x0";
BA_ "GenSigSendType" SG_ 1168 IVI_SilentChrg_Alert_Sta 3;
BA_ "DataCenterDataType" SG_ 1168 IVI_SilentChrg_Alert_Sta "varchar(20)";
BA_ "GenSigRoutingTimeoutValue_String" SG_ 1168 IVI_WirelessCharge_Cmd "0x0";
BA_ "GenSigSendType" SG_ 1168 IVI_WirelessCharge_Cmd 3;
BA_ "GenSigRoutingTimeoutValue_String" SG_ 1168 IVI_Theme_Sta "0x0";
BA_ "GenSigSendType" SG_ 1168 IVI_Theme_Sta 3;
BA_ "GenSigRoutingTimeoutValue_String" SG_ 1168 IVI_EPS_Force_Cmd "0x0";
BA_ "GenSigSendType" SG_ 1168 IVI_EPS_Force_Cmd 3;
BA_ "GenSigInvalidValue" SG_ 1168 IVI_DSEAT_StopKeepMove_Sta 3;
BA_ "GenSigRoutingTimeoutValue_String" SG_ 1168 IVI_DSEAT_StopKeepMove_Sta "0x0";
BA_ "GenSigSendType" SG_ 1168 IVI_DSEAT_StopKeepMove_Sta 3;
BA_ "GenSigRoutingTimeoutValue_String" SG_ 1168 IVI_AutoWipHSpdSW_Cmd "0x0";
BA_ "GenSigSendType" SG_ 1168 IVI_AutoWipHSpdSW_Cmd 3;
BA_ "GenSigRoutingTimeoutValue_String" SG_ 1168 IVI_DSEAT_entryfun_set_Sta "0x0";
BA_ "GenSigSendType" SG_ 1168 IVI_DSEAT_entryfun_set_Sta 3;
BA_ "GenSigSendType" SG_ 1569 DiagRespFromEPS 3;
BA_ "GenSigInvalidValue" SG_ 370 VMC_ACC_ComfortBandUpper 511;
BA_ "GenSigInvalidValue" SG_ 370 VMC_ACC_JerkUpperLInit 127;
BA_ "GenSigInvalidValue" SG_ 370 VMC_ACC_ComfortBandLower 511;
BA_ "GenSigInvalidValue" SG_ 370 VMC_ACC_JerkLowerLInit 127;
BA_ "GenSigInvalidValue" SG_ 370 FDC_VMC_DrInpTqBstGn 255;
BA_ "GenSigRoutingTimeoutValue_String" SG_ 370 FDC_VMC_DrInpTqBstGn "0xFF";
BA_ "GenSigInactiveValue" SG_ 370 FDC_VMC_DrInpTqBstGn 255;
BA_ "GenSigRoutingTimeoutValue" SG_ 370 FDC_VMC_DrInpTqBstGn 255;
BA_ "GenSigInvalidValue" SG_ 370 FDC_VMC_AngCtrlTqWtGn 255;
BA_ "GenSigRoutingTimeoutValue_String" SG_ 370 FDC_VMC_AngCtrlTqWtGn "0xFF";
BA_ "GenSigInactiveValue" SG_ 370 FDC_VMC_AngCtrlTqWtGn 255;
BA_ "GenSigRoutingTimeoutValue" SG_ 370 FDC_VMC_AngCtrlTqWtGn 255;
BA_ "GenSigInvalidValue" SG_ 370 FDC_VMC_MaxAngCtrlOutTqLim 511;
BA_ "GenSigRoutingTimeoutValue_String" SG_ 370 FDC_VMC_MaxAngCtrlOutTqLim "0x1FF";
BA_ "GenSigInactiveValue" SG_ 370 FDC_VMC_MaxAngCtrlOutTqLim 511;
BA_ "GenSigRoutingTimeoutValue" SG_ 370 FDC_VMC_MaxAngCtrlOutTqLim 511;
BA_ "GenSigRoutingTimeoutValue_String" SG_ 370 FDC_VMC_DrInpTqBstAct "0x0";
BA_ "GenSigRoutingTimeoutValue_String" SG_ 370 FDC_VMC_DMSMode_Cmd "0x0";
BA_ "GenSigRoutingTimeoutValue_String" SG_ 383 FeatSetSpdFinal_raw32 "0x0";
BA_ "GenSigInvalidValue" SG_ 383 FeatArbitrFinal 6;
BA_ "GenSigInvalidValue" SG_ 383 DISC_DISCTargetSpd 4095;
BA_ "GenSigRoutingTimeoutValue_String" SG_ 383 DISC_DISCTargetSpd "0xFFF";
BA_ "GenSigRoutingTimeoutValue" SG_ 383 DISC_DISCTargetSpd 4095;
BA_ "GenSigSendType" SG_ 383 CCMSA_SpdWar 3;
BA_ "GenSigInvalidValue" SG_ 383 VMC_VCU_CC_Crl_Sta 6;
BA_ "GenSigInvalidValue" SG_ 383 VMC_VCU_MSA_Crl_Sta 6;
BA_ "GenSigInvalidValue" SG_ 383 FeatReqSpd 2047;
BA_ "GenSigInvalidValue" SG_ 383 VehicleSpeed_kph 4095;
BA_ "GenSigInvalidValue" SG_ 383 VehicleSpeed_mph 4095;
BA_ "GenSigInvalidValue" SG_ 568 FDC_VMC_APS_Angle_Target 65535;
BA_ "GenSigRoutingTimeoutValue_String" SG_ 568 APS_Sta_System "0x0";
BA_ "GenSigInvalidValue" SG_ 568 FDC_RAPS_PwrReq_Cmd 4;
BA_ "GenSigRoutingTimeoutValue_String" SG_ 568 FDC_RAPS_PwrReq_Cmd "0x4";
BA_ "GenSigRoutingTimeoutValue" SG_ 568 FDC_RAPS_PwrReq_Cmd 4;
BA_ "GenSigSendType" SG_ 1697 DiagPhysReqToEPS 3;
BA_ "GenSigSendType" SG_ 1537 DiagRespFromESC 3;
BA_ "GenSigInvalidValue" SG_ 345 Rr_EDUSpdValid 1;
BA_ "GenSigRoutingTimeoutValue_String" SG_ 345 Rr_EDUSpdValid "0x1";
BA_ "GenSigRoutingTimeoutValue" SG_ 345 Rr_EDUSpdValid 1;
BA_ "GenSigInvalidValue" SG_ 345 Fr_EDUSpdValid 1;
BA_ "GenSigRoutingTimeoutValue_String" SG_ 345 Fr_EDUSpdValid "0x1";
BA_ "GenSigRoutingTimeoutValue" SG_ 345 Fr_EDUSpdValid 1;
BA_ "GenSigStartValue" SG_ 345 Rr_EDUSpd 2000;
BA_ "GenSigStartValue" SG_ 345 Rr_EDURealARgnTq 5300;
BA_ "GenSigStartValue" SG_ 345 Rr_EDUAvailBrkRgnTq 10600;
BA_ "GenSigStartValue" SG_ 345 Rr_EDURealDrvOrBRgnTq 10600;
BA_ "GenSigStartValue" SG_ 345 Fr_EDUSpd 2000;
BA_ "GenSigInvalidValue" SG_ 345 Fr_EDUAvailBrkRgnTqValid 1;
BA_ "GenSigRoutingTimeoutValue_String" SG_ 345 Fr_EDUAvailBrkRgnTqValid "0x1";
BA_ "GenSigRoutingTimeoutValue" SG_ 345 Fr_EDUAvailBrkRgnTqValid 1;
BA_ "GenSigInvalidValue" SG_ 345 Rr_EDUAvailBrkRgnTqValid 1;
BA_ "GenSigRoutingTimeoutValue_String" SG_ 345 Rr_EDUAvailBrkRgnTqValid "0x1";
BA_ "GenSigRoutingTimeoutValue" SG_ 345 Rr_EDUAvailBrkRgnTqValid 1;
BA_ "GenSigStartValue" SG_ 345 Fr_EDURealARgnTq 5300;
BA_ "GenSigStartValue" SG_ 345 Fr_EDUAvailBrkRgnTq 10600;
BA_ "GenSigStartValue" SG_ 345 Fr_EDURealDrvOrBRgnTq 10600;
BA_ "GenSigStartValue" SG_ 386 Fr_Coolanttemp 40;
BA_ "DataCenterDataType" SG_ 386 CCU_AutoLampSts "Varchar(10)";
BA_ "DataCenterDataType" SG_ 386 CCU_ACLampSts "varchar(10)";
BA_ "GenSigInvalidValue" SG_ 386 sigWindDirZon3St 7;
BA_ "GenSigStartValue" SG_ 386 sigWindDirZon3St 7;
BA_ "GenSigRoutingTimeoutValue_String" SG_ 386 sigWindDirZon3St "0x7";
BA_ "GenSigInactiveValue" SG_ 386 sigWindDirZon3St 7;
BA_ "GenSigRoutingTimeoutValue" SG_ 386 sigWindDirZon3St 7;
BA_ "DataCenterDataType" SG_ 386 sigWindDirZon3St "varchar(30)";
BA_ "GenSigInvalidValue" SG_ 386 sigWindDirZon1St 7;
BA_ "GenSigStartValue" SG_ 386 sigWindDirZon1St 7;
BA_ "GenSigRoutingTimeoutValue_String" SG_ 386 sigWindDirZon1St "0x7";
BA_ "GenSigInactiveValue" SG_ 386 sigWindDirZon1St 7;
BA_ "GenSigRoutingTimeoutValue" SG_ 386 sigWindDirZon1St 7;
BA_ "GenSigInvalidValue" SG_ 386 sigAirIntenZon3St 15;
BA_ "GenSigRoutingTimeoutValue_String" SG_ 386 sigAirIntenZon3St "0xF";
BA_ "GenSigRoutingTimeoutValue" SG_ 386 sigAirIntenZon3St 15;
BA_ "GenSigInvalidValue" SG_ 386 sigAirIntenZon1St 15;
BA_ "GenSigRoutingTimeoutValue_String" SG_ 386 sigAirIntenZon1St "0xF";
BA_ "GenSigRoutingTimeoutValue" SG_ 386 sigAirIntenZon1St 15;
BA_ "DataCenterDataType" SG_ 386 sigAirIntenZon1St "varchar(15)";
BA_ "DataCenterDataType" SG_ 386 sigRecircSt "Varchar(10)";
BA_ "DataCenterDataType" SG_ 386 sigSetTempZon1St "float";
BA_ "GenSigInvalidValue" SG_ 386 sigAmbAirT 255;
BA_ "GenSigRoutingTimeoutValue_String" SG_ 386 sigAmbAirT "0xFF";
BA_ "GenSigRoutingTimeoutValue" SG_ 386 sigAmbAirT 255;
BA_ "DataCenterDataType" SG_ 386 sigAmbAirT "Varchar(5)";
BA_ "GenSigStartValue" SG_ 386 sigCbnSolarRight 253;
BA_ "GenSigInvalidValue" SG_ 386 FD_RecyAuto_Cmd 7;
BA_ "GenSigStartValue" SG_ 386 FD_RecyAuto_Cmd 7;
BA_ "GenSigRoutingTimeoutValue_String" SG_ 386 FD_RecyAuto_Cmd "0x7";
BA_ "GenSigInactiveValue" SG_ 386 FD_RecyAuto_Cmd 7;
BA_ "GenSigRoutingTimeoutValue" SG_ 386 FD_RecyAuto_Cmd 7;
BA_ "GenSigInvalidValue" SG_ 386 CabinMode 15;
BA_ "GenSigStartValue" SG_ 386 CabinMode 15;
BA_ "GenSigRoutingTimeoutValue_String" SG_ 386 CabinMode "0xF";
BA_ "GenSigInactiveValue" SG_ 386 CabinMode 15;
BA_ "GenSigRoutingTimeoutValue" SG_ 386 CabinMode 15;
BA_ "DataCenterDataType" SG_ 386 CabinMode "Varchar(30)";
BA_ "GenSigStartValue" SG_ 386 sigCbnSolarLeft 253;
BA_ "GenSigStartValue" SG_ 386 sigClntTHvBattOut 120;
BA_ "GenSigStartValue" SG_ 386 Rr_Coolanttemp 40;
BA_ "GenSigSendType" SG_ 534 BCM_Buzzer_Req 3;
BA_ "GenSigSendType" SG_ 534 TailgateRemote 3;
BA_ "GenSigSendType" SG_ 534 RoomLampL 3;
BA_ "GenSigSendType" SG_ 534 RoomLampH 3;
BA_ "GenSigSendType" SG_ 534 DimmerEN 3;
BA_ "GenSigSendType" SG_ 534 BCM_DoorLock_Sta 3;
BA_ "DataCenterDataType" SG_ 534 BCM_DoorLock_Sta "Varchar(7)";
BA_ "GenSigSendType" SG_ 534 HornCtrl 3;
BA_ "GenSigInvalidValue" SG_ 534 Dimmer 127;
BA_ "GenSigRoutingTimeoutValue_String" SG_ 534 Dimmer "0x7F";
BA_ "GenSigRoutingTimeoutValue" SG_ 534 Dimmer 127;
BA_ "GenSigSendType" SG_ 534 Dimmer 3;
BA_ "GenSigSendType" SG_ 534 LockSetting 3;
BA_ "GenSigSendType" SG_ 534 LTurnLP 3;
BA_ "GenSigSendType" SG_ 534 RTurnLP 3;
BA_ "GenSigSendType" SG_ 534 AntitheftSta 3;
BA_ "DataCenterDataType" SG_ 534 AntitheftSta "Varchar(30)";
BA_ "GenSigSendType" SG_ 534 AntiTheftSeatFold 3;
BA_ "GenSigSendType" SG_ 534 CrashDetd 3;
BA_ "DataCenterDataType" SG_ 534 CrashDetd "Varchar(20)";
BA_ "GenSigSendType" SG_ 534 L_APM_WdwEnable 3;
BA_ "GenSigSendType" SG_ 534 RDRL 3;
BA_ "GenSigSendType" SG_ 534 ReverseLamp 3;
BA_ "GenSigSendType" SG_ 534 BrakeLamp 3;
BA_ "GenSigSendType" SG_ 534 LBSD 3;
BA_ "GenSigSendType" SG_ 534 RBSD 3;
BA_ "GenSigSendType" SG_ 534 Fr_FogLamp 3;
BA_ "GenSigSendType" SG_ 534 Rr_FogLamp 3;
BA_ "GenSigSendType" SG_ 534 HazardSW 3;
BA_ "GenSigSendType" SG_ 534 Rr_Wiper 3;
BA_ "GenSigSendType" SG_ 534 WiperFixMode 3;
BA_ "GenSigSendType" SG_ 534 WasherCtrl 3;
BA_ "GenSigSendType" SG_ 534 L_Beam 3;
BA_ "GenSigSendType" SG_ 534 H_Beam 3;
BA_ "GenSigSendType" SG_ 534 PosLamp 3;
BA_ "GenSigSendType" SG_ 534 LDRL 3;
BA_ "GenSigSendType" SG_ 534 MirrorDefog 3;
BA_ "GenSigSendType" SG_ 534 Rr_Defog 3;
BA_ "GenSigSendType" SG_ 534 TrunkRel 3;
BA_ "GenSigSendType" SG_ 534 TailgateHDSW 3;
BA_ "GenSigSendType" SG_ 534 MirrorCtrl 3;
BA_ "GenSigSendType" SG_ 534 Fr_Wiper_H 3;
BA_ "GenSigSendType" SG_ 534 Fr_Wiper_L 3;
BA_ "GenSigSendType" SG_ 534 CTDCtrl 3;
BA_ "GenSigSendType" SG_ 534 Fr_ChargingDoorCtrl 3;
BA_ "GenSigSendType" SG_ 534 Rr_ChargingDoorCtrl 3;
BA_ "GenSigSendType" SG_ 534 CTDLockSW 3;
BA_ "GenSigSendType" SG_ 534 CTDUnlockSW 3;
BA_ "GenSigSendType" SG_ 534 DrDoorSW 3;
BA_ "GenSigSendType" SG_ 534 PsDoorSW 3;
BA_ "GenSigSendType" SG_ 534 RLDoorSW 3;
BA_ "GenSigSendType" SG_ 534 RRDoorSW 3;
BA_ "GenSigSendType" SG_ 534 AllDoorSW 3;
BA_ "GenSigSendType" SG_ 534 DoorLockIND 3;
BA_ "GenSigSendType" SG_ 534 HoodSW 3;
BA_ "GenSigSendType" SG_ 534 Tailgate_SW 3;
BA_ "GenSigSendType" SG_ 1665 DiagPhysReqToESC 3;
BA_ "GenSigInvalidValue" SG_ 602 METER_KPH_Calcu 255;
BA_ "GenSigRoutingTimeoutValue_String" SG_ 602 METER_KPH_Calcu "0xFF";
BA_ "GenSigRoutingTimeoutValue" SG_ 602 METER_KPH_Calcu 255;
BA_ "GenSigInvalidValue" SG_ 602 METER_MPH_Calcu 255;
BA_ "GenSigRoutingTimeoutValue_String" SG_ 602 METER_MPH_Calcu "0xFF";
BA_ "GenSigRoutingTimeoutValue" SG_ 602 METER_MPH_Calcu 255;
BA_ "GenSigInvalidValue" SG_ 602 METER_KPH_Real 4095;
BA_ "GenSigInvalidValue" SG_ 602 METER_MPH_Real 4095;
BA_ "GenSigInvalidValue" SG_ 602 Averaged_vehspeed 1023;
BA_ "GenSigInvalidValue" SG_ 602 AVGPwrConsumption 65535;
BA_ "GenSigStartValue" SG_ 602 AVGPwrConsumption 9999;
BA_ "GenSigInvalidValue" SG_ 602 APCforDTE 65535;
BA_ "GenSigStartValue" SG_ 602 APCforDTE 9999;
BA_ "GenSigInvalidValue" SG_ 602 AvailableTrip 65535;
BA_ "GenSigInvalidValue" SG_ 602 Spd_Crl_Mode 5;
BA_ "GenSigRoutingTimeoutValue_String" SG_ 602 Spd_Crl_Mode "0x5";
BA_ "GenSigRoutingTimeoutValue" SG_ 602 Spd_Crl_Mode 5;
BA_ "GenSigSendType" SG_ 602 LEDlitWarnReq 3;
BA_ "GenSigSendType" SG_ 602 Charge 3;
BA_ "GenSigSendType" SG_ 602 ParkBrake 3;
BA_ "GenSigSendType" SG_ 602 Trip_B 3;
BA_ "DataCenterDataType" SG_ 602 Trip_B "Varchar(10)";
BA_ "GenSigSendType" SG_ 602 Trip_A 3;
BA_ "DataCenterDataType" SG_ 602 Trip_A "Varchar(10)";
BA_ "GenSigSendType" SG_ 602 ODOMETER 3;
BA_ "DataCenterDataType" SG_ 602 ODOMETER "Varchar(10)";
BA_ "GenSigSendType" SG_ 1681 DiagPhysReqToeBST 3;
BA_ "GenSigSendType" SG_ 1553 DiagRespFromeBST 3;
BA_ "GenSigStartValue" SG_ 119 FDC_VMC_RWS_PositionReq_Cmd 32767;
BA_ "GenSigInvalidValue" SG_ 575 Rr_TMSpd 65535;
BA_ "GenSigStartValue" SG_ 575 Rr_TMSpd 18000;
BA_ "GenSigRoutingTimeoutValue_String" SG_ 575 Rr_TMSpd "0xFFFF";
BA_ "GenSigInactiveValue" SG_ 575 Rr_TMSpd 65535;
BA_ "GenSigRoutingTimeoutValue" SG_ 575 Rr_TMSpd 65535;
BA_ "DataCenterDataType" SG_ 575 Rr_TMSpd "INT(5)";
BA_ "GenSigInvalidValue" SG_ 575 Fr_TMSpd 65535;
BA_ "GenSigStartValue" SG_ 575 Fr_TMSpd 18000;
BA_ "GenSigRoutingTimeoutValue_String" SG_ 575 Fr_TMSpd "0xFFFF";
BA_ "GenSigInactiveValue" SG_ 575 Fr_TMSpd 65535;
BA_ "GenSigRoutingTimeoutValue" SG_ 575 Fr_TMSpd 65535;
BA_ "GenSigSendType" SG_ 575 BMS_READY 3;
BA_ "GenSigSendType" SG_ 1698 DiagPhysReqToOCS 3;
BA_ "GenSigSendType" SG_ 1570 DiagRespFromOCS 3;
BA_ "GenSigSendType" SG_ 1314 NM_OCS_Node_ID 7;
BA_ "GenSigSendType" SG_ 1314 NM_OCS_ERROR_State 7;
BA_ "GenSigSendType" SG_ 1314 NM_OCS_Active_WU 7;
BA_ "GenSigSendType" SG_ 1314 NM_OCS_CSB 7;
BA_ "GenSigSendType" SG_ 1314 NM_OCS_PNI 7;
BA_ "GenSigSendType" SG_ 1314 NM_OCS_Rpt_Msg_Req 7;
BA_ "GenSigSendType" SG_ 2015 DiagFuncReqOBD 3;
BA_ "GenSigSendType" SG_ 2033 DiagPhysReqToScrap 3;
BA_ "GenSigSendType" SG_ 2041 DiagRespFromScrap 3;
BA_ "GenSigInvalidValue" SG_ 1173 ESC_SW_Cmd 3;
BA_ "GenSigRoutingTimeoutValue_String" SG_ 1173 ESC_SW_Cmd "0x3";
BA_ "GenSigRoutingTimeoutValue" SG_ 1173 ESC_SW_Cmd 3;
BA_ "GenSigSendType" SG_ 1173 ESC_SW_Cmd 3;
BA_ "GenSigInvalidValue" SG_ 1173 Roll_Mode_SW_Cmd 3;
BA_ "GenSigRoutingTimeoutValue_String" SG_ 1173 Roll_Mode_SW_Cmd "0x3";
BA_ "GenSigRoutingTimeoutValue" SG_ 1173 Roll_Mode_SW_Cmd 3;
BA_ "GenSigSendType" SG_ 1173 Roll_Mode_SW_Cmd 3;
BA_ "GenSigInvalidValue" SG_ 1173 TCS_SW_Cmd 3;
BA_ "GenSigRoutingTimeoutValue_String" SG_ 1173 TCS_SW_Cmd "0x3";
BA_ "GenSigRoutingTimeoutValue" SG_ 1173 TCS_SW_Cmd 3;
BA_ "GenSigSendType" SG_ 1173 TCS_SW_Cmd 3;
BA_ "GenSigSendType" SG_ 1173 Roll_Eng_Mode 3;
VAL_ 515 CrashOutputSts 255 "Invalid" 62 "Rollover+Left+Right+Rear+Front" 60 "Rollover+Left+Right+Rear" 58 "Rollover+Left+Right+Front" 56 "Rollover+Left+Right" 54 "Rollover+Left+Rear+Front" 52 "Rollover+Left+Rear" 50 "Rollover+Left+Front" 48 "Rollover+Left" 46 "Rollover+Right+Rear+Front" 44 "Rollover+Right+Rear" 42 "Rollover+Right+Front" 40 "Rollover+Right" 38 "Rollover+Rear+Front" 36 "Rollover+Rear" 34 "Rollover+Front" 32 "Rollover" 30 "Left+Right+Rear+Front" 28 "Left+Right+Rear" 26 "Left+Right+Front" 24 "Left+Right" 22 "Left+Rear+Front" 20 "Left+Rear" 18 "Left+Front" 16 "Left" 14 "Right+Rear+Front" 12 "Right+Rear" 10 "Right+Front" 8 "Right" 6 "Rear+Front" 4 "Rear" 2 "Front" 0 "No Crash";
VAL_ 515 TRHPsngrSeatBeltCmd 1 "Lamp ON" 0 "Lamp OFF";
VAL_ 515 AirBagFailCmd 1 "Lamp ON" 0 "Lamp OFF";
VAL_ 515 DriverSeatBeltCmd 1 "Lamp ON" 0 "Lamp OFF";
VAL_ 515 PsngrSeatBeltCmd 1 "Lamp ON" 0 "Lamp OFF";
VAL_ 515 PABSwitchCmd 1 "Lamp ON" 0 "Lamp OFF";
VAL_ 515 RDriverSeatBeltCmd 1 "Lamp ON" 0 "Lamp OFF";
VAL_ 515 RPsngrSeatBeltCmd 1 "Lamp ON" 0 "Lamp OFF";
VAL_ 515 RCenterSeatBeltCmd 1 "Lamp ON" 0 "Lamp OFF";
VAL_ 515 TLHPsngrSeatBeltCmd 1 "Lamp ON" 0 "Lamp OFF";
VAL_ 515 ABM_Passenger_ODS_Sta 1 "LAMP ON" 0 "LAMP OFF";
VAL_ 515 ABM_RearPassengerLH_ODS_Sta 1 "LAMP ON" 0 "LAMP OFF";
VAL_ 515 ABM_RearPassengerCTR_ODS_Sta 1 "LAMP ON" 0 "LAMP OFF";
VAL_ 515 ABM_RearPassengerRH_ODS_Sta 1 "LAMP ON" 0 "LAMP OFF";
VAL_ 391 EPS_TOI_Dis_R 15 "Reserved" 14 "Reserved" 13 "Reserved" 12 "Reserved" 11 "Reserved" 10 "Reserved" 9 "Max. Controlled Angle" 8 "Max. Vehicle Speed" 7 "Non-Zero Value" 6 "Max. Request Rate" 5 "Max. Request Value" 4 "FCM TOI Fault" 3 "Communication Error" 2 "EPS Failed" 1 "TOI function not enable" 0 "Enable";
VAL_ 391 DriIntend 2 "Driver Interrupt" 1 "Hands off steering wheel" 0 "Hands on steering wheel";
VAL_ 391 EPS_AOI_Control 3 "Permanently Fail" 2 "Controlled" 1 "Available for control" 0 "Control Inhibit";
VAL_ 391 EPS_TOI_Activation 1 "Activation" 0 "No Activation";
VAL_ 391 EPS_TOI_Unavailable 1 "Unavailable" 0 "Available";
VAL_ 391 EPS_TOI_Fault 1 "Fault" 0 "No Fault";
VAL_ 391 SAS_V 1 "Valid" 0 "Invalid";
VAL_ 391 EPS_AOI_Dis_R 15 "Reserved" 14 "SAC_Boost State Error" 13 "SAC_Boost Gain Error" 12 "SAC_Weight Gain Error" 11 "SAC_Strg Trq Limit" 10 "SAC_Req Ang Spd Limit" 9 "SAC_Req Ang Limit" 8 "SAC_Veh Spd Limit" 7 "Driver Interrupt" 6 "Controlled Angle Error" 5 "Guiding Angle Error" 4 "Request Invalid" 3 "Communication Error" 2 "EPS Failed" 1 "AOI Function not Enable" 0 "Enable";
VAL_ 391 EPS_Pwr_Limit_V 1 "Valid" 0 "Invalid";
VAL_ 391 Steering_Torque_V 1 "Failed" 0 "Not Failed";
VAL_ 391 EPS_Pwr_Consumpt_V 1 "Valid" 0 "Invalid";
VAL_ 391 SAS_Speed_Valid 1 "Valid" 0 "Invalid";
VAL_ 391 SAS_CAL 1 "Calibrated" 0 "Non-calibrated";
VAL_ 391 EPS_LDW_Activation 3 "Strong Vibration" 2 "Medium Vibration" 1 "Light Vibration" 0 "No Activation";
VAL_ 391 EPS_LDW_Unavailable 1 "Unavailable" 0 "Available";
VAL_ 391 EPS_VOL_V 1 "Valid" 0 "Invalid";
VAL_ 391 EPS_Temp_V 1 "Valid" 0 "Invalid";
VAL_ 391 EpasFailed 2 "Perm Faild" 1 "Temp Faild" 0 "Not Faild";
VAL_ 391 EPS_ESABoostOut_Trq 63 "Invalid";
VAL_ 391 EPS_ESAInpBoost_Sta 1 "Active" 0 "Inactive";
VAL_ 391 EPS_DMSMode_Sta 15 "Reserved" 14 "Reserved" 13 "Reserved" 12 "Reserved" 11 "D31H_AWD_Heavy" 10 "D31H_AWD_Medium" 9 "D31H_AWD_Light" 8 "D31H_RWD" 7 "D21_AWD_Heavy" 6 "D21_AWD_Medium" 5 "D21_AWD_Light" 4 "D21_RWD" 3 "D31F_AWD_Heavy" 2 "D31F_AWD_Medium" 1 "D31F_AWD_Light" 0 "D31F_RWD";
VAL_ 338 VehSpeed 4095 "Invalid";
VAL_ 338 RF_WhlRotDir 3 "Standstill" 2 "Backward" 1 "Forward" 0 "Unknown/Standby";
VAL_ 338 RF_PulseCount_V 1 "Invalid" 0 "Valid";
VAL_ 338 Fr_PTCS_Active 1 "Active" 0 "Inactive";
VAL_ 338 LF_WhlRotDir 3 "Standstill" 2 "Backward" 1 "Forward" 0 "Unknown/Standby";
VAL_ 338 LF_PulseCount_V 1 "Invalid" 0 "Valid";
VAL_ 338 RF_RawWhlSpeed_V 1 "Invalid" 0 "Valid";
VAL_ 338 RR_WhlRotDir 3 "Standstill" 2 "Backward" 1 "Forward" 0 "Unknown/Standby";
VAL_ 338 LF_RawWhlSpeed_V 1 "Invalid" 0 "Valid";
VAL_ 338 RR_PulseCount_V 1 "Invalid" 0 "Valid";
VAL_ 338 LR_WhlRotDir 3 "Standstill" 2 "Backward" 1 "Forward" 0 "Unknown/Standby";
VAL_ 338 RR_RawWhlSpeed_V 1 "Invalid" 0 "Valid";
VAL_ 338 LR_PulseCount_V 1 "Invalid" 0 "Valid";
VAL_ 338 ESC_OFF_Status 2 "TCS and ESC OFF" 1 "TCS OFF" 0 "Normal";
VAL_ 338 ESC_BeepReq 1 "Request" 0 "No Request";
VAL_ 338 LR_RawWhlSpeed_V 1 "Invalid" 0 "Valid";
VAL_ 338 TCS_Failed 1 "Failed" 0 "Normal";
VAL_ 338 ESC_Failed 1 "Failed" 0 "Normal";
VAL_ 338 HBB_Failed 1 "Failed" 0 "Normal";
VAL_ 338 PBA_Failed 1 "Failed" 0 "Normal";
VAL_ 338 HSA_Failed 1 "Failed" 0 "Normal";
VAL_ 338 AVH_Failed 1 "Failed" 0 "Normal";
VAL_ 338 HDD_Failed 1 "Failed" 0 "Normal";
VAL_ 338 Rr_PTCS_Active 1 "Active" 0 "Inactive";
VAL_ 338 HSA_Active 1 "Active" 0 "Inactive";
VAL_ 338 AVH_Active 1 "Active" 0 "Inactive";
VAL_ 338 Amber_WnlmpSta 1 "Amber Wnlmp constant" 0 "Amber Wnlmp Off";
VAL_ 338 BTCS_Active 1 "Active" 0 "Inactive";
VAL_ 338 ESS_Active 1 "Active" 0 "Inactive";
VAL_ 338 HDD_Active 1 "Active" 0 "Inactive";
VAL_ 338 EBD_Failed 1 "Failed" 0 "Normal";
VAL_ 338 ABS_Failed 1 "Failed" 0 "Normal";
VAL_ 338 ESC_WnlmpSta 2 "ESC lmp flash" 1 "ESC lmp permanent" 0 "ESC lmp Off";
VAL_ 338 EBD_Active 1 "Active" 0 "Inactive";
VAL_ 338 ABS_Active 1 "Active" 0 "Inactive";
VAL_ 338 TCS_Active 1 "Active" 0 "Inactive";
VAL_ 338 ESC_Active 1 "Active" 0 "Inactive";
VAL_ 338 HBB_Active 1 "Active" 0 "Inactive";
VAL_ 338 PBA_Active 1 "Active" 0 "Inactive";
VAL_ 338 GRADE 255 "Invalid";
VAL_ 338 Red_WnlmpSta 1 "Red Wnlmp constant" 0 "Red Wnlmp Off";
VAL_ 338 ABS_WnlmpSta 1 "ABS Wnlmp constant" 0 "ABS Wnlmp Off";
VAL_ 338 ESC_Off_lmpSta 1 "ESC OFF lmp permanent" 0 "ESC OFF lmp Off";
VAL_ 338 ESC_TSA_Active 1 "Active" 0 "Inactive";
VAL_ 338 ESC_EstVehSpd_V 1 "Invalid" 0 "Valid";
VAL_ 421 BrkDiscTempSta 1 "Over Temperature" 0 "Nomal";
VAL_ 421 ACCAvail 1 "Available" 0 "Unavailable";
VAL_ 421 YawRate_V 1 "Invalid" 0 "Valid";
VAL_ 421 LatAccel_V 1 "Invalid" 0 "Valid";
VAL_ 421 LongAccel_V 1 "Invalid" 0 "Valid";
VAL_ 421 MCPressure_V 1 "Invalid" 0 "Valid";
VAL_ 421 BrkSw_Sta 1 "Active" 0 "Inactive";
VAL_ 421 BrkSw_V 1 "Invalid" 0 "Valid";
VAL_ 421 ESC_ADAS_Sta 6 "Haptic Brake" 5 "Vehicle Standstill" 4 "Vehicle Holding" 3 "Deceleration Control" 2 "AEB Emergency Brake" 1 "Prefill" 0 "Internal";
VAL_ 421 ESC_Standstill 1 "Standstill" 0 "Not Standstill";
VAL_ 421 DecErrSta 1 "Error" 0 "Nomal";
VAL_ 421 ActBrkLamp_Sta 1 "On" 0 "Off";
VAL_ 421 AEBAvail 1 "Available" 0 "Unavailable";
VAL_ 421 BrkPedalPos_Sta 1 "Valid" 0 "Invalid";
VAL_ 421 ESC_APS_Sta 5 "APS Unavailable(ESC Failed)" 4 "Standstill with EPB" 3 "Standstill with Brake Hold" 2 "Decel Control" 1 "Standby(Ready)" 0 "Off";
VAL_ 421 Meter_Ind_VehSpeed 4095 "Invalid";
VAL_ 421 Fr_RBC_Active 1 "Active" 0 "Inactive";
VAL_ 421 Rr_RBC_Active 1 "Active" 0 "Inactive";
VAL_ 421 RDC_Active 2 "Exit Immediately" 1 "Ramp out" 0 "No Request";
VAL_ 421 ESC_DriverBrkOverride 1 "On" 0 "Off";
VAL_ 427 EPBSta 4 "Unknown" 3 "Releasing" 2 "Released" 1 "Applying" 0 "Applied";
VAL_ 427 EPBMsg 12 "Fasten driver seat belt" 11 "Press brake pedal to release Auto-Hold(Reserved)" 10 "Close driver side door(AVH)" 9 "EPB failed while AVH is activate" 8 "Please release park brake" 7 "Recalibration in progress" 6 "Depress Brake Pedal" 5 "Close driver-side door(DAR)" 4 "Rollerbench  Mode" 3 "Maintenance Mode" 2 "Slope Too Steep" 1 "Apply park brake" 0 "None";
VAL_ 427 EPBStaR 7 "Invalid" 6 "CompletelyReleased" 5 "Released" 4 "Releasing" 3 "Applying" 2 "HoldApplied" 1 "ParkApplied" 0 "Unknown";
VAL_ 427 EPBErrSta 2 "Diagnostic Mode" 1 "Failed" 0 "Normal";
VAL_ 427 EPBRLampSta 2 "Flash" 1 "Permanent" 0 "Off";
VAL_ 427 EPBExtReleaseAvail 1 "Available" 0 "Unavailable";
VAL_ 427 EPBExtApplyAvail 1 "Available" 0 "Unavailable";
VAL_ 427 EPBCarWashMode 1 "Car Wash mode" 0 "Not Car wash mode";
VAL_ 427 DOA_Sta 1 "Enabled" 0 "Disabled";
VAL_ 427 EPBStaL 7 "Invalid" 6 "CompletelyReleased" 5 "Released" 4 "Releasing" 3 "Applying" 2 "HoldApplied" 1 "ParkApplied" 0 "Unknown";
VAL_ 427 TakeOverReq 1 "On (Controlled by Backup EPB)" 0 "Off (Controlled by ESC)";
VAL_ 1281 NM_ESC_Rpt_Msg_Req 1 "Repeat Message State requested" 0 "Repeat Message State not requested";
VAL_ 1281 NM_ESC_CSB 1 "Start of synchronized shutdown is requested by main coordinator" 0 "Start of synchronized shutdown is not requested by main coordinator";
VAL_ 1281 NM_ESC_Active_WU 1 "Node has woken up the network (active Wakeup)" 0 "Node has not woken up the network (passive wakeup)";
VAL_ 1281 NM_ESC_PNI 1 "NM PDU contains Partial Network request information" 0 "NM PDU contains no Partial Network request information";
VAL_ 1281 NM_ESC_ERROR_State 8 "BUS OFF_L2" 4 "BUS OFF_L1" 2 "ERROR PASSIVE" 1 "ERROR ACTIVE" 0 "Inactive";
VAL_ 278 PrkReqValid 1 "Invalid" 0 "Valid";
VAL_ 278 P_Button_Sta 2 "Invalid" 1 "Pressed" 0 "Released";
VAL_ 278 CC_Crl_Sta 7 "Pedal Override" 6 "Invalid" 5 "Error" 4 "Over Speed" 3 "Under Speed" 2 "Active" 1 "Standby" 0 "Off";
VAL_ 278 MSA_Crl_Sta 7 "Pedal Override" 6 "Invalid" 5 "Error" 4 "Over Speed" 3 "Under Speed" 2 "Active" 1 "Standby" 0 "Off";
VAL_ 278 ShiftGearPosn 7 "Reverse" 6 "Failure" 5 "Drive" 4 "Neutral" 3 "Not used" 2 "Not used" 1 "Invalid" 0 "Park";
VAL_ 278 PrkReq 1 "Parking Requested" 0 "Parking Released";
VAL_ 278 XWDMode 2 "AWD" 1 "FWD" 0 "RWD";
VAL_ 278 LVPwrSta 1 "LV power active" 0 "LV power inactive";
VAL_ 278 HVPwrSta 1 "HV power active" 0 "HV power inactive";
VAL_ 278 PwrSta 7 "Invalid" 5 "READY" 4 "ON" 3 "STANDBY" 2 "OFF-After-Run" 1 "OFF-Charging" 0 "OFF";
VAL_ 278 Eng_AGSCloseSta 1 "Closed" 0 "Auto";
VAL_ 278 Eng_PwrLockSta 2 "Invalid" 1 "Locked" 0 "Unlocked";
VAL_ 278 Eng_CoastDwSta 2 "Invalid" 1 "On" 0 "Off";
VAL_ 278 Eng_ActvDmpDisabSta 2 "Invalid" 1 "On" 0 "Off";
VAL_ 278 VehMalfunLevel 5 "Invalid" 4 "4th grade malfunction" 3 "3rd grade malfunction" 2 "2nd grade malfunction" 1 "1st grade malfunction" 0 "Normal";
VAL_ 340 AccPedal_Override 1 "Acceleration Pedal Override" 0 "No Override";
VAL_ 340 ACC_CtrlAvail 1 "Available" 0 "Unavailable";
VAL_ 1280 NM_FUSION_Rpt_Msg_Req 1 "Repeat Message State requested" 0 "Repeat Message State not requested";
VAL_ 1280 NM_FUSION_CSB 1 "Start of synchronized shutdown is requested by main coordinator" 0 "Start of synchronized shutdown is not requested by main coordinator";
VAL_ 1280 NM_FUSION_Active_WU 1 "Node has woken up the network (active Wakeup)" 0 "Node has not woken up the network (passive wakeup)";
VAL_ 1280 NM_FUSION_PNI 1 "NM PDU contains Partial Network request information" 0 "NM PDU contains no Partial Network request information";
VAL_ 1280 NM_FUSION_ERROR_State 8 "BUS OFF_L2" 4 "BUS OFF_L1" 2 "ERROR PASSIVE" 1 "ERROR ACTIVE" 0 "Inactive";
VAL_ 1297 NM_eBST_Rpt_Msg_Req 1 "Repeat Message State requested" 0 "Repeat Message State not requested";
VAL_ 1297 NM_eBST_CSB 1 "Start of synchronized shutdown is requested by main coordinator" 0 "Start of synchronized shutdown is not requested by main coordinator";
VAL_ 1297 NM_eBST_Active_WU 1 "Node has woken up the network (active Wakeup)" 0 "Node has not woken up the network (passive wakeup)";
VAL_ 1297 NM_eBST_PNI 1 "NM PDU contains Partial Network request information" 0 "NM PDU contains no Partial Network request information";
VAL_ 1297 NM_eBST_ERROR_State 8 "BUS OFF_L2" 4 "BUS OFF_L1" 2 "ERROR PASSIVE" 1 "ERROR ACTIVE" 0 "Inactive";
VAL_ 1168 VehACModReq 7 "Invalid" 6 "Signal not available" 5 "Reserved" 2 "Reserved" 1 "Economy mode" 0 "Standard";
VAL_ 1168 FCP_FrEvt_BtnACMaxReq 1 "Press" 0 "Release";
VAL_ 1168 FCP_FrEvt_BtnACReq 1 "Press" 0 "Release";
VAL_ 1168 FCP_FrEvt_BtnAutoReq 1 "Press" 0 "Release";
VAL_ 1168 FCP_MidEvt_BtnAutoReq 1 "Press" 0 "Release";
VAL_ 1168 FCP_FrEvt_BtnSyncReq 1 "Press" 0 "Release";
VAL_ 1168 OTA_DL_Req 1 "Press" 0 "Release";
VAL_ 1168 OTA_SuspendDL_Req 1 "Press" 0 "Release";
VAL_ 1168 OTA_UpdStart_Req 1 "Press" 0 "Release";
VAL_ 1168 IVI_OTA_Upd_Sta 3 "undefined" 2 "Completed" 1 "Uncompleted" 0 "No Update";
VAL_ 1168 OTA_CancelDL_Req 1 "Press" 0 "Release";
VAL_ 1168 SmartEco_Mode_SW 1 "ON" 0 "OFF";
VAL_ 1168 LINKtoDrive 1 "Press" 0 "Release";
VAL_ 1168 Upd_Countdown_Skip 1 "Press" 0 "Release";
VAL_ 1168 Upd_Countdown_Cancel 1 "Press" 0 "Release";
VAL_ 1168 AmbLightColorSet 65 "~0x7F undefined" 64 "No request" 63 "Red(255,0,0)" 62 "IndianRed(205,92,92)" 61 "LightCoral(240,128,128)" 60 "Tomato(255,99,71)" 59 "OrangeRed(255,69,0)" 58 "Coral(255,127,80)" 57 "LightSalmon(255,160,122)" 56 "DarkOrange(255,140,0)" 55 "Bisque(255,228,196)" 54 "NavajoWhite(255,222,173)" 53 "BlanchedAlmond(255,235,205)" 52 "Gold(255,215,0)" 51 "LemonChiffon(255,250,205)" 50 "Yellow(255,255,0)" 49 "LightYellow(255,255,224)" 48 "Ivory(255,255,240)" 47 "LightGoldenrodYellow(250,250,210)" 46 "Beige(245,245,220)" 45 "GreenYellow(73,255,47)" 44 "Chartreuse(127,255,0)" 43 "Lime(0,255,0)" 42 "LimeGreen(50,205,50)" 41 "PaleGreen(152,251,152)" 40 "LightGreen(144,238,144)" 39 "SeaGreen(46,139,87)" 38 "SpringGreen(60,179,113)" 37 "MediumSpringGreen(0,255,127)" 36 "MediumAquamarine(0,250,154)" 35 "Auqamarin(127,255,170)" 34 "MediumTurquoise(72,209,204)" 33 "DarkCyan(0,139,139)" 32 "DarkTurquoise(0,206,209)" 31 "Cyan(0,255,255)" 30 "PaleTurquoise(175,238,238)" 29 "DeepSkyBlue(0,191,255)" 28 "SkyBlue(135,206,235)" 27 "LightSkyBlue(135,206,250)" 26 "DoderBlue(30,144,255)" 25 "CornflowerBlue(100,149,237)" 24 "RoyalBlue(65,105,225)" 23 "Navy(0,0,128)" 22 "DarkBlue(0,0,139)" 21 "MidnightBlue(25,25,112)" 20 "MediumBlue(0,0,205)" 19 "Blue(0,0,255)" 18 "DarkSlateBlue(72,61,139)" 17 "SlateBlue(106,90,205)" 16 "MediumSlateBlue(123,104,238)" 15 "MediumPurple(147,112,219)" 14 "BlueViolet(138,43,226)" 13 "Indigo(75,0,130)" 12 "DarkOrchid(153,50,204)" 11 "DarkVoilet(148,0,211)" 10 "MediumOrchid(186,85,211)" 9 "DarkMagenta(139,0,139)" 8 "Magenta(255,0,255)" 7 "Violet(238,130,238)" 6 "Orchid(218,112,214)" 5 "MediumVioletRed(199,21,133)" 4 "DeepPink(255,20,147)" 3 "HotPink(255,105,180)" 2 "PaleVioletRed(219,112,147)" 1 "Crimson(220,20,60)" 0 "LightPink(255,182,193)";
VAL_ 1168 Sched_OTA_wake 1 "wake" 0 "standby";
VAL_ 1168 UserSet 7 "Rent" 6 "Guest" 5 "User5" 4 "User4" 3 "User3" 2 "User2" 1 "User1" 0 "No Request";
VAL_ 1168 AmbLightBrightnessSet 127 "Invalid" 102 "~0x7F undefined" 101 "No request" 100 "Max" 0 "Min";
VAL_ 1168 Sched_Chg_Day_Set 1 "Weekday" 0 "Everyday";
VAL_ 1168 Re_Radio_Sta 1 "ON" 0 "OFF";
VAL_ 1168 A2B_Node_sta 1 "Fail" 0 "Normal";
VAL_ 1168 IVI_Located_STA 3 "Not Used" 2 "3D fix" 1 "2D fix" 0 "No fix";
VAL_ 1168 OTA_CompNTFY_Pres 1 "Presented" 0 "Not presented";
VAL_ 1168 BrkAbn_GoReady_SW 1 "Press" 0 "Release";
VAL_ 1168 PW_CONTINUE_USE 1 "Press" 0 "Release";
VAL_ 1168 PW_CLOSE_IMD 1 "Press" 0 "Release";
VAL_ 1168 IVI_Time_Month 15 "Not Used" 14 "Not Used" 13 "Not Used" 0 "invalid";
VAL_ 1168 mFRD_link_Sta 1 "Fail" 0 "Normal";
VAL_ 1168 AmbLight_SW 1 "Press" 0 "Release";
VAL_ 1168 AmbLight_DimInDark_SW 1 "Press" 0 "Release";
VAL_ 1168 AmbLight_WlcmLight_SW 1 "Press" 0 "Release";
VAL_ 1168 AmbLigh_LowBatAlert_SW 1 "Press" 0 "Release";
VAL_ 1168 AmbLigh_SafetyAlert_SW 1 "Press" 0 "Release";
VAL_ 1168 OpenDrOpenWdo_SW 1 "Press" 0 "Release";
VAL_ 1168 IVI_LinkKey_Sta 15 "undefined" 14 "undefined" 13 "undefined" 12 "undefined" 11 "undefined" 10 "Link key 10" 9 "Link key 9" 8 "Link key 8" 7 "Link key 7" 6 "Link key 6" 5 "Link key 5" 4 "Link key 4" 3 "Link key 3" 2 "Link key 2" 1 "Link key 1" 0 "No Request";
VAL_ 1168 IVI_CreateAccReq_Sta 7 "undefined" 6 "undefined" 5 "Create User 5 account" 4 "Create User 4 account" 3 "Create User 3 account" 2 "Create User 2 account" 1 "Create User 1 account" 0 "No Request";
VAL_ 1168 IVI_DelAccReq_Sta 7 "undefined" 6 "undefined" 5 "Delete User 5 account" 4 "Delete User 4 account" 3 "Delete User 3 account" 2 "Delete User 2 account" 1 "Delete User 1 account" 0 "No Request";
VAL_ 1168 IVI_LinkAcc_Sta 7 "undefined" 6 "undefined" 5 "Link key to User 5" 4 "Link key to User 4" 3 "Link key to User 3" 2 "Link key to User 2" 1 "Link key to User 1" 0 "No Request";
VAL_ 1168 IVI_LinkAccReq_Sta 1 "Link account request" 0 "No Request";
VAL_ 1168 IVI_FrTrunk_UnlockReq_Sta 1 "Press" 0 "Release";
VAL_ 1168 IVI_CLWin_LockDoorSW_Sta 1 "Press" 0 "Release";
VAL_ 1168 IVI_Lock_SoundSW_Sta 1 "ON" 0 "OFF";
VAL_ 1168 IVI_SWC_VibMode_Sta 3 "High" 2 "Middle" 1 "Low" 0 "OFF";
VAL_ 1168 IVI_DMS_SW_Sta 1 "ON" 0 "OFF";
VAL_ 1168 IVI_AirRefresh_ByDMS_Sta 1 "Press" 0 "Release";
VAL_ 1168 IVI_QuickRefresh_Sta 1 "ON" 0 "OFF";
VAL_ 1168 IVI_HMI_Undefined_Sta 7 "Volume" 6 "FAN Level" 5 "Wind Direction" 4 "Auto Light/Dark Theme" 3 "NAVI" 2 "Interior Light" 1 "AVM/Rear View" 0 "A/C";
VAL_ 1168 IVI_AutoTheme_But_Sta 1 "ON" 0 "OFF";
VAL_ 1168 IVI_NAVI_Foreground_Sta 1 "Enable" 0 "Close";
VAL_ 1168 IVI_sigScreenReq_Sta 1 "Press" 0 "Release";
VAL_ 1168 IVI_DSEAT_anti_set_Sta 1 "Press" 0 "Release";
VAL_ 1168 IVI_MirrorFolded_SW_Sta 1 "Press" 0 "Release";
VAL_ 1168 IVI_WPTC_SW_Sta 1 "Press" 0 "Release";
VAL_ 1168 IVI_Driving_Lock_SW_Sta 1 "Press" 0 "Release";
VAL_ 1168 IVI_Stopping_Unlock_SW_Sta 1 "Press" 0 "Release";
VAL_ 1168 IVI_SilentChrg_Alert_Sta 1 "Show Pop up" 0 "None Pop up";
VAL_ 1168 IVI_WirelessCharge_Cmd 1 "ON" 0 "OFF";
VAL_ 1168 IVI_Theme_Sta 3 "Reserved" 2 "Reserved" 1 "Light" 0 "Dark";
VAL_ 1168 IVI_EPS_Force_Cmd 2 "High" 1 "Low" 0 "Standard";
VAL_ 1168 IVI_DSEAT_StopKeepMove_Sta 3 "Invalid" 2 "Keep Moving" 1 "Stop Moving" 0 "No Request";
VAL_ 1168 IVI_AutoWipHSpdSW_Cmd 1 "Press" 0 "Release";
VAL_ 1168 IVI_DSEAT_entryfun_set_Sta 1 "Press" 0 "Release";
VAL_ 370 VMC_FCM_LKA_TOIAct 1 "Activeation" 0 "No Activeation";
VAL_ 370 VMC_AEB_VehHoldReq 1 "Request" 0 "No Request";
VAL_ 370 VMC_FCM_LKA_TOIFault 1 "Fault" 0 "No Fault";
VAL_ 370 VMC_FCM_LDW_Fault 1 "Fault" 0 "No Fault";
VAL_ 370 VMC_FCM_LDW_Request 3 "Req. Strong Vibration" 2 "Req. Medium Vibration" 1 "Req. Light Vibration" 0 "No Request";
VAL_ 370 VMC_ADAS_AEBReq 3 "Request Level III" 2 "Request Level II" 1 "Request Level I" 0 "No Request";
VAL_ 370 VMC_ADAS_FaultSta 1 "Fault" 0 "Normal";
VAL_ 370 VMC_ADAS_DBSReq 3 "DBS Level III" 2 "DBSLevel II" 1 "DBS Level I" 0 "No Request";
VAL_ 370 VMC_ACC_VehHoldReq 1 "Request" 0 "No Request";
VAL_ 370 VMC_ADAS_ACC_Sta 6 "Disable" 5 "Error" 4 "Shut-off" 3 "Override" 2 "Active" 1 "Standby" 0 "Off";
VAL_ 370 VMC_ADAS_AEB_Sta 4 "Disable" 3 "Error" 2 "Active" 1 "Standby" 0 "Off";
VAL_ 370 FDC_VMC_DrInpTqBstGn 255 "Invalid" 0 "Default";
VAL_ 370 FDC_VMC_AngCtrlTqWtGn 255 "Invalid" 0 "Default";
VAL_ 370 FDC_VMC_MaxAngCtrlOutTqLim 511 "Invalid" 0 "Default";
VAL_ 370 FDC_VMC_DrInpTqBstAct 1 "Active" 0 "Inactive";
VAL_ 370 FDC_VMC_DMSMode_Cmd 15 "Reserved" 14 "Reserved" 13 "Reserved" 12 "Reserved" 11 "D31H_AWD_Heavy" 10 "D31H_AWD_Medium" 9 "D31H_AWD_Light" 8 "D31H_RWD" 7 "D21_AWD_Heavy" 6 "D21_AWD_Medium" 5 "D21_AWD_Light" 4 "D21_RWD" 3 "D31F_AWD_Heavy" 2 "D31F_AWD_Medium" 1 "D31F_AWD_Light" 0 "D31F_RWD";
VAL_ 383 FeatSetSpdFinal_raw32 19 "Reserved" 18 "Reserved" 17 "Reserved" 16 "Reserved" 15 "Reserved" 14 "Reserved" 13 "Reserved" 12 "Reserved" 11 "Reserved" 10 "Reserved" 9 "Reserved" 8 "Reserved" 7 "Reserved" 6 "Reserved" 5 "Reserved" 4 "Reserved" 3 "Reserved" 2 "Reserved" 1 "Dash Line" 0 "None";
VAL_ 383 FeatArbitrFinal 6 "Invalid" 5 "MSA" 4 "DISC" 3 "CC" 2 "ACC" 1 "AEB" 0 "Inactive";
VAL_ 383 DISC_ButtSta 1 "on" 0 "off";
VAL_ 383 SPD2ACCAct 1 "ON" 0 "OFF";
VAL_ 383 DISC_DISCTurn 1 "On" 0 "Off";
VAL_ 383 DISC_DISCTargetSpd 4095 "Invalid";
VAL_ 383 FeatArbitrSta 6 "ACCDISC" 5 "MSA" 4 "DISC" 3 "CC" 2 "ACC" 1 "AEB" 0 "Inactive";
VAL_ 383 DISC_Sta 3 "Disable" 2 "Active" 1 "Standby" 0 "Off";
VAL_ 383 CCMSA_SpdWar 1 "On" 0 "Off";
VAL_ 383 LatAccCtrl 1 "ON" 0 "OFF";
VAL_ 383 LateralCtrl 1 "ON" 0 "OFF";
VAL_ 383 SafetyCtrl 1 "ON" 0 "OFF";
VAL_ 383 SingleWhlSlipRatioCtrl 1 "ON" 0 "OFF";
VAL_ 383 VMC_VCU_CC_Crl_Sta 6 "Invalid" 5 "Error" 4 "Over Speed" 3 "Under Speed" 2 "Active" 1 "Standby" 0 "Off";
VAL_ 383 VMC_AEBCtrlAvail 1 "ON" 0 "OFF";
VAL_ 383 VMC_CCCtrlAvail 1 "ON" 0 "OFF";
VAL_ 383 VMC_MSACtrlAvail 1 "ON" 0 "OFF";
VAL_ 383 RearWhlSlipRatioCtrl 1 "ON" 0 "OFF";
VAL_ 383 FrontRearSlipRatioCtrl 1 "ON" 0 "OFF";
VAL_ 383 VMC_VCU_ACC_CtrlAvail 1 "Available" 0 "Unavailable";
VAL_ 383 VMC_VCU_AccPedal_Override 1 "Acceleration Pedal Override" 0 "No Override";
VAL_ 383 VMC_VCU_MSA_Crl_Sta 6 "Invalid" 5 "Error" 4 "Over Speed" 3 "Under Speed" 2 "Active" 1 "Standby" 0 "Off";
VAL_ 383 VMC_VCU_APSCtrlAvail_flg 1 "ON" 0 "OFF";
VAL_ 383 VMC_ACCCtrlAvail 1 "ON" 0 "OFF";
VAL_ 568 APSOpenPTG 1 "request" 0 "no request";
VAL_ 568 CAAS_Sta 4 "Shift Gear to P" 3 "Active" 2 "Enable" 1 "Disable" 0 "OFF";
VAL_ 568 APS_Req 3 "Standstill with EPB" 2 "Standstill with Brake Hold" 1 "Decel Control" 0 "No request";
VAL_ 568 APS_DecReq_A 1 "Applicable" 0 "Not Applicable";
VAL_ 568 APS_Sta_System 4 "Remote Actived" 3 "Failed" 2 "Active" 1 "Enable" 0 "Disable";
VAL_ 568 FDC_VMC_APS_V_Rq_EPS_Ctrl 1 "Valid" 0 "Invalid";
VAL_ 568 SPTG_Sta 2 "enable" 1 "disable" 0 "OFF";
VAL_ 568 SPTGDet 1 "request" 0 "no request";
VAL_ 568 FDC_VMC_APS_Rq_EPS_Ctrl 1 "Request on EPS Control" 0 "No Request on EPS Control";
VAL_ 568 FDC_RAPS_PwrReq_Cmd 4 "Invalid" 3 "Request power ON" 2 "Request power OFF" 1 "Request power Ready" 0 "No request";
VAL_ 568 FDC_RAPS_BCMLamp_Cmd 3 "Hazard lamp" 2 "Right turn lamp" 1 "Left turn lamp" 0 "Not request";
VAL_ 568 FDC_RAPS_PwrReqAvail_Sta 1 "Available" 0 "Unavailable";
VAL_ 568 FDC_RAPS_BCMLockReq_Cmd 1 "Request to lock door" 0 "Not request";
VAL_ 568 FDC_APS_CaasCtrlAvail_Sta 1 "Available" 0 "Unavailable";
VAL_ 568 FDC_APS_CaasVMCReqA_Cmd 1 "Applicable" 0 "Not Applicable";
VAL_ 568 FDC_APS_VMCReqA_Cmd 1 "Applicable" 0 "Not Applicable";
VAL_ 568 FDC_APS_ShftPosnReq_Cmd 7 "Reverse" 6 "Failure" 5 "Drive" 4 "Neutral" 2 "Park" 0 "Default";
VAL_ 568 FDC_APS_CaasActive_Sta 1 "Active" 0 "Inactive";
VAL_ 568 FDC_APS_CtrlAvail_Sta 1 "Available" 0 "Unavailable";
VAL_ 568 FDC_APS_Active_Sta 1 "Active" 0 "Inactive";
VAL_ 568 FDC_VCU_RAPSErrLv3_Flg 1 "Fault" 0 "Normal";
VAL_ 568 FDC_VCU_RAPSErrLv2_Flg 1 "Fault" 0 "Normal";
VAL_ 568 FDC_RAPS_ErrLv1_Flg 1 "Fault" 0 "Normal";
VAL_ 345 Rr_RgnPermSta 1 "Permission" 0 "Prohibition or FWD";
VAL_ 345 Fr_RgnPermSta 1 "Permission" 0 "Prohibition or RWD";
VAL_ 345 Rr_RgnDecrSta 1 "Not Decrease" 0 "Decrease or FWD";
VAL_ 345 Fr_RgnDecrSta 1 "Not Decrease" 0 "Decrease or RWD";
VAL_ 345 RgnAbnorSta 1 "Abnormal" 0 "Normal";
VAL_ 345 Rr_EDUSpdValid 1 "Invalid" 0 "Valid";
VAL_ 345 Fr_EDUSpdValid 1 "Invalid" 0 "Valid";
VAL_ 345 EquivAccPedalSWSta 1 "On" 0 "Off";
VAL_ 345 PTCS_PermSta 1 "Permission" 0 "Prohibition";
VAL_ 345 Fr_EDUAvailBrkRgnTqValid 1 "Invalid" 0 "Valid";
VAL_ 345 Rr_EDUAvailBrkRgnTqValid 1 "Invalid" 0 "Valid";
VAL_ 386 CCU_ACMaxLampSts 1 "Lamp ON" 0 "Lamp OFF";
VAL_ 386 CCU_AutoLampSts 1 "Lamp ON" 0 "Lamp OFF";
VAL_ 386 CCU_AutoMidLampSts 1 "Lamp ON" 0 "Lamp OFF";
VAL_ 386 CCU_EcoSts 1 "Lamp ON" 0 "Lamp OFF";
VAL_ 386 CCU_ACLampSts 1 "Lamp ON" 0 "Lamp OFF";
VAL_ 386 CCU_HEATMaxLampSts 1 "Lamp ON" 0 "Lamp OFF";
VAL_ 386 sigWindDirZon3St 7 "NOT Set / Reserved" 6 "All open" 5 "Face + Screen" 4 "DEFOG" 3 "Foot + Screen" 2 "Foot" 1 "Bilevel" 0 "FACE";
VAL_ 386 CCU_FrtOnOffLampSts 1 "Lamp ON" 0 "Lamp OFF";
VAL_ 386 sigWindDirZon1St 7 "NOT Set / Reserved" 6 "All open" 5 "Face + Screen" 4 "DEFOG" 3 "Foot + Screen" 2 "Foot" 1 "Bilevel" 0 "FACE";
VAL_ 386 CCU_RrOnOffLampSts 1 "Lamp ON" 0 "Lamp OFF";
VAL_ 386 sigAirIntenZon3St 15 "Invalid" 14 "Reserved" 11 "Reserved" 10 "NOT set" 9 "Level 8" 8 "Level 7" 7 "Level 6" 6 "Level 5" 5 "Level 4" 4 "Level 3" 3 "Level 2" 2 "Level 1" 1 "OFF" 0 "NO display / No request";
VAL_ 386 sigAirIntenZon1St 15 "Invalid" 14 "Reserved" 11 "Reserved" 10 "NOT set" 9 "Level 8" 8 "Level 7" 7 "Level 6" 6 "Level 5" 5 "Level 4" 4 "Level 3" 3 "Level 2" 2 "Level 1" 1 "OFF" 0 "NO display / No request";
VAL_ 386 sigDfrstSt 1 "ON" 0 "OFF";
VAL_ 386 CCU_SyncLampSts 1 "Lamp ON" 0 "Lamp OFF";
VAL_ 386 sigHvacSt 1 "ON" 0 "OFF";
VAL_ 386 sigRecircSt 1 "ON" 0 "OFF";
VAL_ 386 HPThermalRecoveryReq 1 "Request" 0 "Not Request";
VAL_ 386 EDriveMode 2 "Waste Heat Recovery" 1 "Cooling" 0 "OFF";
VAL_ 386 sigAmbAirT 255 "Invalid";
VAL_ 386 FD_RecyAuto_Cmd 7 "Invalid" 6 "reserved" 5 "reserved" 4 "100% out recycle" 3 "70% out recycle" 2 "50% out recycle" 1 "30% out recycle" 0 "0% out recycle";
VAL_ 386 CabinMode 15 "Invalid" 11 "Reserved" 10 "Cabin Deice Mode" 9 "Cabin Heating Mode 2" 8 "Cabin Heating Mode 1" 7 "Cabin Dehumidity Mode 4" 6 "Cabin Dehumidity Mode 3" 5 "Cabin Dehumidity Mode 2" 4 "Cabin Dehumidity Mode 1" 3 "Mode 1" 2 "Comp On" 1 "Comp Off" 0 "OFF";
VAL_ 386 BatteryMode 5 "Active Heating" 4 "Passive Heating" 3 "Isothermal Cycle" 2 "Passive Cooling" 1 "Active Cooling" 0 "OFF";
VAL_ 386 FD_AGS_Cmd 208 "78^Deg" 240 "90^Deg" 176 "66^Deg" 144 "54^Deg" 112 "42^Deg" 80 "30^Deg" 48 "18^Deg" 16 "6^Deg" 224 "84^Deg" 192 "72^Deg" 160 "60^Deg" 128 "48^Deg" 96 "36^Deg" 64 "24^Deg" 32 "12^Deg" 0 "0^Deg";
VAL_ 534 BCM_Buzzer_Req 1 "Request" 0 "No Request";
VAL_ 534 TailgateRemote 3 "Invalid" 2 "Handle Request" 1 "Remote Request" 0 "No Request";
VAL_ 534 RoomLampL 1 "ON" 0 "OFF";
VAL_ 534 RoomLampH 1 "ON" 0 "OFF";
VAL_ 534 DimmerEN 1 "Enable" 0 "Disable";
VAL_ 534 BCM_DoorLock_Sta 1 "Lock" 0 "Unlock";
VAL_ 534 HornCtrl 1 "ON" 0 "OFF";
VAL_ 534 LockSetting 1 "Unlock Single Door" 0 "Unlock All Door";
VAL_ 534 LTurnLP 1 "On" 0 "Off";
VAL_ 534 RTurnLP 1 "On" 0 "Off";
VAL_ 534 AntitheftSta 3 "Alarm Status" 2 "Wait for Rearm Status" 1 "Arm Status" 0 "Disarm Status";
VAL_ 534 AntiTheftSeatFold 1 "Fold" 0 "No Request";
VAL_ 534 CrashDetd 1 "Crash detected" 0 "Crash not detected";
VAL_ 534 L_APM_WdwEnable 1 "Normal" 0 "Inhibit";
VAL_ 534 RDRL 1 "On" 0 "Off";
VAL_ 534 ReverseLamp 1 "On" 0 "Off";
VAL_ 534 BrakeLamp 1 "On" 0 "Off";
VAL_ 534 LBSD 1 "On" 0 "Off";
VAL_ 534 RBSD 1 "On" 0 "Off";
VAL_ 534 Fr_FogLamp 1 "On" 0 "Off";
VAL_ 534 Rr_FogLamp 1 "On" 0 "Off";
VAL_ 534 HazardSW 1 "On" 0 "Off";
VAL_ 534 Rr_Wiper 1 "On" 0 "Off";
VAL_ 534 WiperFixMode 1 "On" 0 "Off";
VAL_ 534 WasherCtrl 3 "Undefined" 2 "Rear Washer" 1 "Front Washer" 0 "No Command";
VAL_ 534 L_Beam 1 "On" 0 "Off";
VAL_ 534 H_Beam 1 "On" 0 "Off";
VAL_ 534 PosLamp 1 "On" 0 "Off";
VAL_ 534 LDRL 1 "On" 0 "Off";
VAL_ 534 MirrorDefog 1 "On" 0 "Off";
VAL_ 534 Rr_Defog 1 "On" 0 "Off";
VAL_ 534 TrunkRel 1 "Release" 0 "Off";
VAL_ 534 TailgateHDSW 1 "Press" 0 "Release";
VAL_ 534 MirrorCtrl 3 "Undefined" 2 "Unfold" 1 "Fold" 0 "No Command";
VAL_ 534 Fr_Wiper_H 1 "On" 0 "Off";
VAL_ 534 Fr_Wiper_L 1 "On" 0 "Off";
VAL_ 534 CTDCtrl 3 "Lock All Door" 2 "Unlock All Door" 1 "Unlock Driver Door" 0 "No Command";
VAL_ 534 Fr_ChargingDoorCtrl 3 "Undefined" 2 "Lock" 1 "Unlock" 0 "No Command";
VAL_ 534 Rr_ChargingDoorCtrl 3 "Undefined" 2 "Lock" 1 "Unlock" 0 "No Command";
VAL_ 534 CTDLockSW 1 "Press" 0 "Release";
VAL_ 534 CTDUnlockSW 1 "Press" 0 "Release";
VAL_ 534 DrDoorSW 1 "Open" 0 "Close";
VAL_ 534 PsDoorSW 1 "Open" 0 "Close";
VAL_ 534 RLDoorSW 1 "Open" 0 "Close";
VAL_ 534 RRDoorSW 1 "Open" 0 "Close";
VAL_ 534 AllDoorSW 1 "Any Door Open" 0 "Close";
VAL_ 534 DoorLockIND 1 "On" 0 "Off";
VAL_ 534 HoodSW 1 "Open" 0 "Close";
VAL_ 534 Tailgate_SW 1 "Open" 0 "Close";
VAL_ 602 METER_KPH_Calcu 255 "Invalid";
VAL_ 602 METER_MPH_Calcu 255 "Invalid";
VAL_ 602 Spd_Crl_Mode 5 "invalid" 4 "ISA" 3 "LIM" 2 "CC" 1 "ACC" 0 "OFF";
VAL_ 602 Spd_Crl_Sta 1 "ON" 0 "OFF";
VAL_ 602 LEDlitWarnReq 1 "Warning request" 0 "No warning request";
VAL_ 602 Charge 1 "Disable (LED ON)" 0 "Enable (LED OFF)";
VAL_ 602 ParkBrake 1 "On" 0 "Off";
VAL_ 528 USS_Sta_RCR 1 "Checked error" 0 "Checked OK";
VAL_ 528 USS_Sta_RCL 1 "Checked error" 0 "Checked OK";
VAL_ 528 USS_Sta_FMR 1 "Checked error" 0 "Checked OK";
VAL_ 528 USS_Sta_FML 1 "Checked error" 0 "Checked OK";
VAL_ 528 USS_Sta_FLR 1 "Checked error" 0 "Checked OK";
VAL_ 528 USS_Sta_FLL 1 "Checked error" 0 "Checked OK";
VAL_ 528 USS_Sta_FCR 1 "Checked error" 0 "Checked OK";
VAL_ 528 USS_Sta_FCL 1 "Checked error" 0 "Checked OK";
VAL_ 528 PAS_Sta_F_Sys 1 "Faliure" 0 "No Faliure";
VAL_ 528 PAS_Mod_Operation 3 "UDS" 2 "FUDS" 1 "RUDS" 0 "Function OFF";
VAL_ 528 USS_Sta_RMR 1 "Checked error" 0 "Checked OK";
VAL_ 528 USS_Sta_RML 1 "Checked error" 0 "Checked OK";
VAL_ 528 USS_Sta_RLR 1 "Checked error" 0 "Checked OK";
VAL_ 528 USS_Sta_RLL 1 "Checked error" 0 "Checked OK";
VAL_ 528 PAS_A_FML 4 "level 4 (Far distance)" 3 "level 3" 2 "level 2" 1 "level 1 (Near distance)" 0 "No signal";
VAL_ 528 PAS_A_FCR 4 "level 4 (Far distance)" 3 "level 3" 2 "level 2" 1 "level 1 (Near distance)" 0 "No signal";
VAL_ 528 PAS_A_RCL 4 "level 4 (Far distance)" 3 "level 3" 2 "level 2" 1 "level 1 (Near distance)" 0 "No signal";
VAL_ 528 PAS_A_FMR 4 "level 4 (Far distance)" 3 "level 3" 2 "level 2" 1 "level 1 (Near distance)" 0 "No signal";
VAL_ 528 PAS_A_RML 4 "level 4 (Far distance)" 3 "level 3" 2 "level 2" 1 "level 1 (Near distance)" 0 "No signal";
VAL_ 528 PAS_A_RCR 4 "level 4 (Far distance)" 3 "level 3" 2 "level 2" 1 "level 1 (Near distance)" 0 "No signal";
VAL_ 528 PAS_SNSR_Layout 7 "PAS_R2" 6 "PAS_R2F2" 5 "PAS_R4" 4 "PAS_F2R4" 3 "PAS_F4R4" 2 "APA" 1 "APS" 0 "Nomassage";
VAL_ 528 PAS_A_RMR 4 "level 4 (Far distance)" 3 "level 3" 2 "level 2" 1 "level 1 (Near distance)" 0 "No signal";
VAL_ 528 PAS_D_FCL 255 "FarDistance" 150 "Max" 0 "Min";
VAL_ 528 PAS_D_FCR 255 "FarDistance" 150 "Max" 0 "Min";
VAL_ 528 PAS_D_FML 255 "FarDistance" 150 "Max" 0 "Min";
VAL_ 528 PAS_D_FMR 255 "FarDistance" 150 "Max" 0 "Min";
VAL_ 528 APS_ExitCondition 51 "ENUM_EXC_OSPARK" 50 "ENUM_EXC_DCTOOFARSlOTFIND" 49 "ENUM_EXC_TO4OBSTFRONT" 48 "ENUM_EXC_TO4OBSTREAR" 46 "ENUM_EXC_OCDRIVERINTERF" 45 "ENUM_EXC_OCPPSTOOSMALL" 44 "ENUM_EXC_OCDOORSOPEN" 43 "ENUM_EXC_OCSWITCHOFFAPA" 42 "ENUM_EXC_OCSWITCHOFFPA" 41 "ENUM_EXC_OCWRONGDIR" 40 "ENUM_EXC_OTEPSERROR" 39 "ENUM_EXC_OTEVCUERROR" 38 "ENUM_EXC_OTBRAKEERROR" 37 "ENUM_EXC_OTGEARERROR" 36 "ENUM_EXC_OTEPBERROR" 35 "ENUM_EXC_OTCANERROR" 34 "ENUM_EXC_OTAPAERROR" 33 "ENUM_EXC_OTSENSORERROR" 32 "ENUM_EXC_OTOEMERROR" 81 "ENUM_EXC_OSSCA" 80 "ENUM_EXC_OSSCAWARNING" 79 "ENUM_EXC_DCTOOFARSCA" 77 "ENUM_EXC_OCSCADOORSOPEN" 76 "ENUM_EXC_OCSCASWITCHOFFAPA" 75 "ENUM_EXC_OCSCASWITCHOFFPA" 74 "ENUM_EXC_OCSCAWRONGDIR" 73 "ENUM_EXC_OTSCACAMERAERROR" 72 "ENUM_EXC_OTSCAEPSERROR" 71 "ENUM_EXC_OTSCAEVCUERROR" 70 "ENUM_EXC_OTSCABRAKEERROR" 69 "ENUM_EXC_OTSCAGEARERROR" 68 "ENUM_EXC_OTSCAEPBERROR" 131 "ENUM_EXC_TO4STANDING" 67 "ENUM_EXC_OTSCACANERROR" 130 "ENUM_EXC_TO4STANDSTILL" 66 "ENUM_EXC_OTSCAAPAERROR" 129 "ENUM_EXC_OCGEARCOUNT" 65 "ENUM_EXC_OTSCASENSORERROR" 64 "ENUM_EXC_OTSCAOEMERROR" 0 "ENUM_EXC_NOERROR";
VAL_ 528 PAS_D_RCL 255 "FarDistance" 150 "Max" 0 "Min";
VAL_ 528 PAS_D_RCR 255 "FarDistance" 150 "Max" 0 "Min";
VAL_ 528 PAS_D_RML 255 "FarDistance" 150 "Max" 0 "Min";
VAL_ 528 PAS_D_RMR 255 "FarDistance" 150 "Max" 0 "Min";
VAL_ 528 APS_RQ_Display 48 "APS Cancelled because ABS or TCS active" 47 "APS Cancelled because the slope is too steep" 46 "APS Cancelled because Tailgate is opened" 45 "APS Cancelled because Hood is opened" 44 "APS Cancelled because gear position is wrong" 43 "APS Cancelled because POWER is not ready" 42 "Please make sure the doors are closed and the seat belts are fastened." 41 "APS Cancelled because IVI or AVM is not ready" 40 "Driver seat belt is not fastened" 39 "Operation Timeout 2 min Please take over the vehicle" 38 "Operation Timeout 6 min Please take over the vehicle" 37 "Operation Timeout 1 min Please take over the vehicle" 36 "VCU failed Please take over steering" 35 "APS Cancelled because driver enable the EPB" 34 "APS Cancelled because driver intervenes the acceleration pedal" 33 "APS Cancelled because driver Intervention gear Please take over steering" 32 "APS Cancelled because driver Intervention brake Please take over steering" 31 "APS Cancelled because driver Intervention steering Please take over steering" 30 "APS Cancelled by driver" 29 "APS Cancelled because found the unknow object Please take over steering" 28 "APS Cancelled because the door is opened Please take over steering" 27 "The gear is changing to R-gear" 26 "The gear is changing to D-gear" 25 "Vehicle moving backward" 24 "Vehicle moving forward" 23 "APS System Error Please take over steering" 22 "Steering assistant failed Please take over steering" 21 "ESC failed Please take over steering" 20 "Auto parking assistant active Please check around" 19 "Shift to P gear now" 18 "Parking Slot Undersize Please take over steering" 17 "Operation Timeout Please take over the vehicle" 16 "APS Cancelled Please take over the vehicle" 15 "APS Cancelled because the speed is too fast" 14 "Stop and ready for auto parking" 13 "Please drive forward" 12 "Vehicle stop" 11 "Parking achieved" 10 "Parking out Cancelled because the slot is too small" 9 "Obstacles appear on the way of driving" 8 "The left side perpendicular parking slot be found" 7 "The left side parallel parking slot be found" 6 "The right side perpendicular parking slot be found" 5 "The right side parallel parking slot be found" 4 "Searching for perpendicular parking slot on the left side" 3 "Searching for parallel parking slot on the left side" 2 "Searching for perpendicular parking slot on the right side" 1 "Searching for parallel parking slot on the right side" 0 "No message";
VAL_ 528 PAS_A_FCL 4 "level 4 (Far distance)" 3 "level 3" 2 "level 2" 1 "level 1 (Near distance)" 0 "No signal";
VAL_ 528 PAS_Chime 9 "APS change gear warning" 8 "R_USS Obstacle warning level 3" 7 "R_USS Obstacle warning level 2" 6 "R_USS Obstacle warning level 1" 5 "F_USS Obstacle warning level 3" 4 "F_USS Obstacle warning level 2" 3 "F_USS Obstacle warning level 1" 2 "PAS and APS check fault warning" 1 "PAS and APS check normal warning" 0 "No message";
VAL_ 360 eBST_AmberWnlmpSta 1 "On" 0 "Off";
VAL_ 360 eBST_RedWnlmpSta 1 "On" 0 "Off";
VAL_ 360 eBST_BeepReq 1 "Request" 0 "No Request";
VAL_ 360 LowBrakeFluid_Sta 1 "Low" 0 "Normal";
VAL_ 119 FDC_VMC_RWS_Actv_Sta 3 "Reseve" 2 "Reseve" 1 "Active" 0 "Inactive";
VAL_ 119 FDC_VMC_RWS_Dfctv_Sta 0 "Default";
VAL_ 119 FDC_VMC_SteerFaultReq_Cmd 0 "Default";
VAL_ 575 Rr_TMSpd 65535 "Invalid";
VAL_ 575 Fr_TMSpd 65535 "Invalid";
VAL_ 575 BMS_READY 1 "Ready" 0 "Not ready";
VAL_ 1314 NM_OCS_ERROR_State 8 "BUS OFF_L2" 4 "BUS OFF_L1" 2 "ERROR PASSIVE" 1 "ERROR ACTIVE" 0 "Inactive";
VAL_ 1314 NM_OCS_Active_WU 1 "Node has woken up the network (active Wakeup)" 0 "Node has not woken up the network (passive wakeup)";
VAL_ 1314 NM_OCS_CSB 1 "Start of synchronized shutdown is requested by main coordinator" 0 "Start of synchronized shutdown is not requested by main coordinator";
VAL_ 1314 NM_OCS_PNI 1 "NM PDU contains Partial Network request information" 0 "NM PDU contains no Partial Network request information";
VAL_ 1314 NM_OCS_Rpt_Msg_Req 1 "Repeat Message State requested" 0 "Repeat Message State not requested";
VAL_ 1173 ESC_SW_Cmd 3 "Invaild" 2 "Undefined" 1 "Press" 0 "Release";
VAL_ 1173 Roll_Mode_SW_Cmd 3 "Invaild" 2 "Undefined" 1 "Press" 0 "Release";
VAL_ 1173 TCS_SW_Cmd 3 "Invaild" 2 "Undefined" 1 "Press" 0 "Release";
VAL_ 1173 Roll_Eng_Mode 1 "on" 0 "off";
